VERSION "HNNBNNNYNNNNNNNNNNNNNNNNNNNNNNNNNNNNNNNNNN/4/%%%/4/'%**4NNN///"

NS_ :

BS_:

BU_: Airbag Allrad_Haldex BAP_Tester DCC_Gen3 EBKV_MQBW ESC_MQBW Gateway_Max Lenkhilfe_REPS

BO_ 333 ACC_18: 32 Gateway_Max
 SG_ ACC_18_CRC : 0|8@1+ (1,0) [0|255] ""  ESC_MQBW
 SG_ ACC_18_BZ : 8|4@1+ (1,0) [0|15] ""  ESC_MQBW
 SG_ ACC_limitierte_Anfahrdyn : 12|1@1+ (1.0,0.0) [0.0|1] ""  Vector__XXX
 SG_ ACC_nachtr_Stopp_Anf : 13|1@1+ (1.0,0.0) [0.0|1] ""  Vector__XXX
 SG_ ACC_DynErhoehung : 14|1@1+ (1.0,0.0) [0.0|1] ""  Vector__XXX
 SG_ ACC_Freilaufstrategie_TSK : 15|1@1+ (1.0,0.0) [0.0|1] ""  Vector__XXX
 SG_ ACC_zul_Regelabw_unten : 16|6@1+ (0.024,0) [0.000|1.512] "Unit_MeterPerSeconSquar"  Vector__XXX
 SG_ ACC_StartStopp_Info : 22|2@1+ (1.0,0.0) [0.0|3] ""  Vector__XXX
 SG_ ACC_Sollbeschleunigung_02 : 24|11@1+ (0.005,-7.22) [-7.220|3.005] "Unit_MeterPerSeconSquar"  Vector__XXX
 SG_ ACC_zul_Regelabw_oben : 35|5@1+ (0.0625,0) [0.0000|1.9375] "Unit_MeterPerSeconSquar"  Vector__XXX
 SG_ ACC_neg_Sollbeschl_Grad_02 : 40|8@1+ (0.05,0) [0.00|12.75] "Unit_MeterPerCubicSecon"  Vector__XXX
 SG_ ACC_pos_Sollbeschl_Grad_02 : 48|8@1+ (0.05,0) [0.00|12.75] "Unit_MeterPerCubicSecon"  Vector__XXX
 SG_ ACC_Anfahren : 56|1@1+ (1.0,0.0) [0.0|1] ""  Vector__XXX
 SG_ ACC_Anhalten : 57|1@1+ (1.0,0.0) [0.0|1] ""  Vector__XXX
 SG_ ACC_Typ : 58|2@1+ (1.0,0.0) [0.0|3] ""  Vector__XXX
 SG_ ACC_Status_ACC : 60|3@1+ (1.0,0.0) [0.0|7] ""  Airbag,ESC_MQBW
 SG_ ACC_Minimale_Bremsung : 63|1@1+ (1.0,0.0) [0.0|1] ""  Vector__XXX
 SG_ ACC_Anhalteweg : 64|11@1+ (0.01,0) [0.00|20.45] "Unit_Meter"  ESC_MQBW
 SG_ ACC_Boost : 75|1@1+ (1.0,0.0) [0.0|1] ""  Vector__XXX
 SG_ ACC_Freilauf_Anf : 76|1@1+ (1.0,0.0) [0.0|1] ""  Vector__XXX
 SG_ ACC_Anforderung_HMS : 77|3@1+ (1.0,0.0) [0.0|7] ""  ESC_MQBW
 SG_ ACC_Folgebeschl : 80|8@1+ (0.03,-4.6) [-4.60|2.99] "Unit_MeterPerSeconSquar"  Vector__XXX
 SG_ ACC_Freilauf_Info : 88|2@1+ (1.0,0.0) [0.0|3] ""  Vector__XXX
 SG_ ACC_Tempolimitassistent_Ein : 90|1@1+ (1.0,0.0) [0.0|1] ""  Vector__XXX
 SG_ ACC_FoD_Status : 91|2@1+ (1.0,0.0) [0.0|3] ""  Vector__XXX
 SG_ ACC_Blindheit_erkannt : 93|1@1+ (1.0,0.0) [0.0|1] ""  Vector__XXX
 SG_ ACC_Verkehrssinn : 94|2@1+ (1.0,0.0) [0.0|3] ""  Vector__XXX
 SG_ ACC_relev_Nichtverfuegbarkeit : 96|1@1+ (1.0,0.0) [0.0|1] ""  Vector__XXX
 SG_ ACC_relevanter_Fehler : 97|1@1+ (1.0,0.0) [0.0|1] ""  Vector__XXX
 SG_ ACC_TA_Kurve_Abstand : 98|6@1+ (5,0) [0|300] "Unit_Meter"  Vector__XXX
 SG_ ACC_TA_Kurve_vDelta : 104|4@1+ (5,0) [0|50] "Unit_KiloMeterPerHour"  Vector__XXX
 SG_ RDR_VBEG_Anforderung : 108|5@1+ (1,4) [5|35] "Unit_KiloMeterPerHour"  Vector__XXX
 SG_ ACC_Abbiegewunsch : 113|2@1+ (1.0,0.0) [0.0|3] ""  Vector__XXX
 SG_ ACC_Abbiegewunsch_Abstand : 115|9@1+ (1,0) [0|510] "Unit_Meter"  Vector__XXX
 SG_ MPPmod_1_Segment : 208|6@1+ (1,0) [2|63] ""  Vector__XXX
 SG_ MPPmod_2_Segment : 214|6@1+ (1,0) [2|63] ""  Vector__XXX
 SG_ MPPmod_3_Segment : 220|6@1+ (1,0) [2|63] ""  Vector__XXX
 SG_ MPPmod_4_Segment : 226|6@1+ (1,0) [2|63] ""  Vector__XXX
 SG_ vESC_Verz_Anf : 232|4@1+ (0.5,0) [0.0|3.5] "Unit_MeterPerSeconSquar"  Vector__XXX
 SG_ RDR_v_ueber_Grund : 236|12@1+ (0.1,0) [0.0|409.0] "Unit_KiloMeterPerHour"  ESC_MQBW
 SG_ RDR_v_ueber_Grund_Genauigkeit : 248|6@1+ (0.1,0) [0.0|6.0] "Unit_KiloMeterPerHour"  ESC_MQBW
 SG_ RDR_v_ueber_Grund_Fahrtrichtung : 254|2@1+ (1.0,0.0) [0.0|3] ""  ESC_MQBW

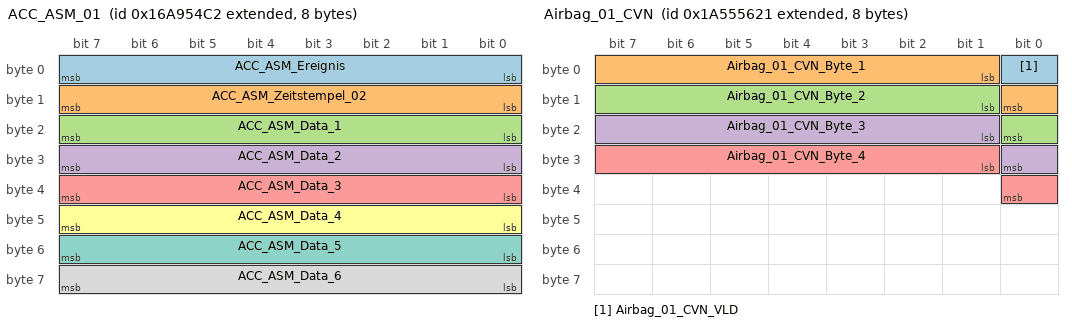
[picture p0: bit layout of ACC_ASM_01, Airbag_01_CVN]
BO_ 2527679682 ACC_ASM_01: 8 Gateway_Max
 SG_ ACC_ASM_Ereignis : 0|8@1+ (1,0) [1|254] ""  Airbag
 SG_ ACC_ASM_Zeitstempel_02 : 8|8@1+ (0.04,0) [0.00|10.16] "Unit_Secon"  Airbag
 SG_ ACC_ASM_Data_1 : 16|8@1+ (1,0) [0|255] ""  Airbag
 SG_ ACC_ASM_Data_2 : 24|8@1+ (1,0) [0|255] ""  Airbag
 SG_ ACC_ASM_Data_3 : 32|8@1+ (1,0) [0|255] ""  Airbag
 SG_ ACC_ASM_Data_4 : 40|8@1+ (1,0) [0|255] ""  Airbag
 SG_ ACC_ASM_Data_5 : 48|8@1+ (1,0) [0|255] ""  Airbag
 SG_ ACC_ASM_Data_6 : 56|8@1+ (1,0) [0|255] ""  Airbag

BO_ 64 Airbag_01: 8 Airbag
 SG_ Airbag_01_CRC : 0|8@1+ (1,0) [0|255] ""  ESC_MQBW,Gateway_Max
 SG_ Airbag_01_BZ : 8|4@1+ (1,0) [0|15] ""  ESC_MQBW,Gateway_Max
 SG_ AB_RGS_Anst : 12|4@1+ (1.0,0.0) [0.0|15] ""  Gateway_Max
 SG_ AB_Front_Crash : 16|1@1+ (1.0,0.0) [0.0|1] ""  ESC_MQBW,Gateway_Max
 SG_ AB_Heck_Crash : 17|1@1+ (1.0,0.0) [0.0|1] ""  ESC_MQBW,Gateway_Max
 SG_ AB_SF_Crash : 18|1@1+ (1.0,0.0) [0.0|1] ""  ESC_MQBW,Gateway_Max
 SG_ AB_SB_Crash : 19|1@1+ (1.0,0.0) [0.0|1] ""  ESC_MQBW,Gateway_Max
 SG_ AB_Rollover_Crash : 20|1@1+ (1.0,0.0) [0.0|1] ""  ESC_MQBW,Gateway_Max
 SG_ AB_Crash_Int : 21|3@1+ (1.0,0.0) [0.0|7] ""  EBKV_MQBW,ESC_MQBW,Gateway_Max
 SG_ AB_Lampe : 24|1@1+ (1.0,0.0) [0.0|1] ""  Gateway_Max
 SG_ AB_Deaktiviert : 25|1@1+ (1.0,0.0) [0.0|1] ""  Gateway_Max
 SG_ AB_VB_deaktiviert : 26|1@1+ (1.0,0.0) [0.0|1] ""  Gateway_Max
 SG_ AB_Systemfehler : 27|1@1+ (1.0,0.0) [0.0|1] ""  Gateway_Max
 SG_ AB_Diagnose : 28|1@1+ (1.0,0.0) [0.0|1] ""  Gateway_Max
 SG_ AB_Stellgliedtest : 29|1@1+ (1.0,0.0) [0.0|1] ""  Gateway_Max,Lenkhilfe_REPS
 SG_ AB_Erh_Auf_VB : 30|2@1+ (1.0,0.0) [0.0|3] ""  Gateway_Max
 SG_ AB_Gurtwarn_VF : 32|1@1+ (1.0,0.0) [0.0|1] ""  Gateway_Max
 SG_ AB_Gurtwarn_VB : 33|1@1+ (1.0,0.0) [0.0|1] ""  Gateway_Max
 SG_ AB_Anzeige_Fussg : 34|2@1+ (1.0,0.0) [0.0|3] ""  Gateway_Max
 SG_ AB_Texte_AKS : 36|2@1+ (1.0,0.0) [0.0|3] ""  Gateway_Max
 SG_ AB_PAO_Leuchte_Anf : 38|1@1+ (1.0,0.0) [0.0|1] ""  Gateway_Max
 SG_ AB_MKB_gueltig : 39|1@1+ (1.0,0.0) [0.0|1] ""  Gateway_Max
 SG_ AB_MKB_Anforderung : 40|1@1+ (1.0,0.0) [0.0|1] ""  ESC_MQBW,Gateway_Max
 SG_ AB_Versorgungsspannung : 41|1@1+ (1.0,0.0) [0.0|1] ""  Gateway_Max
 SG_ AB_Deaktivierung_HV : 42|3@1+ (1.0,0.0) [0.0|7] ""  Gateway_Max
 SG_ AB_EDR_Trigger : 45|2@1+ (1.0,0.0) [0.0|3] ""  Gateway_Max
 SG_ AB_Belegung_VF : 47|2@1+ (1.0,0.0) [0.0|3] ""  Gateway_Max
 SG_ AB_Gurtschloss_FA_ext : 49|3@1+ (1.0,0.0) [0.0|7] ""  ESC_MQBW,Gateway_Max
 SG_ AB_Gurtschloss_FA_ext_aktiv : 52|1@1+ (1.0,0.0) [0.0|1] ""  Gateway_Max
 SG_ AB_eCS_Error : 53|1@1+ (1.0,0.0) [0.0|1] ""  Gateway_Max
 SG_ ASM_Masterzeit_02 : 56|8@1+ (0.04,0) [0.00|10.16] "Unit_Secon"  ESC_MQBW,Gateway_Max,Lenkhilfe_REPS

BO_ 2589283872 Airbag_01_CALID: 16 Airbag
 SG_ Airbag_01_CALID_Index_01 : 0|8@1+ (1,0) [0|255] "Unit_None"  ESC_MQBW
 SG_ Airbag_01_CALID_Index_02 : 8|8@1+ (1,0) [0|255] "Unit_None"  ESC_MQBW
 SG_ Airbag_01_CALID_Index_03 : 16|8@1+ (1,0) [0|255] "Unit_None"  ESC_MQBW
 SG_ Airbag_01_CALID_Index_04 : 24|8@1+ (1,0) [0|255] "Unit_None"  ESC_MQBW
 SG_ Airbag_01_CALID_Index_05 : 32|8@1+ (1,0) [0|255] "Unit_None"  ESC_MQBW
 SG_ Airbag_01_CALID_Index_06 : 40|8@1+ (1,0) [0|255] "Unit_None"  ESC_MQBW
 SG_ Airbag_01_CALID_Index_07 : 48|8@1+ (1,0) [0|255] "Unit_None"  ESC_MQBW
 SG_ Airbag_01_CALID_Index_08 : 56|8@1+ (1,0) [0|255] "Unit_None"  ESC_MQBW
 SG_ Airbag_01_CALID_Index_09 : 64|8@1+ (1,0) [0|255] "Unit_None"  ESC_MQBW
 SG_ Airbag_01_CALID_Index_10 : 72|8@1+ (1,0) [0|255] "Unit_None"  ESC_MQBW
 SG_ Airbag_01_CALID_Index_11 : 80|8@1+ (1,0) [0|255] "Unit_None"  ESC_MQBW
 SG_ Airbag_01_CALID_Index_12 : 88|8@1+ (1,0) [0|255] "Unit_None"  ESC_MQBW
 SG_ Airbag_01_CALID_Index_13 : 96|8@1+ (1,0) [0|255] "Unit_None"  ESC_MQBW
 SG_ Airbag_01_CALID_Index_14 : 104|8@1+ (1,0) [0|255] "Unit_None"  ESC_MQBW
 SG_ Airbag_01_CALID_Index_15 : 112|8@1+ (1,0) [0|255] "Unit_None"  ESC_MQBW
 SG_ Airbag_01_CALID_Index_16 : 120|8@1+ (1,0) [0|255] "Unit_None"  ESC_MQBW

BO_ 2589283873 Airbag_01_CVN: 8 Airbag
 SG_ Airbag_01_CVN_VLD : 0|1@1+ (1.0,0.0) [0.0|1] ""  ESC_MQBW
 SG_ Airbag_01_CVN_Byte_1 : 1|8@1+ (1,0) [0|255] "Unit_None"  ESC_MQBW
 SG_ Airbag_01_CVN_Byte_2 : 9|8@1+ (1,0) [0|255] "Unit_None"  ESC_MQBW
 SG_ Airbag_01_CVN_Byte_3 : 17|8@1+ (1,0) [0|255] "Unit_None"  ESC_MQBW
 SG_ Airbag_01_CVN_Byte_4 : 25|8@1+ (1,0) [0|255] "Unit_None"  ESC_MQBW

BO_ 1312 Airbag_02: 8 Airbag
 SG_ Airbag_02_CRC : 0|8@1+ (1,0) [0|255] ""  ESC_MQBW,Gateway_Max
 SG_ Airbag_02_BZ : 8|4@1+ (1,0) [0|15] ""  ESC_MQBW,Gateway_Max
 SG_ LoGeWa_Event_Kombiwarnung : 12|4@1+ (1.0,0.0) [0.0|15] ""  Gateway_Max
 SG_ AB_Anforderung_eCall : 16|1@1+ (1.0,0.0) [0.0|1] ""  Gateway_Max
 SG_ AB_Anprall_Seite_Beifahrer : 17|1@1+ (1.0,0.0) [0.0|1] ""  Gateway_Max
 SG_ AB_Anprall_Rollover : 18|1@1+ (1.0,0.0) [0.0|1] ""  Gateway_Max
 SG_ AB_Anprall_FGS : 19|1@1+ (1.0,0.0) [0.0|1] ""  Gateway_Max
 SG_ AB_Anprall_Front_Beifahrer : 20|1@1+ (1.0,0.0) [0.0|1] ""  Gateway_Max
 SG_ AB_Anprall_Front_Fahrer : 21|1@1+ (1.0,0.0) [0.0|1] ""  Gateway_Max
 SG_ AB_Anprall_Heck_Beifahrer : 22|1@1+ (1.0,0.0) [0.0|1] ""  Gateway_Max
 SG_ AB_Anprall_Heck_Fahrer : 23|1@1+ (1.0,0.0) [0.0|1] ""  Gateway_Max
 SG_ AB_Wickelklappung_Reihe2_MI : 24|2@1+ (1.0,0.0) [0.0|3] ""  Gateway_Max
 SG_ AB_Belegung_VB : 26|2@1+ (1.0,0.0) [0.0|3] ""  Gateway_Max
 SG_ AB_Abschaltanf_SIH_BF : 28|1@1+ (1.0,0.0) [0.0|1] ""  Gateway_Max
 SG_ AB_Anprall_Seite_Fahrer : 29|1@1+ (1.0,0.0) [0.0|1] ""  Gateway_Max
 SG_ SC_PAO_Schriftzug_Anf : 30|2@1+ (1.0,0.0) [0.0|3] ""  Gateway_Max
 SG_ SC_PAO_ON_Anf : 32|2@1+ (1.0,0.0) [0.0|3] ""  Gateway_Max
 SG_ SC_PAO_OFF_Anf : 34|2@1+ (1.0,0.0) [0.0|3] ""  Gateway_Max
 SG_ AB_Crashschwere : 36|3@1+ (1.0,0.0) [0.0|7] ""  Gateway_Max
 SG_ AB_Anforderung_USM : 39|1@1+ (1.0,0.0) [0.0|1] ""  Gateway_Max
 SG_ AB_Gurtschloss_FA : 40|2@1+ (1.0,0.0) [0.0|3] ""  ESC_MQBW,Gateway_Max
 SG_ AB_Gurtschloss_BF : 42|2@1+ (1.0,0.0) [0.0|3] ""  Gateway_Max
 SG_ AB_Gurtschloss_Reihe2_FA : 44|2@1+ (1.0,0.0) [0.0|3] ""  Gateway_Max
 SG_ AB_Gurtschloss_Reihe2_MI : 46|2@1+ (1.0,0.0) [0.0|3] ""  Gateway_Max
 SG_ AB_Gurtschloss_Reihe2_BF : 48|2@1+ (1.0,0.0) [0.0|3] ""  Gateway_Max
 SG_ AB_Gurtschloss_Reihe3_FA : 50|2@1+ (1.0,0.0) [0.0|3] ""  Gateway_Max
 SG_ AB_Gurtschloss_Reihe3_MI : 52|2@1+ (1.0,0.0) [0.0|3] ""  Gateway_Max
 SG_ AB_Gurtschloss_Reihe3_BF : 54|2@1+ (1.0,0.0) [0.0|3] ""  Gateway_Max
 SG_ AB_Sitzpos_Sens_FA : 56|2@1+ (1.0,0.0) [0.0|3] ""  ESC_MQBW,Gateway_Max
 SG_ AB_Sitzpos_Sens_BF : 58|2@1+ (1.0,0.0) [0.0|3] ""  Gateway_Max
 SG_ AB_Wickelklappung_Reihe2_BF : 60|2@1+ (1.0,0.0) [0.0|3] ""  Gateway_Max
 SG_ AB_Wickelklappung_Reihe2_FA : 62|2@1+ (1.0,0.0) [0.0|3] ""  Gateway_Max

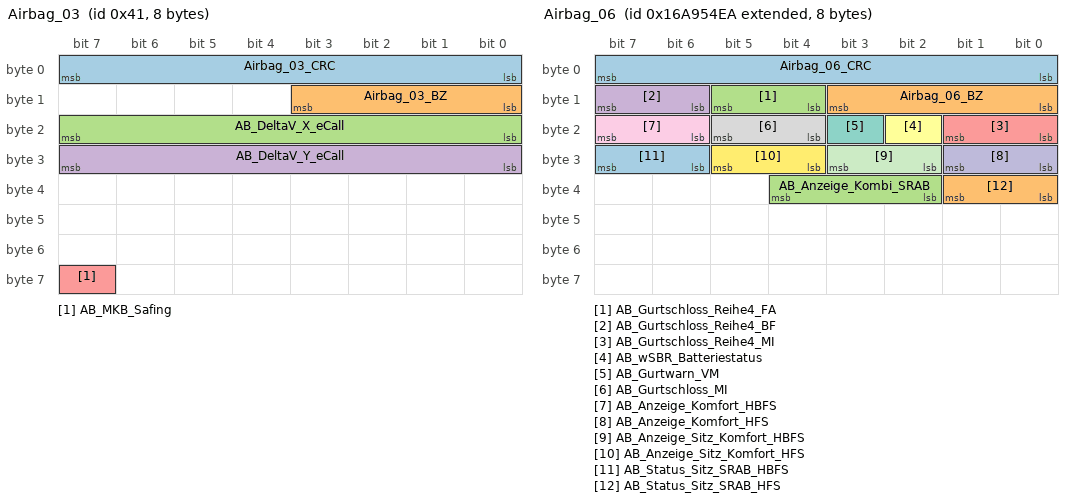
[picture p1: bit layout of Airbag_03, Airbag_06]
BO_ 65 Airbag_03: 8 Airbag
 SG_ Airbag_03_CRC : 0|8@1+ (1,0) [0|255] ""  ESC_MQBW,Gateway_Max
 SG_ Airbag_03_BZ : 8|4@1+ (1,0) [0|15] ""  ESC_MQBW,Gateway_Max
 SG_ AB_DeltaV_X_eCall : 16|8@1+ (1,-128) [-126|126] "Unit_KiloMeterPerHour"  Gateway_Max
 SG_ AB_DeltaV_Y_eCall : 24|8@1+ (1,-128) [-126|126] "Unit_KiloMeterPerHour"  Gateway_Max
 SG_ AB_MKB_Safing : 63|1@1+ (1.0,0.0) [0.0|1] ""  ESC_MQBW,Gateway_Max

BO_ 1349 Airbag_04: 8 Airbag
 SG_ Airbag_04_CRC : 0|8@1+ (1,0) [0|255] ""  Gateway_Max
 SG_ Airbag_04_BZ : 8|4@1+ (1,0) [0|15] ""  Gateway_Max
 SG_ AB_Anprall_Front : 12|1@1+ (1.0,0.0) [0.0|1] ""  Gateway_Max
 SG_ AB_Anprall_Heck : 13|1@1+ (1.0,0.0) [0.0|1] ""  Gateway_Max
 SG_ AB_Gurtwarn_Reihe4_FA : 14|2@1+ (1.0,0.0) [0.0|3] ""  Gateway_Max
 SG_ AB_Gurtwarn_Reihe4_BF : 16|2@1+ (1.0,0.0) [0.0|3] ""  Gateway_Max
 SG_ AB_Gurtwarn_Reihe4_MI : 18|2@1+ (1.0,0.0) [0.0|3] ""  Gateway_Max
 SG_ AB_Gurtwarn_Reihe2_FA : 20|2@1+ (1.0,0.0) [0.0|3] ""  Gateway_Max
 SG_ AB_Gurtwarn_Reihe2_BF : 22|2@1+ (1.0,0.0) [0.0|3] ""  Gateway_Max
 SG_ AbstWarn_MV_FAS_Fkt_Status : 24|2@1+ (1.0,0.0) [0.0|3] ""  Gateway_Max
 SG_ WarnBrems_Charisma_Status : 26|2@1+ (1.0,0.0) [0.0|3] ""  Gateway_Max
 SG_ WarnBrems_Charisma_FahrPr : 28|4@1+ (1.0,0.0) [0.0|15] ""  Gateway_Max
 SG_ AB_Gurtwarn_Reihe2_MI : 32|2@1+ (1.0,0.0) [0.0|3] ""  Gateway_Max
 SG_ AB_Gurtwarn_Reihe3_FA : 34|2@1+ (1.0,0.0) [0.0|3] ""  Gateway_Max
 SG_ AB_Gurtwarn_Reihe3_MI : 36|2@1+ (1.0,0.0) [0.0|3] ""  Gateway_Max
 SG_ AB_Gurtwarn_Reihe3_BF : 38|2@1+ (1.0,0.0) [0.0|3] ""  Gateway_Max
 SG_ LGI_FAS_Fkt_Status : 40|2@1+ (1.0,0.0) [0.0|3] ""  Gateway_Max
 SG_ PreCrash_FAS_Fkt_Status : 42|3@1+ (1.0,0.0) [0.0|7] ""  Gateway_Max
 SG_ AB_Belegung_VF_ext : 45|3@1+ (1.0,0.0) [0.0|7] ""  Gateway_Max
 SG_ AB_SBR_hinten_verbau : 48|2@1+ (1.0,0.0) [0.0|3] ""  Gateway_Max
 SG_ AB_Belegung_VF_ext_aktiv : 50|1@1+ (1.0,0.0) [0.0|1] ""  Gateway_Max
 SG_ AWV_Einstellung_System_ASG : 51|1@1+ (1.0,0.0) [0.0|1] ""  Gateway_Max
 SG_ AWV_Einstellung_Warnung_ASG : 52|3@1+ (1.0,0.0) [0.0|7] ""  Gateway_Max
 SG_ SC_PreSense_Modus_Warnung_NV : 55|3@1+ (1.0,0.0) [0.0|7] ""  Gateway_Max
 SG_ SC_PreSense_Modus_Warnung_MV : 58|3@1+ (1.0,0.0) [0.0|7] ""  Gateway_Max
 SG_ SC_PreSense_Modus_System_MV : 61|1@1+ (1.0,0.0) [0.0|1] ""  Gateway_Max
 SG_ SC_PreSense_Modus_System_NV : 62|1@1+ (1.0,0.0) [0.0|1] ""  Gateway_Max
 SG_ SC_PreSense_Modus_System_KAS : 63|1@1+ (1.0,0.0) [0.0|1] ""  Gateway_Max

BO_ 2527679722 Airbag_06: 8 Airbag
 SG_ Airbag_06_CRC : 0|8@1+ (1,0) [0|255] ""  Gateway_Max
 SG_ Airbag_06_BZ : 8|4@1+ (1,0) [0|15] ""  Gateway_Max
 SG_ AB_Gurtschloss_Reihe4_FA : 12|2@1+ (1.0,0.0) [0.0|3] ""  Gateway_Max
 SG_ AB_Gurtschloss_Reihe4_BF : 14|2@1+ (1.0,0.0) [0.0|3] ""  Gateway_Max
 SG_ AB_Gurtschloss_Reihe4_MI : 16|2@1+ (1.0,0.0) [0.0|3] ""  Gateway_Max
 SG_ AB_wSBR_Batteriestatus : 18|1@1+ (1.0,0.0) [0.0|1] ""  Gateway_Max
 SG_ AB_Gurtwarn_VM : 19|1@1+ (1.0,0.0) [0.0|1] ""  Gateway_Max
 SG_ AB_Gurtschloss_MI : 20|2@1+ (1.0,0.0) [0.0|3] ""  Gateway_Max
 SG_ AB_Anzeige_Komfort_HBFS : 22|2@1+ (1.0,0.0) [0.0|3] ""  Gateway_Max
 SG_ AB_Anzeige_Komfort_HFS : 24|2@1+ (1.0,0.0) [0.0|3] ""  Gateway_Max
 SG_ AB_Anzeige_Sitz_Komfort_HBFS : 26|2@1+ (1.0,0.0) [0.0|3] ""  Gateway_Max
 SG_ AB_Anzeige_Sitz_Komfort_HFS : 28|2@1+ (1.0,0.0) [0.0|3] ""  Gateway_Max
 SG_ AB_Status_Sitz_SRAB_HBFS : 30|2@1+ (1.0,0.0) [0.0|3] ""  Gateway_Max
 SG_ AB_Status_Sitz_SRAB_HFS : 32|2@1+ (1.0,0.0) [0.0|3] ""  Gateway_Max
 SG_ AB_Anzeige_Kombi_SRAB : 34|3@1+ (1.0,0.0) [0.0|7] ""  Gateway_Max

BO_ 63 Airbag_07: 16 Airbag
 SG_ Airbag_07_CRC : 0|8@1+ (1,0) [0|255] ""  Gateway_Max
 SG_ Airbag_07_BZ : 8|4@1+ (1,0) [0|15] ""  Gateway_Max
 SG_ AB_PAO_off_ANF_Auth : 12|2@1+ (1.0,0.0) [0.0|3] ""  Gateway_Max
 SG_ AB_PAO_on_ANF_Auth : 14|2@1+ (1.0,0.0) [0.0|3] ""  Gateway_Max
 SG_ AB_Crash_Int_Auth : 16|3@1+ (1.0,0.0) [0.0|7] ""  Gateway_Max
 SG_ AB_Front_Crash_Auth : 19|1@1+ (1.0,0.0) [0.0|1] ""  Gateway_Max
 SG_ AB_Heck_Crash_Auth : 20|1@1+ (1.0,0.0) [0.0|1] ""  Gateway_Max
 SG_ AB_SF_Crash_Auth : 21|1@1+ (1.0,0.0) [0.0|1] ""  Gateway_Max
 SG_ AB_SB_Crash_Auth : 22|1@1+ (1.0,0.0) [0.0|1] ""  Gateway_Max
 SG_ AB_Rollover_Crash_Auth : 23|1@1+ (1.0,0.0) [0.0|1] ""  Gateway_Max
 SG_ AB_MKB_Anforderung_Auth : 24|1@1+ (1.0,0.0) [0.0|1] ""  Gateway_Max
 SG_ AB_MKB_gueltig_Auth : 25|1@1+ (1.0,0.0) [0.0|1] ""  Gateway_Max
 SG_ AB_VRU_Crash : 26|1@1+ (1.0,0.0) [0.0|1] ""  Gateway_Max
 SG_ AB_Anforderung_USM_Auth : 27|1@1+ (1.0,0.0) [0.0|1] ""  Gateway_Max
 SG_ SOK_Airbag_07_Signatur : 96|32@1+ (1,0) [0|4294967295] ""  Gateway_Max

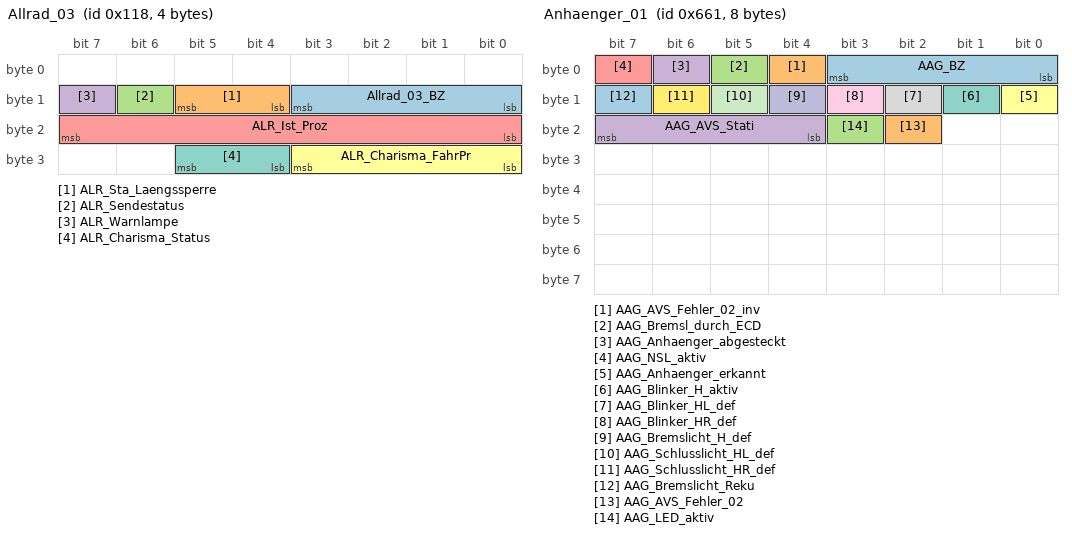
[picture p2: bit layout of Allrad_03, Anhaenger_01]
BO_ 280 Allrad_03: 4 Allrad_Haldex
 SG_ Allrad_03_BZ : 8|4@1+ (1,0) [0|15] ""  ESC_MQBW,Gateway_Max
 SG_ ALR_Sta_Laengssperre : 12|2@1+ (1.0,0.0) [0.0|3] ""  ESC_MQBW,Gateway_Max
 SG_ ALR_Sendestatus : 14|1@1+ (1.0,0.0) [0.0|1] ""  ESC_MQBW,Gateway_Max
 SG_ ALR_Warnlampe : 15|1@1+ (1.0,0.0) [0.0|1] ""  Gateway_Max
 SG_ ALR_Ist_Proz : 16|8@1+ (0.4,0) [0.0|100.0] "Unit_PerCent"  ESC_MQBW,Gateway_Max,Lenkhilfe_REPS
 SG_ ALR_Charisma_FahrPr : 24|4@1+ (1.0,0.0) [0.0|15] ""  Gateway_Max
 SG_ ALR_Charisma_Status : 28|2@1+ (1.0,0.0) [0.0|3] ""  Gateway_Max

BO_ 308 Allrad_04: 8 Vector__XXX
 SG_ ALR_gMeter_ax : 44|10@1+ (0.003,-1.5) [-1.500|1.500] "Unit_ForceOfGravi"  Gateway_Max
 SG_ ALR_gMeter_ay : 54|10@1+ (0.003,-1.5) [-1.500|1.500] "Unit_ForceOfGravi"  Gateway_Max

BO_ 1633 Anhaenger_01: 8 Gateway_Max
 SG_ AAG_BZ : 0|4@1+ (1,0) [0|15] ""  Vector__XXX
 SG_ AAG_AVS_Fehler_02_inv : 4|1@1+ (1.0,0.0) [0.0|1] ""  Vector__XXX
 SG_ AAG_Bremsl_durch_ECD : 5|1@1+ (1.0,0.0) [0.0|1] ""  ESC_MQBW
 SG_ AAG_Anhaenger_abgesteckt : 6|1@1+ (1.0,0.0) [0.0|1] ""  Vector__XXX
 SG_ AAG_NSL_aktiv : 7|1@1+ (1.0,0.0) [0.0|1] ""  Vector__XXX
 SG_ AAG_Anhaenger_erkannt : 8|1@1+ (1.0,0.0) [0.0|1] ""  Allrad_Haldex,ESC_MQBW
 SG_ AAG_Blinker_H_aktiv : 9|1@1+ (1.0,0.0) [0.0|1] ""  Vector__XXX
 SG_ AAG_Blinker_HL_def : 10|1@1+ (1.0,0.0) [0.0|1] ""  Vector__XXX
 SG_ AAG_Blinker_HR_def : 11|1@1+ (1.0,0.0) [0.0|1] ""  Vector__XXX
 SG_ AAG_Bremslicht_H_def : 12|1@1+ (1.0,0.0) [0.0|1] ""  ESC_MQBW
 SG_ AAG_Schlusslicht_HL_def : 13|1@1+ (1.0,0.0) [0.0|1] ""  Vector__XXX
 SG_ AAG_Schlusslicht_HR_def : 14|1@1+ (1.0,0.0) [0.0|1] ""  Vector__XXX
 SG_ AAG_Bremslicht_Reku : 15|1@1+ (1.0,0.0) [0.0|1] ""  Vector__XXX
 SG_ AAG_AVS_Fehler_02 : 18|1@1+ (1.0,0.0) [0.0|1] ""  Vector__XXX
 SG_ AAG_LED_aktiv : 19|1@1+ (1.0,0.0) [0.0|1] ""  Vector__XXX
 SG_ AAG_AVS_Stati : 20|4@1+ (1.0,0.0) [0.0|15] ""  Vector__XXX

BO_ 2527679661 AWV_02: 8 Gateway_Max
 SG_ WBA_Warnblinken : 0|2@1+ (1.0,0.0) [0.0|3] ""  Vector__XXX
 SG_ AWV_KA_Konfiguration : 2|1@1+ (1.0,0.0) [0.0|1] ""  Vector__XXX
 SG_ AWV_Warnung : 12|3@1+ (1.0,0.0) [0.0|7] ""  Airbag
 SG_ AWV_Texte_02 : 15|3@1+ (1.0,0.0) [0.0|7] ""  Airbag
 SG_ AWV_Warnlevel : 18|6@1+ (1.0,0.0) [0.0|63] ""  Vector__XXX
 SG_ AWV_Einstellung_System_FSG : 24|1@1+ (1.0,0.0) [0.0|1] ""  Vector__XXX
 SG_ AWV_Einstellung_Warnung_FSG : 25|3@1+ (1.0,0.0) [0.0|7] ""  Vector__XXX
 SG_ AWV_Status_Anzeige : 28|2@1+ (1.0,0.0) [0.0|3] ""  Vector__XXX
 SG_ AWV_LED_Leiste : 30|2@1+ (1.0,0.0) [0.0|3] ""  Vector__XXX
 SG_ AWV_Priowarnung : 32|1@1+ (1.0,0.0) [0.0|1] ""  Vector__XXX
 SG_ AWV_AW_Abstand : 33|9@1+ (1,0) [0|508] "Unit_Meter"  Vector__XXX
 SG_ AWV_AW_Zeitluecke : 42|3@1+ (1.0,0.0) [0.0|7] ""  Vector__XXX
 SG_ AWV_AW_Texte : 45|3@1+ (1.0,0.0) [0.0|7] ""  Vector__XXX
 SG_ AWV_AW_Texte_Zusatzanzeige : 48|4@1+ (1.0,0.0) [0.0|15] ""  Vector__XXX
 SG_ AWV_KA_ObjektFront : 52|1@1+ (1.0,0.0) [0.0|1] ""  Vector__XXX
 SG_ AWV_Warnung_Richtung : 53|3@1+ (1.0,0.0) [0.0|7] ""  Vector__XXX
 SG_ AWV_Kamera_Objekt_ID : 56|8@1+ (1,0) [1|255] "Unit_None"  Vector__XXX

BO_ 219 AWV_03: 48 Gateway_Max
 SG_ AWV_03_CRC : 0|8@1+ (1,0) [0|255] ""  Airbag,ESC_MQBW
 SG_ AWV_03_BZ : 8|4@1+ (1,0) [0|15] ""  Airbag,ESC_MQBW
 SG_ PCF_Freigabe : 12|1@1+ (1.0,0.0) [0.0|1] ""  Airbag
 SG_ SDF_PSF_Objektstatus : 13|3@1+ (1.0,0.0) [0.0|7] ""  Airbag,ESC_MQBW
 SG_ SDF_PSF_CU_Status : 16|1@1+ (1.0,0.0) [0.0|1] ""  Airbag
 SG_ SDF_PSF_CW : 17|7@1+ (1,0) [0|100] ""  Airbag
 SG_ SDF_PSF_Fahrer_aktiv : 24|1@1+ (1.0,0.0) [0.0|1] ""  Vector__XXX
 SG_ SDF_PSF_Guete : 25|2@1+ (1.0,0.0) [0.0|3] ""  Airbag
 SG_ SDF_PSF_Kollisionsueberdeckung : 27|5@1+ (0.1,0) [0.1|2.8] "Unit_Meter"  Airbag
 SG_ SDF_PSF_Time_To_Collision : 32|8@1+ (0.01,0) [0.00|2.50] "Unit_Secon"  Vector__XXX
 SG_ SDF_PSF_v_rel : 40|8@1+ (0.4,0) [0.4|101.2] "Unit_MeterPerSecon"  Airbag
 SG_ AWV_Eingriff_Sendeart : 64|1@1+ (1.0,0.0) [0.0|1] ""  Airbag,ESC_MQBW,Lenkhilfe_REPS
 SG_ AWV_Verz_Freigabe : 65|1@1+ (1.0,0.0) [0.0|1] ""  Airbag,ESC_MQBW
 SG_ AWV_Verz_Anf : 66|10@1+ (0.024,-20.016) [-20.016|4.512] "Unit_MeterPerSeconSquar"  Airbag,ESC_MQBW
 SG_ AWV_Anf_Prefill : 76|1@1+ (1.0,0.0) [0.0|1] ""  Airbag,ESC_MQBW
 SG_ AWV_Ruckprofil : 77|3@1+ (1.0,0.0) [0.0|7] ""  Airbag,ESC_MQBW
 SG_ AWV_Time_to_collision : 80|8@1+ (0.01,0) [0.00|2.50] "Unit_Secon"  Airbag
 SG_ AWV_HBA_Param : 88|2@1+ (1.0,0.0) [0.0|3] ""  EBKV_MQBW,ESC_MQBW
 SG_ AWV_Verz_Anf_ASIL : 90|3@1+ (1.0,0.0) [0.0|7] ""  ESC_MQBW
 SG_ AWV_Time_to_brake : 93|7@1+ (10,0) [0|1240] "Unit_MilliSecon"  ESC_MQBW
 SG_ AWV_Zielobjekttyp : 100|4@1+ (1.0,0.0) [0.0|15] ""  Airbag,ESC_MQBW
 SG_ AWV_QFK_KruemmSoll : 104|15@1+ (0.0000067,0) [0E-7|0.2195389] "Unit_MeterInver"  Lenkhilfe_REPS
 SG_ AWV_QFK_KruemmSoll_VZ : 119|1@1+ (1.0,0.0) [0.0|1] ""  Lenkhilfe_REPS
 SG_ AWV_QFK_Spuerb : 120|8@1+ (0.4,0) [0.0|100.0] "Unit_PerCent"  Lenkhilfe_REPS
 SG_ AWV_QFK_AnfStat : 128|4@1+ (1.0,0.0) [0.0|15] ""  Airbag,Lenkhilfe_REPS
 SG_ AWV_QFK_Signal1 : 132|10@1+ (1,0) [0|1023] ""  Lenkhilfe_REPS
 SG_ AWV_QFK_Art1 : 142|3@1+ (1,0) [0|7] ""  Lenkhilfe_REPS
 SG_ AWV_QFK_Art2 : 145|3@1+ (1,0) [0|7] ""  Lenkhilfe_REPS
 SG_ AWV_QFK_Signal2 : 148|10@1+ (1,0) [0|1023] ""  Lenkhilfe_REPS
 SG_ AWV_Fahrerbremswunsch_erf : 158|1@1+ (1.0,0.0) [0.0|1] ""  ESC_MQBW
 SG_ AWV_Timestamp_TTC : 161|13@1+ (0.001,0) [0.000|8.190] "Unit_Secon"  Airbag
 SG_ AWV_QFK_KrSoll_VZ : 175|1@1+ (1.0,0.0) [0.0|1] ""  Lenkhilfe_REPS
 SG_ AWV_QFK_KrSoll : 176|16@1+ (0.0000067,0) [0E-7|0.4390778] "Unit_MeterInver"  Lenkhilfe_REPS
 SG_ AWV_Status_AWU : 192|4@1+ (1.0,0.0) [0.0|15] ""  Airbag
 SG_ SOK_AWV_03_Signatur : 336|48@1+ (1,0) [0|281474976710655] "Unit_None"  Vector__XXX

BO_ 2536711680 BAP_Brake_ASG_01: 8 Gateway_Max
 SG_ BAP_Brake_ASG_01_Header : 0|8@1+ (1.0,0.0) [0.0|255] ""  ESC_MQBW

BO_ 2536711696 BAP_Brake_FSG_01: 8 ESC_MQBW
 SG_ BAP_Brake_FSG_01_Header : 0|8@1+ (1.0,0.0) [0.0|255] ""  Gateway_Max

BO_ 2536767264 BAP_Debug_Cmd: 8 BAP_Tester
 SG_ BAP_Debug_Cmd : 0|16@1+ (1.0,0.0) [0.0|65535] ""  ESC_MQBW

BO_ 2536767280 BAP_Debug_Data: 8 ESC_MQBW
 SG_ BAP_Debug_Data : 0|64@1+ (1.0,0.0) [0.0|18446744073709551615] ""  BAP_Tester

BO_ 2536703744 BAP_RDK_ASG_01: 8 Gateway_Max
 SG_ BAP_RDK_ASG_01_Header : 0|8@1+ (1.0,0.0) [0.0|255] ""  ESC_MQBW

BO_ 2536703745 BAP_RDK_ASG_02: 8 Gateway_Max
 SG_ BAP_RDK_ASG_02_Header : 0|8@1+ (1.0,0.0) [0.0|255] ""  ESC_MQBW

BO_ 2536703760 BAP_RDK_FSG_01: 8 ESC_MQBW
 SG_ BAP_RDK_FSG_01_Header : 0|8@1+ (1.0,0.0) [0.0|255] ""  Gateway_Max

BO_ 1626 BCM_01: 8 Gateway_Max
 SG_ BCM_Bremsbelag_Sensor : 12|1@1+ (1.0,0.0) [0.0|1] ""  Vector__XXX
 SG_ BCM_Bremsfluessigkeit_Sensor : 13|1@1+ (1.0,0.0) [0.0|1] ""  Vector__XXX
 SG_ BCM1_Licht_Warn : 14|1@1+ (1.0,0.0) [0.0|1] ""  Vector__XXX
 SG_ BCM_Waschwasser_Sensor : 15|1@1+ (1.0,0.0) [0.0|1] ""  Vector__XXX
 SG_ BCM_Kuehlmittel_Sensor : 16|1@1+ (1.0,0.0) [0.0|1] ""  Vector__XXX
 SG_ BCM1_Kl_15_HW_erkannt : 17|1@1+ (1.0,0.0) [0.0|1] ""  Vector__XXX
 SG_ BCM1_Kl_15_Sig_HW_erkannt : 18|1@1+ (1.0,0.0) [0.0|1] ""  Vector__XXX
 SG_ BCM_Kuehlmittel_Sensor_02 : 19|1@1+ (1.0,0.0) [0.0|1] ""  Vector__XXX
 SG_ BCM1_Hinweis_Lichtnachlauf : 20|1@1+ (1.0,0.0) [0.0|1] ""  Vector__XXX
 SG_ BCM_Offroad_Taste : 21|1@1+ (1.0,0.0) [0.0|1] ""  ESC_MQBW
 SG_ BCM_Charisma_Taste2 : 22|1@1+ (1.0,0.0) [0.0|1] ""  Vector__XXX
 SG_ BCM_Hybrid_StSt_Taste_Fehler : 23|1@1+ (1.0,0.0) [0.0|1] ""  Vector__XXX
 SG_ BCM_Hybrid_StartStopp_Taste : 24|1@1+ (1.0,0.0) [0.0|1] ""  Vector__XXX
 SG_ BCM1_Warnblink_Taster : 25|1@1+ (1.0,0.0) [0.0|1] ""  Vector__XXX
 SG_ BCM1_Valet_Parking_Taster : 26|1@1+ (1.0,0.0) [0.0|1] ""  Vector__XXX
 SG_ BCM1_LDS_Stellung : 27|3@1+ (1.0,0.0) [0.0|7] ""  Vector__XXX
 SG_ BCM1_Rueckfahrlicht_Schalter : 30|1@1+ (1.0,0.0) [0.0|1] ""  Airbag,ESC_MQBW,Lenkhilfe_REPS
 SG_ BCM1_MH_Schalter : 31|1@1+ (1.0,0.0) [0.0|1] ""  Vector__XXX
 SG_ BCM1_MH_WIV_Schalter : 32|1@1+ (1.0,0.0) [0.0|1] ""  Vector__XXX
 SG_ BCM_Eco_Charisma_Taste : 33|1@1+ (1.0,0.0) [0.0|1] ""  Vector__XXX
 SG_ BCM1_NV_Taster : 34|1@1+ (1.0,0.0) [0.0|1] ""  Vector__XXX
 SG_ BCM1_AFS_Lampe : 35|1@1+ (1.0,0.0) [0.0|1] ""  Vector__XXX
 SG_ BCM1_Reisemodus_Texte : 36|2@1+ (1.0,0.0) [0.0|3] ""  Vector__XXX
 SG_ BCM1_Lichtwarn_Texte : 38|2@1+ (1.0,0.0) [0.0|3] ""  Vector__XXX
 SG_ Gong_TFL_Umschaltung : 40|1@1+ (1.0,0.0) [0.0|1] ""  Vector__XXX
 SG_ BCM_ValetTaster_Fkts_LED : 42|1@1+ (1.0,0.0) [0.0|1] ""  Vector__XXX
 SG_ LRH_Taster : 43|1@1+ (1.0,0.0) [0.0|1] ""  Vector__XXX
 SG_ APS_Tongeber_defekt : 44|1@1+ (1.0,0.0) [0.0|1] ""  Vector__XXX
 SG_ BCM1_EasyEntry_Status : 45|1@1+ (1.0,0.0) [0.0|1] ""  Vector__XXX
 SG_ BCM1_Lenksaeule_aktiv : 46|1@1+ (1.0,0.0) [0.0|1] ""  Vector__XXX
 SG_ BCM1_Spannungs_Anf : 47|2@1+ (1.0,0.0) [0.0|3] ""  Vector__XXX
 SG_ DWA_Alarmquelle : 49|5@1+ (1.0,0.0) [0.0|31] ""  Vector__XXX
 SG_ DWA_Einschraenkung : 54|1@1+ (1.0,0.0) [0.0|1] ""  Vector__XXX
 SG_ BCM_HBFS_EOE_aktiv : 56|1@1+ (1.0,0.0) [0.0|1] ""  Vector__XXX
 SG_ BCM_HFS_EOE_aktiv : 57|1@1+ (1.0,0.0) [0.0|1] ""  Vector__XXX
 SG_ BCM_Anf_AAW_MoLaWa : 58|2@1+ (1.0,0.0) [0.0|3] ""  Vector__XXX
 SG_ BCM_Handbremse_Hinweis : 60|1@1+ (1.0,0.0) [0.0|1] ""  Vector__XXX
 SG_ BCM_Waehlhebel_P_Hinweis : 61|1@1+ (1.0,0.0) [0.0|1] ""  Vector__XXX
 SG_ BCM1_Fahrlicht_Hinweis : 62|1@1+ (1.0,0.0) [0.0|1] ""  Vector__XXX
 SG_ BCM_HDF_betaetigt : 63|1@1+ (1.0,0.0) [0.0|1] ""  Vector__XXX

BO_ 2527679939 BDM_LiIon2: 8 Gateway_Max
 SG_ BDMs_LiIon2_CRC : 0|8@1+ (1,0) [0|255] ""  Lenkhilfe_REPS
 SG_ BDMs_LiIon2_BZ : 8|4@1+ (1,0) [0|15] ""  Lenkhilfe_REPS
 SG_ BDM_Kommunikationsbasis_2 : 12|1@1+ (1.0,0.0) [0.0|1] ""  Vector__XXX
 SG_ BDM_Kuehlung_Anf : 13|1@1+ (1.0,0.0) [0.0|1] ""  Vector__XXX
 SG_ BDMs_LiIon2_Dummy_2_6 : 14|2@1+ (1.0,0.0) [0.0|3] ""  Vector__XXX
 SG_ BDM_I_U_VorgabeZwang_2 : 16|1@1+ (1.0,0.0) [0.0|1] ""  Vector__XXX
 SG_ BDM_TE_Diagnose_2 : 17|1@1+ (1.0,0.0) [0.0|1] ""  Vector__XXX
 SG_ BDM_TE_Status_2 : 18|1@1+ (1.0,0.0) [0.0|1] ""  Vector__XXX
 SG_ BDM_ZellStatus_Index_2 : 19|4@1+ (1.0,0.0) [0.0|15] ""  Vector__XXX
 SG_ BDM_ZellStatus_Typ_2 : 23|3@1+ (1.0,0.0) [0.0|7] ""  Vector__XXX
 SG_ BDM_ZellStatus_Inhalt_2 : 26|12@1+ (1,0) [0|4095] ""  Vector__XXX
 SG_ BDM_ZellTechnologie_2 : 38|4@1+ (1.0,0.0) [0.0|15] ""  Vector__XXX
 SG_ BZE_ZwangGrund : 42|2@1+ (1.0,0.0) [0.0|3] ""  Vector__XXX
 SG_ BZE_Qe_Bereich_2 : 44|1@1+ (1.0,0.0) [0.0|1] ""  Vector__XXX
 SG_ BDM_LiIon_Status_2 : 45|3@1+ (1.0,0.0) [0.0|7] ""  Vector__XXX
 SG_ BDM_LiIon_Zellenanzahl_2 : 48|5@1+ (1,0) [1|31] ""  Vector__XXX
 SG_ BZE_Q_FuSi : 53|7@1+ (1,0) [0|120] "Unit_AmperHour"  Vector__XXX
 SG_ BZE_SOF_3Pol : 60|1@1+ (1.0,0.0) [0.0|1] ""  Lenkhilfe_REPS
 SG_ BDM_Variante : 61|2@1+ (1.0,0.0) [0.0|3] ""  Vector__XXX
 SG_ BDMs_LiIon2_Dummy_8_7 : 63|1@1+ (1.0,0.0) [0.0|1] ""  Vector__XXX

BO_ 869 BEM_05: 8 Gateway_Max
 SG_ BEM_UBDM : 0|8@1+ (0.05,5) [5.05|17.70] "Unit_Volt"  Vector__XXX
 SG_ NVEM_Ladefreigabe : 8|2@1+ (1.0,0.0) [0.0|3] ""  Vector__XXX
 SG_ NVEM_FMAus_Info : 10|2@1+ (1.0,0.0) [0.0|3] ""  Vector__XXX
 SG_ NVEM_PTC_Sollstufe : 12|2@1+ (1.0,0.0) [0.0|3] ""  Vector__XXX
 SG_ NVEM_P_Generator_Status : 15|1@1+ (1.0,0.0) [0.0|1] ""  Vector__XXX
 SG_ BEM_P_Generator : 16|8@1+ (50,0) [0|12700] "Unit_Watt"  ESC_MQBW
 SG_ BEM_n_LLA : 24|2@1+ (1.0,0.0) [0.0|3] ""  Vector__XXX
 SG_ NVEM_Abschaltstufe : 26|2@1+ (1.0,0.0) [0.0|3] ""  Vector__XXX
 SG_ BEM_Anf_KL : 29|1@1+ (1.0,0.0) [0.0|1] ""  Vector__XXX
 SG_ BEM_StartStopp_Info : 30|2@1+ (1.0,0.0) [0.0|3] ""  Vector__XXX
 SG_ BEM_DFM : 32|5@1+ (3.225,0.025) [0.025|100.000] ""  Vector__XXX
 SG_ BEM_EMLIN_ungueltig : 37|1@1+ (1.0,0.0) [0.0|1] ""  Vector__XXX
 SG_ BEM_Batt_Ab : 38|1@1+ (1.0,0.0) [0.0|1] ""  ESC_MQBW,Lenkhilfe_REPS
 SG_ NVEM_FMAus_I_Verbrauch : 39|5@1+ (5,0) [0|145] "Unit_Amper"  Vector__XXX
 SG_ NVEM_Freilauf_Info : 44|2@1+ (1.0,0.0) [0.0|3] ""  Vector__XXX
 SG_ NVEM_Red_KL : 46|2@1+ (1.0,0.0) [0.0|3] ""  Vector__XXX
 SG_ BEM_Segel_Info : 48|2@1+ (1.0,0.0) [0.0|3] ""  Vector__XXX
 SG_ BEM_HYB_DC_uSollLV : 50|6@1+ (0.1,10.6) [10.6|16.0] "Unit_Volt"  Vector__XXX
 SG_ BEM_HYB_DC_uMinLV : 56|8@1+ (0.1,0) [0.0|25.3] "Unit_Volt"  Vector__XXX

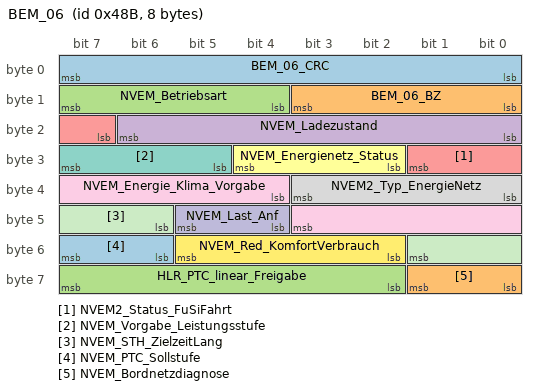
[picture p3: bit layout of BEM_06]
BO_ 1163 BEM_06: 8 Gateway_Max
 SG_ BEM_06_CRC : 0|8@1+ (1,0) [0|255] ""  EBKV_MQBW,ESC_MQBW,Lenkhilfe_REPS
 SG_ BEM_06_BZ : 8|4@1+ (1,0) [0|15] ""  EBKV_MQBW,ESC_MQBW,Lenkhilfe_REPS
 SG_ NVEM_Betriebsart : 12|4@1+ (1.0,0.0) [0.0|15] ""  Vector__XXX
 SG_ NVEM_Ladezustand : 16|7@1+ (1,0) [0|100] "Unit_PerCent"  Vector__XXX
 SG_ NVEM2_Status_FuSiFahrt : 23|3@1+ (1.0,0.0) [0.0|7] ""  Vector__XXX
 SG_ NVEM_Energienetz_Status : 26|3@1+ (1.0,0.0) [0.0|7] ""  ESC_MQBW
 SG_ NVEM_Vorgabe_Leistungsstufe : 29|3@1+ (1.0,0.0) [0.0|7] ""  EBKV_MQBW,ESC_MQBW,Lenkhilfe_REPS
 SG_ NVEM2_Typ_EnergieNetz : 32|4@1+ (1.0,0.0) [0.0|15] ""  Vector__XXX
 SG_ NVEM_Energie_Klima_Vorgabe : 36|8@1+ (10,0) [0|2530] "Unit_WattHour"  Vector__XXX
 SG_ NVEM_Last_Anf : 44|2@1+ (1.0,0.0) [0.0|3] ""  Vector__XXX
 SG_ NVEM_STH_ZielzeitLang : 46|4@1+ (10,0) [0|120] "Unit_Minut"  Vector__XXX
 SG_ NVEM_Red_KomfortVerbrauch : 50|4@1+ (1.0,0.0) [0.0|15] ""  Vector__XXX
 SG_ NVEM_PTC_Sollstufe : 54|2@1+ (1.0,0.0) [0.0|3] ""  Vector__XXX
 SG_ NVEM_Bordnetzdiagnose : 56|2@1+ (1.0,0.0) [0.0|3] ""  ESC_MQBW,Lenkhilfe_REPS
 SG_ HLR_PTC_linear_Freigabe : 58|6@1+ (50,0) [0|3100] "Unit_Watt"  Vector__XXX

CM_ "FCANFD1_V14.09F Generated by BusNet_NG_Produktiv 9.25.5";
CM_ BU_ Airbag "Airbag E3_Volumen";
CM_ BU_ Allrad_Haldex "Längssperre/Allrad MQBw_Baseline";
CM_ BU_ DCC_Gen3 "Dynamic Chassis Control - Geregelter Dämpfer MQBw_Baseline";
CM_ BU_ EBKV_MQBW "Elektronischer Bremskraftverstärker MQB48_W";
CM_ BU_ ESC_MQBW "Bremse MQB_48W";
CM_ BU_ Lenkhilfe_REPS "Elektromechanische Lenkhilfe MQB37(W) Baseline";

CM_ BO_ 280 "Allrad im MQB";
CM_ BO_ 308 "Botschaft exklusiv für LB83x - alte Haldex-Schnittstelle, nicht zur Weiterentwicklung verwenden!";
CM_ BO_ 1633 "ab MQB 7.2";
CM_ BO_ 869 "ab MQB";

CM_ SG_ 333 ACC_18_BZ "4bit Botschaftszähler, wird mit jeder Sendebotschaft inkrementiert";
CM_ SG_ 333 ACC_18_CRC "Für MLB:
Berechnung siehe Lastenheft 'Kommunikationsabsicherung für FlexRay und CAN'
Ab MQB und MLBevo:
Berechnung siehe Lastenheft 'End-to-End Kommunikationsabsicherung'

Endwerte siehe Begleitdokument 'S-PDU Kennungsfolgen'";
CM_ SG_ 333 ACC_Abbiegewunsch "Identifizierter Abbiegewunsch vom Fahrer";
CM_ SG_ 333 ACC_Abbiegewunsch_Abstand "Ort des identifizierten Abbiegewunsches vom Fahrer";
CM_ SG_ 333 ACC_Anfahren "Anforderung Anfahren";
CM_ SG_ 333 ACC_Anforderung_HMS "Bremsanforderung an den Haltemanager";
CM_ SG_ 333 ACC_Anhalten "Im Falle eines gesetzten Bits wird vom ACC ein Anhalten bis in den Stand gewünscht. Das Bit wird von ACC nur unterhalb einer appl. Geschwindigkeitsschwelle gesetzt. Notwendig für die ACCplus-Funktionalität. Nicht für Audi B8 relevant, jedoch im Vorgriff a";
CM_ SG_ 333 ACC_Anhalteweg "Verbleibender Weg bis zum Stillstand";
CM_ SG_ 333 ACC_Blindheit_erkannt "Blindheitserkennung";
CM_ SG_ 333 ACC_Boost "Aktivität der Boost-Funktion des ACC";
CM_ SG_ 333 ACC_DynErhoehung "Ansteuerung einer erhöhten Dynamik im Verzögerungsfall (vor allem beim Motormomentenabbau)";
CM_ SG_ 333 ACC_FoD_Status "Informiert den TSK und Kombi, ob die ACC-Funktion freigeschaltet ist oder nicht.";
CM_ SG_ 333 ACC_Folgebeschl "Sollbeschleunigung des ACC-Folgeregler";
CM_ SG_ 333 ACC_Freilauf_Anf "Freilauf-Anforderung durch Energo/ACC";
CM_ SG_ 333 ACC_Freilauf_Info "Freilauf-Freigabe durch Aktiven Teilnehmer Freilauf";
CM_ SG_ 333 ACC_Freilaufstrategie_TSK "Das Signal definiert im aktiven ACC - Betrieb, ob ein Freilauf direkt über das ACC angefordert wird oder ein Freilauf über den Triebstrangkoordinator (TSK) angefordert wird, falls das ACC den Freilauf freigibt.";
CM_ SG_ 333 ACC_limitierte_Anfahrdyn "Info für den Motor, dass beim ACC-Anfahren mit Zielfahrzeug seitens ACC eine limitierte Fahrpedalkennlinie gefordert wird.";
CM_ SG_ 333 ACC_Minimale_Bremsung "Im Falle eines gesetzten Bits wird vom ACC dem TSK angezeigt, dass es sich im Resume_Suspend_Mode befindet. In diesem Mode darf der TSK keine ECD-Bremsung anfordern, unabhängig von der 'ACC_Sollbeschleunigungsanforderung'. Eine Fahrzeugverzögerung darf nu";
CM_ SG_ 333 ACC_nachtr_Stopp_Anf "Dieses Signal dient dem Motor als Trigger, dass ein nachträglicher Motorstopp eingeleitet werden kann, wenn es die Bedingungen des StSt Koordinators dies zulassen.";
CM_ SG_ 333 ACC_neg_Sollbeschl_Grad_02 "Empfehlung an den Triebstrangkoordinator , mit welchem betragsmäßig maximalen negativen Gradienten eine ACC-Anforderung 'ACC_Sollbeschleunigung_02' einzuregeln ist.";
CM_ SG_ 333 ACC_pos_Sollbeschl_Grad_02 "Empfehlung an den Triebstrangkoordinator , mit welchem betragsmäßig maximalen positiven Gradienten eine ACC-Anforderung 'ACC_Sollbeschleunigung_02' einzuregeln ist.";
CM_ SG_ 333 ACC_relev_Nichtverfuegbarkeit "Frontradar-SG erkennt eine temporäre Nichtverfügbarkeit, ohne FSP-Eintrag";
CM_ SG_ 333 ACC_relevanter_Fehler "Frontradar-SG erkennt einen Fehler, mit FSP-Eintrag.";
CM_ SG_ 333 ACC_Sollbeschleunigung_02 "Anforderung an den Triebstrangkoordinator , eine 'ACC_Sollbeschleunigung' umzusetzen.";
CM_ SG_ 333 ACC_StartStopp_Info "Freigabe bzw. Startanforderung für Start/Stopp";
CM_ SG_ 333 ACC_Status_ACC "'ACC OFF' bedeutet ACC-Hauptschalter ist 'Gerastet Aus

'ACC Reversibler Fehler' bedeutet, daß das ACC aktuell einen 
reversiblen Fehler im ACC-SG selbst oder in einem zum 
ACC-System gehörenden SG erkennt.

'ACC irreversibler Fehler' bedeutet, daß ";
CM_ SG_ 333 ACC_TA_Kurve_Abstand "Gibt den Abstand zu dem Punkt an, auf den sich das Geschwindigkeitsdelta bezieht. Dieser Punkt ist nicht der Kurveneingang, sondern der Punkt in der Kurve mit maximaler Krümmung. Der Kurveneingang kann uns nicht zur Verfügung gestellt werden";
CM_ SG_ 333 ACC_TA_Kurve_vDelta "Beschreibung: Gibt das Delta der vom ACC eingeregelten Geschwindigkeit im Vergleich zu der Geschwindigkeit an, die für eine erfolgreiche TA Durchfahrt eingestellt werden müsste.";
CM_ SG_ 333 ACC_Tempolimitassistent_Ein "Status ACC-Tempolimitassistent";
CM_ SG_ 333 ACC_Typ "Motor plausibilisiert seine eigene Kodierung";
CM_ SG_ 333 ACC_Verkehrssinn "Vom Radar erkannter Verkehrssinn";
CM_ SG_ 333 ACC_zul_Regelabw_oben "Anforderung an den Triebstrangkoordinator. Zulässiger Betrag der Abweichung zwischen angeforderter 'ACC_Sollbeschleunigung(_02)' und umzusetzender Sollbeschleunigung  im TSK. Im TSK wird, abhängig vom Arbeitspunkt die Toleranz und die Sollbeschleunigung f";
CM_ SG_ 333 ACC_zul_Regelabw_unten "Anforderung an den Triebstrangkoordinator. Zulässiger Betrag der Abweichung zwischen angeforderter 'ACC_Sollbeschleunigung(_02)' und umzusetzender Sollbeschleunigung  im TSK. Im TSK wird, abhängig vom Arbeitspunkt die Toleranz und die Sollbeschleunigung f";
CM_ SG_ 333 MPPmod_1_Segment "Erstes vom MPP abweichendes Segment, welches befahren werden soll.";
CM_ SG_ 333 MPPmod_2_Segment "Zweites vom MPP abweichendes Segment, welches befahren werden soll";
CM_ SG_ 333 MPPmod_3_Segment "Drittes vom MPP abweichendes Segment, welches befahren werden soll.";
CM_ SG_ 333 MPPmod_4_Segment "Viertes vom MPP abweichendes Segment, welches befahren werden soll.";
CM_ SG_ 333 RDR_v_ueber_Grund "Das Signal V_ueber_Grund zeigt die Fahrzeuggeschwindigkeit über Grund in X-Richtung an.
Das Signal wird ausschließlich durch Auswertung von Radarsignalen erzeugt.";
CM_ SG_ 333 RDR_v_ueber_Grund_Fahrtrichtung "Das Signal zeigt die Fahrtrichtung des Fahrzeugs an.  
Das Signal wird ausschließlich durch Auswertung von Radarsignalen erzeugt.";
CM_ SG_ 333 RDR_v_ueber_Grund_Genauigkeit "Das Signal zeigt die Genauigkeit des Geschwindigkeitssignals RDR_v_ueber_Grund im 95%-Konfidenzintervall an.";
CM_ SG_ 333 RDR_VBEG_Anforderung "Anforderung einer Höchstgeschwindigkeitsbegrenzung durch den Frontradar";
CM_ SG_ 333 vESC_Verz_Anf "Die Funktion vorausschauendes ESC fordert eine Verzögerung im VZM.";

CM_ SG_ 2527679682 ACC_ASM_Data_1 "Dieses Signal wird von ACC (LongRangeRadar) befüllt und an den Assistenzsystemmonitor ASM (Host SG: Safety Computer) gesendet.";
CM_ SG_ 2527679682 ACC_ASM_Data_2 "Dieses Signal wird von ACC (LongRangeRadar) befüllt und an den Assistenzsystemmonitor ASM (Host SG: Safety Computer) gesendet.";
CM_ SG_ 2527679682 ACC_ASM_Data_3 "Dieses Signal wird von ACC (LongRangeRadar) befüllt und an den Assistenzsystemmonitor ASM (Host SG: Safety Computer) gesendet.";
CM_ SG_ 2527679682 ACC_ASM_Data_4 "Dieses Signal wird von ACC (LongRangeRadar) befüllt und an den Assistenzsystemmonitor ASM (Host SG: Safety Computer) gesendet.";
CM_ SG_ 2527679682 ACC_ASM_Data_5 "Dieses Signal wird von ACC (LongRangeRadar) befüllt und an den Assistenzsystemmonitor ASM (Host SG: Safety Computer) gesendet.";
CM_ SG_ 2527679682 ACC_ASM_Data_6 "Dieses Signal wird von ACC (LongRangeRadar) befüllt und an den Assistenzsystemmonitor ASM (Host SG: Safety Computer) gesendet.";
CM_ SG_ 2527679682 ACC_ASM_Ereignis "Dieses Signal definiert, welche Funktion und welche Art von Aktivität das Senden der Botschaft an den Assistenzsystemmonitor ASM (Host SG: Safety Computer) veranlasst hat.";
CM_ SG_ 2527679682 ACC_ASM_Zeitstempel_02 "Dieses Signal ermöglicht die zeitliche Zuordnung der von ACC an den Assistenzsystemmonitor ASM (Host SG: Safety Computer) gesendeten Statusbotschaften.";

CM_ SG_ 64 AB_Anzeige_Fussg "Anzeige für ausgelöste Fussgängerschutz-Aktuatorik";
CM_ SG_ 64 AB_Belegung_VF "Belegungserkennung vorne Fahrer.";
CM_ SG_ 64 AB_Crash_Int "Crash_Intensität_1 = fahrzeugabhängige Reaktionen im Crash
Crash_Intensität_2 = fahrzeugabhängige Reaktionen im Crash
Crash_Intensität_3 = fahrzeugabhängige Reaktionen im Crash

Die jeweiligen fahrzeugabhängigen Reaktionen im Crash sind in einem separ";
CM_ SG_ 64 AB_Deaktiviert "Airbag oder Gurtstraffer wurden per Anpassung deaktiviert: Aktualisierung erst nach Selbsttest";
CM_ SG_ 64 AB_Deaktivierung_HV "Deaktivierung des HV-Systems und der HV-Teilnehmer im Crash (u.a. Hybrid- und Elektrofahrzeuge)";
CM_ SG_ 64 AB_Diagnose "Airbag in Diagnose";
CM_ SG_ 64 AB_eCS_Error "Signal zur Anforderung der Anzeige von Störungen im System der elektrischen Gurtverriegelung";
CM_ SG_ 64 AB_EDR_Trigger "Triggerbedingung zur dezentralen Aufzeichnung unfallrelevanter Daten im Event Data Recorder";
CM_ SG_ 64 AB_Erh_Auf_VB "Der Fahrer soll bei einem Statuswechsel des Beifahrerairbags (ausgelöst durch die Beifahrerinsassenerkennung oder den Schlüsselschloßschalter) aufmerksam gemacht werden durch eine Anzeige im Kombi. Nur Audi: gültig für: AB2 (4-Türer AU352), B7, C6, D3";
CM_ SG_ 64 AB_Front_Crash "Bit wird bei Überschreitung der Gurtstraffer-, US- und RdW-Schwelle gesetzt";
CM_ SG_ 64 AB_Gurtschloss_FA_ext "Das Ergebnis der Basisfunktion 'Plausibilisierung Gurtschloss' des Verlassenskonzepts wird im Signal dargestellt.";
CM_ SG_ 64 AB_Gurtschloss_FA_ext_aktiv "Über dieses Signal wird signalisiert ob die Erweiterte Gurtdiagnose (Ergebnis wird im Signal AB_Gurtschloss_FA_ext dargestellt) aktiviert oder deaktiviert ist.";
CM_ SG_ 64 AB_Gurtwarn_VB "Beifahrer hat Gurt nicht gesteckt, Anzeige im Kombi";
CM_ SG_ 64 AB_Gurtwarn_VF "Fahrer hat Gurt nicht gesteckt, Anzeige im Kombi";
CM_ SG_ 64 AB_Heck_Crash "Wird für alle neu anlaufenden Projekte umgesetzt: AB8.4, Audi8/VW8";
CM_ SG_ 64 AB_Lampe "Sicherheitswarnlampe im Kombi wird vom Airbag-SG angesteuert; Zustand der Lampe wird auf dem CAN-Bus ausgegeben (auch Blinkinformation).";
CM_ SG_ 64 AB_MKB_Anforderung "Anforderung Multi-Kollisions-Bremsung";
CM_ SG_ 64 AB_MKB_gueltig "Multi-Kollisions-Bremsung im Airbag freigeschaltet";
CM_ SG_ 64 AB_PAO_Leuchte_Anf "Anforderung an die Passenger-Airbag-Off Leuchte in der Dachkonsole (ein / aus), Einsatz nur bei PAG";
CM_ SG_ 64 AB_RGS_Anst "PreCrash-Ansteuerung reversibler Gurtstraffer (Aktivierung und Kraftniveau)

10xx = deaktiviert";
CM_ SG_ 64 AB_Rollover_Crash "Wird im B6/B7 Cabrio und New Beetle Cabrio bedient. ";
CM_ SG_ 64 AB_SB_Crash "Z.Zt. nur in Verbindung mit Crash-Intensität >= 100b (Kraftstoffpumpenabschaltung) verwendet.
";
CM_ SG_ 64 AB_SF_Crash "Z.Zt. nur in Verbindung mit Crash-Intensität >= 100b (Kraftstoffpumpenabschaltung) verwendet.";
CM_ SG_ 64 AB_Stellgliedtest "Information, ob Airbag im Stellgliedtest ist, um eine Notrufauflösung beim Stellgliedtest zu verhindern";
CM_ SG_ 64 AB_Systemfehler "Systemfehler Ggf. wird Warnlampe dauernd eingeschaltet.";
CM_ SG_ 64 AB_Texte_AKS "Textanzeige für pyrotechnische Auslösung der aktiven Kopfstütze (AKS)";
CM_ SG_ 64 AB_VB_deaktiviert "Als Option vorgehalten, Beifahrerairbag wurden per Schlüsselschalter oder Insassenerkennung deaktiviert";
CM_ SG_ 64 AB_Versorgungsspannung "Übertragung der Plausibilitätsinformation Kl.15-Last vs. Kl.15-CAN.
Bedienung im Fall Kl.15-Last 'EIN' und Kl.15-CAN 'AUS' mit Ausgabe Warnung/Akustik im Kombi.";
CM_ SG_ 64 Airbag_01_CRC "Für MLB:
'Berechnung siehe Lastenheft 'Kommunikationsabsicherung für FlexRay und CAN''

Ab MQB und MLBevo:
'Berechnung siehe Lastenheft 'End-to-End Kommunikationsabsicherung''

Endwerte siehe Begleitdokument 'S-PDU Kennungsfolgen'";
CM_ SG_ 64 ASM_Masterzeit_02 "Masterzeit für alle ASM Sender";

CM_ SG_ 2589283872 Airbag_01_CALID_Index_01 "Calibration Identification";
CM_ SG_ 2589283872 Airbag_01_CALID_Index_02 "Calibration Identification";
CM_ SG_ 2589283872 Airbag_01_CALID_Index_03 "Calibration Identification";
CM_ SG_ 2589283872 Airbag_01_CALID_Index_04 "Calibration Identification";
CM_ SG_ 2589283872 Airbag_01_CALID_Index_05 "Calibration Identification";
CM_ SG_ 2589283872 Airbag_01_CALID_Index_06 "Calibration Identification";
CM_ SG_ 2589283872 Airbag_01_CALID_Index_07 "Calibration Identification";
CM_ SG_ 2589283872 Airbag_01_CALID_Index_08 "Calibration Identification";
CM_ SG_ 2589283872 Airbag_01_CALID_Index_09 "Calibration Identification";
CM_ SG_ 2589283872 Airbag_01_CALID_Index_10 "Calibration Identification";
CM_ SG_ 2589283872 Airbag_01_CALID_Index_11 "Calibration Identification";
CM_ SG_ 2589283872 Airbag_01_CALID_Index_12 "Calibration Identification";
CM_ SG_ 2589283872 Airbag_01_CALID_Index_13 "Calibration Identification";
CM_ SG_ 2589283872 Airbag_01_CALID_Index_14 "Calibration Identification";
CM_ SG_ 2589283872 Airbag_01_CALID_Index_15 "Calibration Identification";
CM_ SG_ 2589283872 Airbag_01_CALID_Index_16 "Calibration Identification";

CM_ SG_ 2589283873 Airbag_01_CVN_Byte_1 "Calibration Verification Number";
CM_ SG_ 2589283873 Airbag_01_CVN_Byte_2 "Calibration Verification Number";
CM_ SG_ 2589283873 Airbag_01_CVN_Byte_3 "Calibration Verification Number";
CM_ SG_ 2589283873 Airbag_01_CVN_Byte_4 "Calibration Verification Number";
CM_ SG_ 2589283873 Airbag_01_CVN_VLD "Über dieses Signal wird gekennzeichnet, ob die Berechnung der CVN im SecondaryOBDECU abgeschlossen ist.";

CM_ SG_ 1312 AB_Abschaltanf_SIH_BF "Die Insassenerkennung auf der Beifahrerseite fordert bei Übertemperatur eine Abschaltung der Sitzheizung an. Die Übertemperatur kann bei niederohmigen Nebenschlüssen der Sitzheizungsmatte als Folge von zu hohem resultierenden Strom auftreten.";
CM_ SG_ 1312 AB_Anforderung_eCall "Trigger für Car2X Steuergerät das ein eCall Ereignis erkannt wurde.";
CM_ SG_ 1312 AB_Anforderung_USM "Trigger für Gateway (OBDC) und MIB/MMI, dass ein USM-Ereignis erkannt wurde.";
CM_ SG_ 1312 AB_Anprall_FGS "Uebermittlung der Lage einer Kollision, Fussgaengerschutz-Aktorik";
CM_ SG_ 1312 AB_Anprall_Front_Beifahrer "Uebermittlung der Lage einer Kollision, Anprallzone Front Beifahrerseite";
CM_ SG_ 1312 AB_Anprall_Front_Fahrer "Uebermittlung der Lage einer Kollision, Anprallzone Front Fahrerseite";
CM_ SG_ 1312 AB_Anprall_Heck_Beifahrer "Uebermittlung der Lage einer Kollision, Anprallzone Beifahrerseite hinten";
CM_ SG_ 1312 AB_Anprall_Heck_Fahrer "Uebermittlung der Lage einer Kollision, Anprallzone Fahrerseite hinten";
CM_ SG_ 1312 AB_Anprall_Rollover "Uebermittlung der Lage einer Kollision, Rollover erkannt";
CM_ SG_ 1312 AB_Anprall_Seite_Beifahrer "Uebermittlung der Lage einer Kollision, Anprallzone Beifahrerseite Seite";
CM_ SG_ 1312 AB_Anprall_Seite_Fahrer "Uebermittlung der Lage einer Kollision, Anprallzone Fahrerseite Seite";
CM_ SG_ 1312 AB_Belegung_VB "Belegungserkennung vorne Beifahrer. Wird in US-Steuergeräten über Bladder-Matte bedient, optional bei RdW, falls SBE_EuroNCAP entschieden wird.";
CM_ SG_ 1312 AB_Crashschwere "Übermittlung der Crashschwere an das Gateway (OBDC)";
CM_ SG_ 1312 AB_Gurtschloss_BF "Gurtschlossstatus Beifahrerseite";
CM_ SG_ 1312 AB_Gurtschloss_FA "Gurtschlosstatatus Fahrerseite";
CM_ SG_ 1312 AB_Gurtschloss_Reihe2_BF "Gurtschlossstatus 2. Reihe Beifahrerseite,  Mehrausstattung";
CM_ SG_ 1312 AB_Gurtschloss_Reihe2_FA "Gurtschlossstatus 2. Reihe Fahrerseite, Mehrausstattung";
CM_ SG_ 1312 AB_Gurtschloss_Reihe2_MI "Gurtschlossstatus 2. Reihe Mitte,  Mehrausstattung";
CM_ SG_ 1312 AB_Gurtschloss_Reihe3_BF "Gurtschlossstatus 3. Reihe Beifahrerseite,  Mehrausstattung";
CM_ SG_ 1312 AB_Gurtschloss_Reihe3_FA "Gurtschlossstatus 3. Reihe Fahrerseite,  Mehrausstattung";
CM_ SG_ 1312 AB_Gurtschloss_Reihe3_MI "Gurtschlossstatus 3. Reihe Mitte,  Mehrausstattung";
CM_ SG_ 1312 AB_Sitzpos_Sens_BF "Ausgabe Sitzposition Beifahrer";
CM_ SG_ 1312 AB_Sitzpos_Sens_FA "Ausgabe Sitzposition Fahrer";
CM_ SG_ 1312 AB_Wickelklappung_Reihe2_BF "Status Wickelklappung 2. Reihe Beifahrerseite, Mehrausstattung";
CM_ SG_ 1312 AB_Wickelklappung_Reihe2_FA "Status Wickelklappung 2. Reihe Fahrerseite, Mehrausstattung";
CM_ SG_ 1312 AB_Wickelklappung_Reihe2_MI "Status Wickelklappung 2. Reihe Mitte, Mehrausstattung";
CM_ SG_ 1312 Airbag_02_CRC "Für MLB:
'Berechnung siehe Lastenheft 'Kommunikationsabsicherung für FlexRay und CAN''

Ab MQB und MLBevo:
'Berechnung siehe Lastenheft 'End-to-End Kommunikationsabsicherung''

Endwerte siehe Begleitdokument 'S-PDU Kennungsfolgen'";
CM_ SG_ 1312 LoGeWa_Event_Kombiwarnung "Event für Kombiwarnung";
CM_ SG_ 1312 SC_PAO_OFF_Anf "Sollwert für LED 'OFF' in Anzeige Passenger Airbag On/Off";
CM_ SG_ 1312 SC_PAO_ON_Anf "Sollwert für LED 'ON' in Anzeige Passenger Airbag On/Off";
CM_ SG_ 1312 SC_PAO_Schriftzug_Anf "Sollwert für LED 'PASSENGER AIRBAG' in Anzeige Passenger Airbag On/Off";

CM_ SG_ 65 AB_DeltaV_X_eCall "Transmission of the DeltaV longitudinal during Crash (0-250ms) as additional information for eCall";
CM_ SG_ 65 AB_DeltaV_Y_eCall "Transmission of the DeltaV lateral during Crash (0-250ms) as additional information for eCall";
CM_ SG_ 65 AB_MKB_Safing "Safing für Multi-Kollisions-Bremsung";
CM_ SG_ 65 Airbag_03_CRC "Für MLB:
'Berechnung siehe Lastenheft 'Kommunikationsabsicherung für FlexRay und CAN''

Ab MQB und MLBevo:
'Berechnung siehe Lastenheft 'End-to-End Kommunikationsabsicherung''

Endwerte siehe Begleitdokument 'S-PDU Kennungsfolgen'";

CM_ SG_ 1349 AB_Anprall_Front "Uebermittlung der Lage einer Kollision, Anprallzone Front";
CM_ SG_ 1349 AB_Anprall_Heck "Uebermittlung der Lage einer Kollision, Anprallzone Heck";
CM_ SG_ 1349 AB_Belegung_VF_ext "Das Signal kommuniziert den Status des Sitzbelegsensors Fahrer incl. dauerhafter Zustände mit Signalqualität ASIL A.";
CM_ SG_ 1349 AB_Belegung_VF_ext_aktiv "Kennzeichnet aktive Funktion 'Erweiterte Sitzbelegdiagnose' für Signal AB_Belegung_VF_ext";
CM_ SG_ 1349 AB_Gurtwarn_Reihe2_BF "Status Gurtwarnung 2. Sitzreihe Beifahrerseite";
CM_ SG_ 1349 AB_Gurtwarn_Reihe2_FA "Status Gurtwarnung 2. Sitzreihe Fahrerseite";
CM_ SG_ 1349 AB_Gurtwarn_Reihe2_MI "Status Gurtwarnung 2. Sitzreihe Mitte";
CM_ SG_ 1349 AB_Gurtwarn_Reihe3_BF "Status Gurtwarnung 3. Sitzreihe Beifahrerseite";
CM_ SG_ 1349 AB_Gurtwarn_Reihe3_FA "Status Gurtwarnung 3. Sitzreihe Fahrerseite";
CM_ SG_ 1349 AB_Gurtwarn_Reihe3_MI "Status Gurtwarnung 3. Sitzreihe Mitte";
CM_ SG_ 1349 AB_Gurtwarn_Reihe4_BF "Status Gurtwarnung 4. Sitzreihe Beifahrerseite";
CM_ SG_ 1349 AB_Gurtwarn_Reihe4_FA "Status Gurtwarnung 4. Sitzreihe Fahrerseite";
CM_ SG_ 1349 AB_Gurtwarn_Reihe4_MI "Status Gurtwarnung 4. Sitzreihe Mitte";
CM_ SG_ 1349 AB_SBR_hinten_verbau "Verbauinformation Sitzbelegungssensor hinten (2. und 3. Sitzreihe)";
CM_ SG_ 1349 AbstWarn_MV_FAS_Fkt_Status "FAS-ProfileMaster Iststatus der Kundenfunktion";
CM_ SG_ 1349 Airbag_04_BZ "4bit Botschaftszähler, wird mit jeder Sendebotschaft inkrementiert";
CM_ SG_ 1349 Airbag_04_CRC "Für MLB:
Berechnung siehe Lastenheft 'Kommunikationsabsicherung für FlexRay und CAN'
Ab MQB und MLBevo:
Berechnung siehe Lastenheft 'End-to-End Kommunikationsabsicherung'

Endwerte siehe Begleitdokument 'S-PDU Kennungsfolgen'";
CM_ SG_ 1349 AWV_Einstellung_System_ASG "Signal zur Realisierung des BAP-Koordinators";
CM_ SG_ 1349 AWV_Einstellung_Warnung_ASG "Signal zur Realisierung des BAP-Koordinators";
CM_ SG_ 1349 LGI_FAS_Fkt_Status "FAS-ProfileMaster Iststatus der Kundenfunktion (LGI: Lokale Gefahreninformation)";
CM_ SG_ 1349 PreCrash_FAS_Fkt_Status "FAS-ProfileMaster Iststatus der Kundenfunktion";
CM_ SG_ 1349 SC_PreSense_Modus_System_KAS "BAP-Kommunikation zum Kreuzungsassistent";
CM_ SG_ 1349 SC_PreSense_Modus_System_MV "Signal zur Realisierung der BAP-Kommunikation für PreSense";
CM_ SG_ 1349 SC_PreSense_Modus_System_NV "Signal zur Realisierung der BAP-Kommunikation für PreSense";
CM_ SG_ 1349 SC_PreSense_Modus_Warnung_MV "Signal zur Realisierung der BAP-Kommunikation für PreSense";
CM_ SG_ 1349 SC_PreSense_Modus_Warnung_NV "Signal zur Realisierung der BAP-Kommunikation für PreSense";
CM_ SG_ 1349 WarnBrems_Charisma_FahrPr "Aktuell eingestelltes Fahrprogramm der Funktion Warn- und/oder Notbremsfunktion";
CM_ SG_ 1349 WarnBrems_Charisma_Status "Verfügbarkeit der Funktion Warn- und/oder Notbremsfunktion für die Ansteuerung durch den Charisma-Koordinator.";

CM_ SG_ 2527679722 AB_Anzeige_Kombi_SRAB "Status SRAB HMI";
CM_ SG_ 2527679722 AB_Anzeige_Komfort_HBFS "Komfortposition überschritten HBFS";
CM_ SG_ 2527679722 AB_Anzeige_Komfort_HFS "Komfortposition überschritten HFS";
CM_ SG_ 2527679722 AB_Anzeige_Sitz_Komfort_HBFS "Sitzdisplay Komfortposition überschritten HBFS";
CM_ SG_ 2527679722 AB_Anzeige_Sitz_Komfort_HFS "Sitzdisplay Komfortposition überschritten HFS";
CM_ SG_ 2527679722 AB_Gurtschloss_MI "Gurtschloss-Status 1. Reihe Mitte
Ersteinsetzer: T6PA";
CM_ SG_ 2527679722 AB_Gurtschloss_Reihe4_BF "Gurtschlossstatus 4. Reihe Beifahrerseite,  Mehrausstattung";
CM_ SG_ 2527679722 AB_Gurtschloss_Reihe4_FA "Gurtschlossstatus 4. Reihe Fahrerseite, Mehrausstattung";
CM_ SG_ 2527679722 AB_Gurtschloss_Reihe4_MI "Gurtschlossstatus 4. Reihe Mitte,  Mehrausstattung";
CM_ SG_ 2527679722 AB_Gurtwarn_VM "Beifahrer auf mittlerem Sitz (Nutzfahrzeug) hat Gurt nicht gesteckt, Anzeige im Kombi";
CM_ SG_ 2527679722 AB_Status_Sitz_SRAB_HBFS "Status SRAB Sitzdisplay HBFS";
CM_ SG_ 2527679722 AB_Status_Sitz_SRAB_HFS "Status SRAB Sitzdisplay HFS";
CM_ SG_ 2527679722 AB_wSBR_Batteriestatus "Anzeige einer schwachen Batterie in einer Sitzeinheit des wSBR-Systems im Kombi.";
CM_ SG_ 2527679722 Airbag_06_BZ "4bit Botschaftszähler, wird mit jeder Sendebotschaft inkrementiert";
CM_ SG_ 2527679722 Airbag_06_CRC "Für MLB:
Berechnung siehe Lastenheft 'Kommunikationsabsicherung für FlexRay und CAN'
Ab MQB und MLBevo:
Berechnung siehe Lastenheft 'End-to-End Kommunikationsabsicherung'

Endwerte siehe Begleitdokument 'S-PDU Kennungsfolgen'";

CM_ SG_ 63 AB_Anforderung_USM_Auth "Trigger für Gateway (OBDC) und MIB/MMI, dass ein USM-Ereignis erkannt wurde: 
SOK geschütztes Signal des AB_Anforderung_USM Signals geschütztes Signal der AB_Anforderung_USM für LGW-Detektion 	
Absicherung des Eingangssignal für LokaleGefahrenwarnung. ";
CM_ SG_ 63 AB_Crash_Int_Auth "Crash_Intensität_1 = fahrzeugabhängige Reaktionen im Crash
Crash_Intensität_2 = fahrzeugabhängige Reaktionen im Crash
Crash_Intensität_3 = fahrzeugabhängige Reaktionen im Crash

Die jeweiligen fahrzeugabhängigen Reaktionen im Crash sind in einem separ";
CM_ SG_ 63 AB_Front_Crash_Auth "Bit wird bei Überschreitung der Gurtstraffer-, US- und RdW-Schwelle gesetzt
Erkannter Front-Crash
Authentisches Signal zur Absicherung mit SOK (inhaltlich redundant zu AB_Front_Crash)";
CM_ SG_ 63 AB_Heck_Crash_Auth "Erkannter Heck-Crash
Authentisches Signal zur Absicherung mit SOK (inhaltlich redundant zu AB_Heck_Crash)";
CM_ SG_ 63 AB_MKB_Anforderung_Auth "Anforderung Multi-Kollisions-Bremsung
Authentisches Signal zur Absicherung mit SOK (inhaltlich redundant zu AB_MKB_Anforderung)";
CM_ SG_ 63 AB_MKB_gueltig_Auth "Multi-Kollisions-Bremsung im Airbag freigeschaltet
Authentisches Signal zur Absicherung mit SOK (inhaltlich redundant zu AB_MKB_gueltig)";
CM_ SG_ 63 AB_PAO_off_ANF_Auth "Sollwert für LED 'OFF' in Anzeige Passenger Airbag On/Off";
CM_ SG_ 63 AB_PAO_on_ANF_Auth "Sollwert für LED 'ON' in Anzeige Passenger Airbag On/Off";
CM_ SG_ 63 AB_Rollover_Crash_Auth "Erkannter Rollover Crash
Authentisches Signal zur Absicherung mit SOK (inhaltlich redundant zu AB_Rollover_Crash)";
CM_ SG_ 63 AB_SB_Crash_Auth "Z.Zt. nur in Verbindung mit Crash-Intensität >= 100b (Kraftstoffpumpenabschaltung) verwendet.
Erkannter Crash Beifahrerseite
Authentisches Signal zur Absicherung mit SOK (inhaltlich redundant zu AB_SB_Crash)";
CM_ SG_ 63 AB_SF_Crash_Auth "Z.Zt. nur in Verbindung mit Crash-Intensität >= 100b (Kraftstoffpumpenabschaltung) verwendet.
Erkannter Crash Fahrerseite
Authentisches Signal zur Absicherung mit SOK (inhaltlich redundant zu AB_SF_Crash)";
CM_ SG_ 63 AB_VRU_Crash "Anprall eines Passanten erkannt";
CM_ SG_ 63 Airbag_07_BZ "4bit-Botschaftszaehler, wird in jeder Sendebotschaft inkrementiert";
CM_ SG_ 63 Airbag_07_CRC "Für MLB:
Berechnung siehe Lastenheft 'Kommunikationsabsicherung für FlexRay und CAN'
Ab MQB und MLBevo:
Berechnung siehe Lastenheft 'End-to-End Kommunikationsabsicherung'

Endwerte siehe Begleitdokument 'S-PDU Kennungsfolgen'";
CM_ SG_ 63 SOK_Airbag_07_Signatur "Signatur im Rahmen der durch SOK geschützten Broadcast-Kommunikation
Geschützte Funktion: Abschaltung Kraftstoffpumpe, Crashlüften, Türen im Crash entriegeln, Automatische Deaktivierung Beifahrer- und Knieairbag über Insassenklassifizierung, Multikollisi";

CM_ SG_ 280 ALR_Charisma_FahrPr "MLB: Aktuelles Fahrprogramm des Charisma-Teilnehmers (siehe Systemlastenheft Drive Select)
MQB: Istwert der Kennlinie (siehe Systemlastenheft MQB Charisma)";
CM_ SG_ 280 ALR_Charisma_Status "Systemstatus des Charismateilnehmers

Wert 0x3 ist nur für Fahrzeuge ab MQB relevant
";
CM_ SG_ 280 ALR_Ist_Proz "Istsperrgrad der Längssperre
MQB Haldex: 100% Moment entsprechen 2000 Nm

Allrad_quod:
Im Status Offroad-Lock (Überanpressung der Allradkupplung) wird ALR_ist_Proz = 250 (100%) angezeigt.";
CM_ SG_ 280 ALR_Sendestatus "Gibt den Sendestatus der Längssperre an (notwendig für IL-Unterstützung)";
CM_ SG_ 280 ALR_Sta_Laengssperre "Gibt den Status der Längssperre für andere Systeme an";
CM_ SG_ 280 ALR_Warnlampe "'1', wenn Kuppung aufgrund zu vieler Fehler öffnet.
Aufprüfung der Warnlampe somit nicht möglich.  ";

CM_ SG_ 308 ALR_gMeter_ax "Längsbeschleunigung zur g-Meter-Anzeige im Kombi";
CM_ SG_ 308 ALR_gMeter_ay "Querbeschleunigung zur g-Meter-Anzeige im Kombi";

CM_ SG_ 1633 AAG_Anhaenger_abgesteckt "Anhaenger wurde bei Kl. 15 aus abgesteckt";
CM_ SG_ 1633 AAG_Anhaenger_erkannt "Erkennung Anhaenger ";
CM_ SG_ 1633 AAG_AVS_Fehler_02 "Fehler AVS";
CM_ SG_ 1633 AAG_AVS_Fehler_02_inv "Fehler AVS (inverses Signal)";
CM_ SG_ 1633 AAG_AVS_Stati "Status AVS (bei abnehmbarer oder mech.schwenkbarer Anhängerkupplung ist der Status immer 0)";
CM_ SG_ 1633 AAG_Blinker_H_aktiv "Status: Anhaenger Blinker aktiv";
CM_ SG_ 1633 AAG_Blinker_HL_def "Anhaenger Blinker links defekt";
CM_ SG_ 1633 AAG_Blinker_HR_def "Anhaenger Blinker rechts defekt";
CM_ SG_ 1633 AAG_Bremsl_durch_ECD "Bremslicht durch ECD aktiv";
CM_ SG_ 1633 AAG_Bremslicht_H_def "Anhaenger Bremslicht defekt";
CM_ SG_ 1633 AAG_Bremslicht_Reku "AAG_Bremslicht_Reku meldet zyklisch den empfangenen Zustand des CAN-Signals MO_Bremslicht_Reku zurück.";
CM_ SG_ 1633 AAG_BZ "4bit-Botschaftszaehler, wird in jeder Sendebotschaft inkrementiert

";
CM_ SG_ 1633 AAG_LED_aktiv "Dieses Signal sendet der Beleuchtungsart des Anhängers (LED oder Lampe)
Bei LED aktiv erfolgt kein Kaltüberwachung";
CM_ SG_ 1633 AAG_NSL_aktiv "Anhaenger Nebelschlusslicht aktiv";
CM_ SG_ 1633 AAG_Schlusslicht_HL_def "Anhaenger Schlußlicht links defekt";
CM_ SG_ 1633 AAG_Schlusslicht_HR_def "Anhaenger Schlußlicht rechts defekt";

CM_ SG_ 2527679661 AWV_AW_Abstand "Signal dient zur Anzeige des Abstands im Kombi.";
CM_ SG_ 2527679661 AWV_AW_Texte "Signal zur Ansteuerung von Fahrer- und Warnhinweisen des Abstandswarners im Mitteldisplay";
CM_ SG_ 2527679661 AWV_AW_Texte_Zusatzanzeige "Signal zur Ansteuerung von Fahrer- und Warnhinweisen des Abstandswarners im Mitteldisplay";
CM_ SG_ 2527679661 AWV_AW_Zeitluecke "Anzeige der aktuellen Zeitluecke zum vorausfahrenden Fahrzeug (AW == Abstandswarner)";
CM_ SG_ 2527679661 AWV_Einstellung_System_FSG "Signal zur Realisierung des BAP-Koordiantors";
CM_ SG_ 2527679661 AWV_Einstellung_Warnung_FSG "Signal zur Realisierung des BAP-Koordinators";
CM_ SG_ 2527679661 AWV_KA_Konfiguration "Systemstatus Bedienung vom Kreuzungsassistent zum PaCo.";
CM_ SG_ 2527679661 AWV_KA_ObjektFront "Anforderung der MIB Parkenanzeige vom Kreuzungsassistent zum PaCo.";
CM_ SG_ 2527679661 AWV_Kamera_Objekt_ID "Kamera Objekt-ID des AWV-Zielobjekts";
CM_ SG_ 2527679661 AWV_LED_Leiste "Ansteuerung LED Warnleiste";
CM_ SG_ 2527679661 AWV_Priowarnung "Priorisierung der AWV-Warnung über die Spurverlassensanzeige des HCA";
CM_ SG_ 2527679661 AWV_Status_Anzeige "Signal zur Realisierung des BAP-Koordiantors
Signal identisch zu AWV_BAP_Status 
Kl15 aus: nicht bereitgestellt.";
CM_ SG_ 2527679661 AWV_Texte_02 "Hinweisanzeige im Kombi 'Hauptdisplay'
Wert 6 - Eingeschränkte Verfügbarkeit der weiteren Fusionsteilnehmer (z.B. MFK, FER)";
CM_ SG_ 2527679661 AWV_Warnlevel "Warnlevel der Funktion Anhaltewegverkürzung";
CM_ SG_ 2527679661 AWV_Warnung "Hinweisanzeige im Kombi 'Hauptdisplay'";
CM_ SG_ 2527679661 AWV_Warnung_Richtung "Zusätzliche Richtungsanzeige zum Signal AWV_Warnung für die Darstellung im Smartlight und HUD.";
CM_ SG_ 2527679661 WBA_Warnblinken "Ansteuerung des Warnblinkers für die Funktion Warnen, Bremsen, Ausweichen";

CM_ SG_ 219 AWV_03_BZ "4bit Botschaftszähler, wird mit jeder Sendebotschaft inkrementiert";
CM_ SG_ 219 AWV_03_CRC "Für MLB:
Berechnung siehe Lastenheft 'Kommunikationsabsicherung für FlexRay und CAN'
Ab MQB und MLBevo:
Berechnung siehe Lastenheft 'End-to-End Kommunikationsabsicherung'

Endwerte siehe Begleitdokument 'S-PDU Kennungsfolgen'";
CM_ SG_ 219 AWV_Anf_Prefill "Anforderung an VZM, dass die Prefill-Funktion aktiviert werden soll.";
CM_ SG_ 219 AWV_Eingriff_Sendeart "Umschalten zwischen langsamem und schnellem Zyklus der AWV_Eingriffs-Botschaft";
CM_ SG_ 219 AWV_Fahrerbremswunsch_erf "Anforderung an das ESC, die Verzögerungsdynamik höher als die Auswertung des Fahrerbremswunsch zu priorisieren.";
CM_ SG_ 219 AWV_HBA_Param "Anforderung an HBA zur Anpassung der HBA-Auslöseschwelle.";
CM_ SG_ 219 AWV_QFK_AnfStat "Statusinformationen des Anforderers";
CM_ SG_ 219 AWV_QFK_Art1 "Auswahlsignal für AWV_QFK_Signal1";
CM_ SG_ 219 AWV_QFK_Art2 "Auswahlsignal für AWV_QFK_Signal2";
CM_ SG_ 219 AWV_QFK_KrSoll "Krümmungsanforderung";
CM_ SG_ 219 AWV_QFK_KrSoll_VZ "Vorzeichen für die Krümmungsanforderung";
CM_ SG_ 219 AWV_QFK_KruemmSoll "Krümmungsanforderung";
CM_ SG_ 219 AWV_QFK_KruemmSoll_VZ "Vorzeichen für die Krümmungsanforderung";
CM_ SG_ 219 AWV_QFK_Signal1 "Inhalt AWV_QFK_Signal1 wird durch das Signal AWV_QFK_Art1 gesteuert.
Nähere Informationen im LAH Querführungskoordinator.";
CM_ SG_ 219 AWV_QFK_Signal2 "Inhalt AWV_QFK_Signal2 wird durch das Signal AWV_QFK_Art2 gesteuert.
Nähere Informationen im LAH Querführungskoordinator.";
CM_ SG_ 219 AWV_QFK_Spuerb "Spürbarkeitsanforderung. Legt fest, mit welchem Handmoment die angeforderte Krümmung überlenkt werden muss.";
CM_ SG_ 219 AWV_Ruckprofil "Anforderung an VZM, welcher Ruck aus einer Auswahl von 3 verschiedenen Ruckprofilen verwendet werden soll.";
CM_ SG_ 219 AWV_Status_AWU "Signal für die Erfüllung der GSR2 EDR Anforderungen bezüglich der Unterfunktion AWU des Elementes CSF.";
CM_ SG_ 219 AWV_Time_to_brake "Zeit in Millisekunden bs zu einer AWV Verzögerungsanforderung (ATB oder ZBR)";
CM_ SG_ 219 AWV_Time_to_collision "Prädizierter Aufprallzeitpunkt des relevanten Objektes aus der AWV-Funktion";
CM_ SG_ 219 AWV_Timestamp_TTC "Messzeitpunkt der WBA Daten";
CM_ SG_ 219 AWV_Verz_Anf "Verzögerungsanforderung der Funktionen Zielbremsung und Teilbremsung an das VZM";
CM_ SG_ 219 AWV_Verz_Anf_ASIL "Definiert das Anforderungssignal von FKT an VZM mit dem dynamischen ASIL";
CM_ SG_ 219 AWV_Verz_Freigabe "Freigabe-Bit der AWV Verzögerung an das VZM";
CM_ SG_ 219 AWV_Zielobjekttyp "Definiert den Zielobjekttyp an VZM";
CM_ SG_ 219 PCF_Freigabe "Freigabe der Funktion PreCrash-Front";
CM_ SG_ 219 SDF_PSF_CU_Status "Kollisionsvermeidbarkeit";
CM_ SG_ 219 SDF_PSF_CW "Kollisionswahrscheinlichkeit";
CM_ SG_ 219 SDF_PSF_Fahrer_aktiv "Fahreraktivität";
CM_ SG_ 219 SDF_PSF_Guete "Guete des Objektes

Umsetzung ab MQB37W Baseline: 
Wert 0: Initialwert;  Wert 1 ('Modellgüte n.i.O_kein_Plausi') wird nicht mehr bedatet bei vorhandenem Crashobjekt. Es werden nur 2 und 3 bedatet. Somit ist der Informationsgehalt dieses Signales nur de";
CM_ SG_ 219 SDF_PSF_Kollisionsueberdeckung "Kollisionsueberdeckung in y-Richtung";
CM_ SG_ 219 SDF_PSF_Objektstatus "Objektstatus";
CM_ SG_ 219 SDF_PSF_Time_To_Collision "Zeit bis zur Kollision";
CM_ SG_ 219 SDF_PSF_v_rel "Prädizierte Aufprallgeschwindigkeit";
CM_ SG_ 219 SOK_AWV_03_Signatur "Signatur im Rahmen der durch SOK geschützen Broadcast-Kommunikation

Geschützte Funktion: Anhaltwegverkürzung 
Geschützte Botschaft: AWV_03";

CM_ SG_ 1626 APS_Tongeber_defekt "Status APS-Tongeber zur HMI-Ansteuerng der RCTA-Funktion";
CM_ SG_ 1626 BCM1_AFS_Lampe "Ansteuerung der AFS-Fehlermeldung im Kombi";
CM_ SG_ 1626 BCM1_EasyEntry_Status "Status EasyEntry für Lenksäule (wird auch von IVB verwendet)";
CM_ SG_ 1626 BCM1_Fahrlicht_Hinweis "Signal zum Kombi um den Hinweis 'Bitte Fahrlicht einschalten' anzufordern";
CM_ SG_ 1626 BCM1_Hinweis_Lichtnachlauf "Signal dient der Anzeige eines aktiven Lichtnachlaufes beim automatischen Abschalten der Klemme S und Klemme 15. Der Lichtnachlauf wird gestartet, wenn die Klemme 15 bei aktivem Fahrlicht deaktiviert wird.";
CM_ SG_ 1626 BCM1_Kl_15_HW_erkannt "Erkennung Klemme 15 (Hardware) vom BCM1
";
CM_ SG_ 1626 BCM1_Kl_15_Sig_HW_erkannt "Erkennung Klemme 15 Signal (Hardware) vom BCM1";
CM_ SG_ 1626 BCM1_LDS_Stellung "Das Signal wird vom AFS / LWR Steuergerät empfangen und dient der Verifizierung der Lichtdrehschalterstellung. Intelligente Lichtfunktionen wie dyn. KL und gleitende Leuchtweite (GLW) nur bei LDS = 'AUTO'.";
CM_ SG_ 1626 BCM1_Lenksaeule_aktiv "Lenksaeulenverstellung aktiv";
CM_ SG_ 1626 BCM1_Licht_Warn "Lichtwarnung";
CM_ SG_ 1626 BCM1_Lichtwarn_Texte "Anforderung von Lichtwarnungen vom BCM1 zum Kombi
MLB: nur Werte 0..2";
CM_ SG_ 1626 BCM1_MH_Schalter "Motorhaubenkontakt";
CM_ SG_ 1626 BCM1_MH_WIV_Schalter "Bewerteter Motorhaubenkontakt fuer WIV";
CM_ SG_ 1626 BCM1_NV_Taster "BCM1_NV_Taster gibt an, ob der NightVision-Taster im Lichtdrehschalter-Modul aktuell betaetigt wird.";
CM_ SG_ 1626 BCM1_Reisemodus_Texte "Ansteuerung der Reisemodus-Texte im Kombi";
CM_ SG_ 1626 BCM1_Rueckfahrlicht_Schalter "Rückfahrlichtschalter
ab MQB/ MLBevo: Die Ganginformation wird unentprellt übertragen, im AT-Getriebe wird evtl. kurzzeitig der R-Gang angezeigt. Eine Entprellung muß im Empfänger erfolgen (typisch 400ms).";
CM_ SG_ 1626 BCM1_Spannungs_Anf "Forderung des BCM1-SG's zur Spannungsanhebung.";
CM_ SG_ 1626 BCM1_Valet_Parking_Taster "Valet Parking Taster ";
CM_ SG_ 1626 BCM1_Warnblink_Taster "Warnblinktaster";
CM_ SG_ 1626 BCM_Anf_AAW_MoLaWa "Signal zur Anforderung der Antrieb-Aktiv-Warnung und Motorlaufwarnung. Die Berechnung erfolgt im BCM. Die Ausgabe der Warnungen wird vom Kombiinstrument realisiert";
CM_ SG_ 1626 BCM_Bremsbelag_Sensor "Sensorsignal der Stromschleife  für Bremsbelagverschleiß aktuell, entstört, unbewertet";
CM_ SG_ 1626 BCM_Bremsfluessigkeit_Sensor "Kontaktsignal des Sensorschalters für die Bremsflüssigkeitsreserve aktuell, entstört, unbewertet";
CM_ SG_ 1626 BCM_Charisma_Taste2 "Betätigung der Charisma-Taste 2";
CM_ SG_ 1626 BCM_Eco_Charisma_Taste "Betätigung Taster ECO alias BlueKey oder Charisma";
CM_ SG_ 1626 BCM_Handbremse_Hinweis "Infotext fuer das Kombiinstrument zur Oeffnung der elektr. Heckklappe.";
CM_ SG_ 1626 BCM_HBFS_EOE_aktiv "Elektrisch-Oeffnen-Motor aktiv";
CM_ SG_ 1626 BCM_HDF_betaetigt "Betätigung Taster für Heckdeckelfernentriegelung in Mittelkonsole";
CM_ SG_ 1626 BCM_HFS_EOE_aktiv "Elektrisch-Oeffnen-Motor aktiv";
CM_ SG_ 1626 BCM_Hybrid_StartStopp_Taste "Betaetigung Taster 'Hybrid' oder alternativ Taster 'Start/Stopp Deaktivierung', je nach Verbau";
CM_ SG_ 1626 BCM_Hybrid_StSt_Taste_Fehler "Fehlerflag, wenn Tasterdiagnose im BCM für den StSt-Taster anschlägt.";
CM_ SG_ 1626 BCM_Kuehlmittel_Sensor "Signal der Sensorelektroden für die Kühlmittelreserve aktuell, entstört, bewertet (OK/Mangel)";
CM_ SG_ 1626 BCM_Kuehlmittel_Sensor_02 "Signal der zweiten Sensorelektroden für die Kühlmittelreserve aktuell, entstört, bewertet (OK/Mangel)";
CM_ SG_ 1626 BCM_Offroad_Taste "Betätigung der Offroad-Taste";
CM_ SG_ 1626 BCM_ValetTaster_Fkts_LED "Im MQB beschreibt das Signal nur den Zustand der Funktion Valet Parking (aktiv/ inaktiv)
Im MLBevo wird über das Signal zusätzlich die ValetTaster_Fkts_LED (an/ aus) gesteuert";
CM_ SG_ 1626 BCM_Waehlhebel_P_Hinweis "Infotext NAR für die Vorbedingung 'Waehlhebel in P' für Öffnen der Heckklappe über den Fahrerrauminnentaster.";
CM_ SG_ 1626 BCM_Waschwasser_Sensor "Signal der Sensorelektroden für die Waschwasserreserve aktuell, entstört, bewertet (OK/Mangel)";
CM_ SG_ 1626 DWA_Alarmquelle "Signalisiert den Auslösegrund der DWA";
CM_ SG_ 1626 DWA_Einschraenkung "Signalisiert Fehler der DWA";
CM_ SG_ 1626 Gong_TFL_Umschaltung "Aktivierung / Deaktivierung des TFL per Affengriff wird mit einem Gong im Kombi quittiert.";
CM_ SG_ 1626 LRH_Taster "Tasterbetätigung Lenkradheizung";

CM_ SG_ 2527679939 BDM_I_U_VorgabeZwang_2 "Ladestrom und Spannungsvorgabe sind als Zwangsvorgaben der LiIon Starterbatterie zu behandeln";
CM_ SG_ 2527679939 BDM_Kommunikationsbasis_2 "LiIon-Batterie oder Bleibatterie";
CM_ SG_ 2527679939 BDM_Kuehlung_Anf "Kühlungs - Anforderung der 12V LiIon - Batterie";
CM_ SG_ 2527679939 BDM_LiIon_Status_2 "Aufgrund Alterung oder interner Defekte der Elektronik werden verschiedene Servicemaßnahmen an das eEM kommuniziert.";
CM_ SG_ 2527679939 BDM_LiIon_Zellenanzahl_2 "Anzahl der diagnostizierbaren Zellen.";
CM_ SG_ 2527679939 BDM_TE_Diagnose_2 "Diagnosestatus Trennelement LiIon Starterbatterie";
CM_ SG_ 2527679939 BDM_TE_Status_2 "Schaltzustand des Trennelemements der LiIon Starterbatterie.";
CM_ SG_ 2527679939 BDM_Variante "Unterscheidung zwischen 2-Pol, 3-Pol und zukünftigen Batterievarianten";
CM_ SG_ 2527679939 BDM_ZellStatus_Index_2 "Multiplexsignal Zellnummer der LiIon Starterbatterie";
CM_ SG_ 2527679939 BDM_ZellStatus_Inhalt_2 "SoF:                    3B;0-Leist-faehigk_n_ausr,1-Leist-faehigk_ausr,2-keine_Berechn_moegl,3-Praediktion_war_unzutreffend,4-res,5-res,6-Init,7-Fehler
SoH_C:              7B;0..125%; Faktor:1; 7E-Init, 7F-Fehler
Spannung:        12B;0..6,141V; Faktor:0";
CM_ SG_ 2527679939 BDM_ZellStatus_Typ_2 "Multiplexindex einzelner Zell-/ Status-Informationen LiIon-Starterbatterie";
CM_ SG_ 2527679939 BDM_ZellTechnologie_2 "Werte werden von Li-Batterie übermittelt";
CM_ SG_ 2527679939 BDMs_LiIon2_BZ "4bit Botschaftszähler, wird mit jeder Sendebotschaft inkrementiert";
CM_ SG_ 2527679939 BDMs_LiIon2_CRC "Für MLB:
Berechnung siehe Lastenheft 'Kommunikationsabsicherung für FlexRay und CAN'
Ab MQB und MLBevo:
Berechnung siehe Lastenheft 'End-to-End Kommunikationsabsicherung'

Endwerte siehe Begleitdokument 'S-PDU Kennungsfolgen'";
CM_ SG_ 2527679939 BZE_Q_FuSi "Charge for FuSi Pulse";
CM_ SG_ 2527679939 BZE_Qe_Bereich_2 "Für BDM an KFG: Erweiterung des Wertebereichs des aktuell gültigen Signals BZE_Qe";
CM_ SG_ 2527679939 BZE_SOF_3Pol "ASIL_C_Warnung des LiIon - 3 Pols";
CM_ SG_ 2527679939 BZE_ZwangGrund "LiFePO Grund der Vorwarnung";

CM_ SG_ 869 BEM_Anf_KL "Das BEM fordert über das MSG den Kühlerlüfter-Betrieb an; hierzu wird ein minimaler Leistungswert im MSG appliziert. 
Szenario: bei erkannter abgetrennten Batterie soll durch Ansteuerung des Kühlerlüfters das Energienetz stabilisiert werden.";
CM_ SG_ 869 BEM_Batt_Ab "Batterieverbindungskontrolle:
0x0: Batterie am Bordnetz
0x1: Batterie ab erkannt";
CM_ SG_ 869 BEM_DFM "Generatorauslastungsgrad, vom Generator über LIN an das Gateway gesandt. Das Motorsteuergerät regelt auf dieses Signal die PTC, das Energiemanagement im BSG/BCM kalkuliert die Bordnetzauslastung";
CM_ SG_ 869 BEM_EMLIN_ungueltig "Energie-Lin - Signale sind ungültig vom Slave Batteriedatenmodul oder Generator
0 = Signale gültig
1 = Signale ungültig";
CM_ SG_ 869 BEM_HYB_DC_uMinLV "Abregelgrenze: minimal erlaubte Bordnetzspannung im Hochsetzbetrieb (Hybrid)";
CM_ SG_ 869 BEM_HYB_DC_uSollLV "Sollwert für die Bordnetzspannung im Tiefsetzbetrieb vom Traktionsnetz ins Bordnetz (Hybrid)";
CM_ SG_ 869 BEM_n_LLA "Es gilt: Signalspec BEM_n_LLA v1.0

Anforderung einer Leerlaufdrehzahlanhebung in drei Stufen. Die Höhe der jeweiligen LL-Drehzahlstufe ist im Motorsteuergerät appliziert.



";
CM_ SG_ 869 BEM_P_Generator "Es gilt: Signalspec BEM_P_Generator v1.0

Mechanische Generatorleistung dient dem Motorsteuergerät zur Berechnung der Motorlast; Genauigkeit ca. +/- (500W + 20% vom Messwert)

MLBevo: Bei NVEM_P_Generator_Status = 1 wird das Signal ohne Filterung ausg";
CM_ SG_ 869 BEM_Segel_Info "0: keine Anforderung 
(Segeln ist ohne Einschänkung erlaubt)
1: Mindestdrehzahl 1 
(Segeln ist mit Einschänkung erlaubt)
2: Mindestdrehzahl 2
(Segeln ist mit Einschänkung erlaubt)
3: Segelveto
(Segeln ist nicht  erlaubt)";
CM_ SG_ 869 BEM_StartStopp_Info "Stopp-Freigabe und Start-Anforderung an den Start-Stopp-Koordinator";
CM_ SG_ 869 BEM_UBDM "Batteriespannung, gemessen vom Batteriedatenmodul";
CM_ SG_ 869 NVEM_Abschaltstufe "Abschaltstufe aus dem Ruheenergiemanagement
Maßnahmen des Empfängers werden im QLAH Ruhestrommanagement definiert";
CM_ SG_ 869 NVEM_FMAus_I_Verbrauch "Predezierter Bordneztstromverbrauch während der Freilauf Motor Aus Phase.";
CM_ SG_ 869 NVEM_FMAus_Info "Freilauf Informationssignal zum Freilaufkoordinator. 
Gilt nur für die Freilauf Phase. Verwendung im MicroHybrid.";
CM_ SG_ 869 NVEM_Freilauf_Info "Freilauf Informationssignal vom NVEM zum Freilaufkoordinator. Das NVEM kann über dieses Signal den Freilauf freigeben, verhindern bzw. explizit anfordern.";
CM_ SG_ 869 NVEM_Ladefreigabe "Freigabeemfehlung zur Ladung des FMA-Zusatzspeichers";
CM_ SG_ 869 NVEM_P_Generator_Status "Das Signal kennzeichnet ob BEM_P_Generator aktuell gefilterte oder ungefilterte Werte überträgt.";
CM_ SG_ 869 NVEM_PTC_Sollstufe "Vorgabe des BEM an das BCM zur Aktivierung der geforderten PTC - Stufe.
Das MSG kopiert dies auf das Signal MO_PTC_Status";
CM_ SG_ 869 NVEM_Red_KL "Reduzierung der Kühlerlüfteranforderung durch das NVEM an das MSG bei energetisch kritischen Zuständen während Staupilot";

CM_ SG_ 1163 BEM_06_BZ "4bit Botschaftszähler, wird mit jeder Sendebotschaft inkrementiert";
CM_ SG_ 1163 BEM_06_CRC "Für MLB:
Berechnung siehe Lastenheft 'Kommunikationsabsicherung für FlexRay und CAN'
Ab MQB und MLBevo:
Berechnung siehe Lastenheft 'End-to-End Kommunikationsabsicherung'

Endwerte siehe Begleitdokument 'S-PDU Kennungsfolgen'";
CM_ SG_ 1163 HLR_PTC_linear_Freigabe "Freigabe des EEM für den linearen PTC-Zuheizer";
CM_ SG_ 1163 NVEM2_Status_FuSiFahrt "Status sicherheitsrelevante Diagnosen NVEM";
CM_ SG_ 1163 NVEM2_Typ_EnergieNetz "Identifizierte NV-Energiearchitektur";
CM_ SG_ 1163 NVEM_Betriebsart "Betriebsart des Niedervolt - Energiemanagements";
CM_ SG_ 1163 NVEM_Bordnetzdiagnose "Wird vom NVEM im NV-Netz ein Bordnetz-Fehler erkannt, so soll dies zu einer mehrstufigen Anzeige führen.";
CM_ SG_ 1163 NVEM_Energie_Klima_Vorgabe "NVEM-Energievorgabe für Klima-Vorkonditionierung";
CM_ SG_ 1163 NVEM_Energienetz_Status "NVEM kommuniziert abgesichert den Zustand des Energienetzes.";
CM_ SG_ 1163 NVEM_Ladezustand "Ladezustand des NV-Hauptspeichers.";
CM_ SG_ 1163 NVEM_Last_Anf "Das NVEM fordert für die Batteriediagnose einen Lastimpuls vom Fahrzeug an, der durch kontrollierte Verbraucherzuschaltungen (z. B. Aktivierung Heckscheibenheizung) generiert wird";
CM_ SG_ 1163 NVEM_PTC_Sollstufe "Vorgabe des BEM an das BCM zur Aktivierung der geforderten PTC - Stufe.
Das MSG kopiert dies auf das Signal MO_PTC_Status";
CM_ SG_ 1163 NVEM_Red_KomfortVerbrauch "Master - SubMaster Kommunikation";
CM_ SG_ 1163 NVEM_STH_ZielzeitLang "Energetisch erlaubte Betriebszeit im Zielzeitkonzept für Standheizungen mit 2 Stunden Laufzeit";
CM_ SG_ 1163 NVEM_Vorgabe_Leistungsstufe "Ermittelte Leistungsstufe der Energiequelle";

BA_DEF_  "DBName" STRING;
BA_DEF_  "GenNWMApBusSleep" STRING;
BA_DEF_  "GenNWMApCanNormal" STRING;
BA_DEF_  "GenNWMApCanOff" STRING;
BA_DEF_  "GenNWMApCanOn" STRING;
BA_DEF_  "GenNWMApCanSleep" STRING;
BA_DEF_  "GenNWMApCanWakeUp" STRING;
BA_DEF_  "GenNWMGotoMode_Awake" STRING;
BA_DEF_  "GenNWMGotoMode_BusSleep" STRING;
BA_DEF_  "GenNWMSleepTime" INT 0 1000000;
BA_DEF_  "GenNWMTalkNM" STRING;
BA_DEF_  "Manufacturer" STRING;
BA_DEF_  "NmhBaseAddress" HEX 0 536870911;
BA_DEF_  "NmhMessageCount" INT 0 1024;
BA_DEF_  "NmType" STRING;
BA_DEF_  "VAGTP20_SetupMessageCount" INT 0 255;
BA_DEF_  "VAGTP20_SetupStartAddress" HEX 0 2047;
BA_DEF_  "VersionDay" INT 1 31;
BA_DEF_  "VersionMonth" INT 1 12;
BA_DEF_  "VersionWeek" INT 1 52;
BA_DEF_  "VersionYear" INT 0 99;
BA_DEF_  "VersionNumber" INT 0 65535;
BA_DEF_  "BusType" STRING;
BA_DEF_  "Baudrate" INT 1 1000000;
BA_DEF_  "BaudrateCANFD" INT 1 16000000;
BA_DEF_  "NmhTimeoutTimer" INT 0 65535;
BA_DEF_  "NmhWaitBusSleepTimer" INT 0 65535;
BA_DEF_  "NmhPrepareBusSleepTimer" INT 0 65535;
BA_DEF_  "NmhLongTimer" INT 0 65535;
BA_DEF_  "NmhNStart" INT 0 255;
BA_DEF_ BU_  "GenNodAutoGenDsp" ENUM "No", "Yes";
BA_DEF_ BU_  "GenNodAutoGenSnd" ENUM "No", "Yes";
BA_DEF_ BU_  "GenNodSleepTime" INT 0 1000000;
BA_DEF_ BU_  "ILUsed" ENUM "No", "Yes";
BA_DEF_ BU_  "ECUVariantDefault" ENUM "No", "Yes";
BA_DEF_ BU_  "ECUVariantGroup" STRING;
BA_DEF_ BU_  "NodeLayerModules" STRING;
BA_DEF_ BU_  "NmhNode" ENUM "No", "Yes";
BA_DEF_ BU_  "NmNode" ENUM "No", "Yes";
BA_DEF_ BU_  "SamplePointMin" FLOAT 50.0 99.9;
BA_DEF_ BU_  "SamplePointMax" FLOAT 50.0 99.9;
BA_DEF_ BU_  "SyncJumpWidthMin" FLOAT 0.0 50.0;
BA_DEF_ BU_  "SyncJumpWidthMax" FLOAT 0.0 50.0;
BA_DEF_ BU_  "SyncJumpWidthCANFDMin" FLOAT 0.0 50.0;
BA_DEF_ BU_  "SyncJumpWidthCANFDMax" FLOAT 0.0 50.0;
BA_DEF_ BU_  "SamplePointCANFDMin" FLOAT 50.0 99.9;
BA_DEF_ BU_  "SamplePointCANFDMax" FLOAT 50.0 99.9;
BA_DEF_ BU_  "SSPOffsetCANFDMin" FLOAT 50.0 99.9;
BA_DEF_ BU_  "SSPOffsetCANFDMax" FLOAT 50.0 99.9;
BA_DEF_ BU_  "TimeQuantaMin" INT 4 257;
BA_DEF_ BU_  "TimeQuantaMax" INT 4 257;
BA_DEF_ BU_  "TimeQuantaCANFDMin" INT 4 257;
BA_DEF_ BU_  "TimeQuantaCANFDMax" INT 4 257;
BA_DEF_REL_ BU_SG_REL_  "GenSigTimeoutTime" INT 0 65535;
BA_DEF_ BO_  "DiagRequest" ENUM "No", "Yes";
BA_DEF_ BO_  "DiagResponse" ENUM "No", "Yes";
BA_DEF_ BO_  "DiagState" ENUM "No", "Yes";
BA_DEF_ BO_  "GenMsgChkConstant" HEX 0 4095;
BA_DEF_ BO_  "GenMsgCycleTime" INT 0 65535;
BA_DEF_ BO_  "GenMsgCycleTimeFast" INT 0 65535;
BA_DEF_ BO_  "GenMsgDelayTime" INT 0 100000;
BA_DEF_ BO_  "GenMsgILSupport" ENUM "No", "Yes";
BA_DEF_ BO_  "GenMsgNrOfRepetition" INT 0 100;
BA_DEF_ BO_  "GenMsgPDUConstants" STRING;
BA_DEF_ BO_  "GenMsgSendType" ENUM "Cyclic", "not_used", "not_used", "not_used", "not_used", "not_used", "not_used", "IfActive", "NoMsgSendType";
BA_DEF_ BO_  "GenMsgStartDelayTime" INT 0 100000;
BA_DEF_ BO_  "NmMessage" ENUM "No", "Yes";
BA_DEF_ BO_  "NmhMessage" ENUM "No", "Yes";
BA_DEF_ BO_  "MsgType" ENUM "Application", "NM ", "NMH", "TP2.0", "ISO-TP ", "BAP", "EID", "KS", "XCP_PRE_CONFIGURED", "XCP_RUNTIME_CONFIGURED";
BA_DEF_ BO_  "VAGTP20_API" HEX 0 255;
BA_DEF_ BO_  "VAGTP20_DynConnection" ENUM "No", "Yes";
BA_DEF_ BO_  "VAGTP20_DynSetup" ENUM "No", "Yes";
BA_DEF_ BO_  "VAGTP20_StatConnection" ENUM "No", "Yes";
BA_DEF_ BO_  "CANFD_BRS" ENUM "0", "1";
BA_DEF_ BO_  "VFrameFormat" ENUM "StandardCAN", "ExtendedCAN", "reserved", "reserved", "reserved", "reserved", "reserved", "reserved", "reserved", "reserved", "reserved", "reserved", "reserved", "reserved", "StandardCAN_FD", "ExtendedCAN_FD";
BA_DEF_ SG_  "GenSigActiveRepetitions" INT -2147483648 2147483647;
BA_DEF_ SG_  "GenSigInactiveValue" INT -2147483648 2147483647;
BA_DEF_ SG_  "GenSigSendType" ENUM "Cyclic", "OnWrite", "OnWriteWithRepetition", "OnChange", "OnChangeWithRepetition", "IfActive", "IfActiveWithRepetition", "NoSigSendType", "OnChangeAndIfActive", "OnChangeAndIfActiveWithRepetition";
BA_DEF_ SG_  "GenSigStartValue" INT -2147483648 2147483647;
BA_DEF_ SG_  "NWM-WakeupAllowed" ENUM "No", "Yes";
BA_DEF_ SG_  "GenSigFuncType" ENUM "NoFunction", "MsgCounter", "CRC-8", "XOR", "XOR-2", "DatedBit", "SW-Kl15", "CHK", "Constant", "Protocol", "CRC-8-SAE_J1850", "CRC-32", "DataLength", "DataID", "MsgCounter16", "SOK-Signatur", "Cluster";
BA_DEF_ SG_  "GenSigSwitchedByIgnition" ENUM "No", "Yes";
BA_DEF_ SG_  "Fehlerwert" HEX 0 2147483647;
BA_DEF_ SG_  "GenSigMissingSourceValue" HEX 0 2147483647;
BA_DEF_DEF_  "DBName" "";
BA_DEF_DEF_  "GenNWMApBusSleep" "";
BA_DEF_DEF_  "GenNWMApCanNormal" "";
BA_DEF_DEF_  "GenNWMApCanOff" "";
BA_DEF_DEF_  "GenNWMApCanOn" "";
BA_DEF_DEF_  "GenNWMApCanSleep" "";
BA_DEF_DEF_  "GenNWMApCanWakeUp" "";
BA_DEF_DEF_  "GenNWMGotoMode_Awake" "";
BA_DEF_DEF_  "GenNWMGotoMode_BusSleep" "";
BA_DEF_DEF_  "GenNWMSleepTime" 0;
BA_DEF_DEF_  "GenNWMTalkNM" "";
BA_DEF_DEF_  "Manufacturer" "";
BA_DEF_DEF_  "NmhBaseAddress" 0;
BA_DEF_DEF_  "NmhMessageCount" 1;
BA_DEF_DEF_  "NmType" "None";
BA_DEF_DEF_  "VAGTP20_SetupMessageCount" 0;
BA_DEF_DEF_  "VAGTP20_SetupStartAddress" 0;
BA_DEF_DEF_  "VersionDay" 12;
BA_DEF_DEF_  "VersionMonth" 6;
BA_DEF_DEF_  "VersionWeek" 24;
BA_DEF_DEF_  "VersionYear" 23;
BA_DEF_DEF_  "VersionNumber" 0;
BA_DEF_DEF_  "BusType" "";
BA_DEF_DEF_  "Baudrate" 500000;
BA_DEF_DEF_  "BaudrateCANFD" 2000000;
BA_DEF_DEF_  "NmhTimeoutTimer" 0;
BA_DEF_DEF_  "NmhWaitBusSleepTimer" 0;
BA_DEF_DEF_  "NmhPrepareBusSleepTimer" 0;
BA_DEF_DEF_  "NmhLongTimer" 0;
BA_DEF_DEF_  "NmhNStart" 0;
BA_DEF_DEF_  "GenNodAutoGenDsp" "Yes";
BA_DEF_DEF_  "GenNodAutoGenSnd" "Yes";
BA_DEF_DEF_  "GenNodSleepTime" 0;
BA_DEF_DEF_  "ILUsed" "Yes";
BA_DEF_DEF_  "ECUVariantDefault" "Yes";
BA_DEF_DEF_  "ECUVariantGroup" "";
BA_DEF_DEF_  "NodeLayerModules" "";
BA_DEF_DEF_  "NmhNode" "Yes";
BA_DEF_DEF_  "NmNode" "No";
BA_DEF_DEF_  "SamplePointMin" 75;
BA_DEF_DEF_  "SamplePointMax" 75;
BA_DEF_DEF_  "SyncJumpWidthMin" 50;
BA_DEF_DEF_  "SyncJumpWidthMax" 50;
BA_DEF_DEF_  "SyncJumpWidthCANFDMin" 50;
BA_DEF_DEF_  "SyncJumpWidthCANFDMax" 50;
BA_DEF_DEF_  "SamplePointCANFDMin" 75;
BA_DEF_DEF_  "SamplePointCANFDMax" 75;
BA_DEF_DEF_  "SSPOffsetCANFDMin" 75;
BA_DEF_DEF_  "SSPOffsetCANFDMax" 75;
BA_DEF_DEF_  "TimeQuantaMin" 160;
BA_DEF_DEF_  "TimeQuantaMax" 160;
BA_DEF_DEF_  "TimeQuantaCANFDMin" 40;
BA_DEF_DEF_  "TimeQuantaCANFDMax" 40;
BA_DEF_DEF_REL_  "GenSigTimeoutTime" 0;
BA_DEF_DEF_  "DiagRequest" "No";
BA_DEF_DEF_  "DiagResponse" "No";
BA_DEF_DEF_  "DiagState" "No";
BA_DEF_DEF_  "GenMsgChkConstant" 0;
BA_DEF_DEF_  "GenMsgCycleTime" 0;
BA_DEF_DEF_  "GenMsgCycleTimeFast" 0;
BA_DEF_DEF_  "GenMsgDelayTime" 0;
BA_DEF_DEF_  "GenMsgILSupport" "No";
BA_DEF_DEF_  "GenMsgNrOfRepetition" 0;
BA_DEF_DEF_  "GenMsgPDUConstants" "";
BA_DEF_DEF_  "GenMsgSendType" "NoMsgSendType";
BA_DEF_DEF_  "GenMsgStartDelayTime" 0;
BA_DEF_DEF_  "NmMessage" "No";
BA_DEF_DEF_  "NmhMessage" "No";
BA_DEF_DEF_  "MsgType" "Application";
BA_DEF_DEF_  "VAGTP20_API" 0;
BA_DEF_DEF_  "VAGTP20_DynConnection" "No";
BA_DEF_DEF_  "VAGTP20_DynSetup" "No";
BA_DEF_DEF_  "VAGTP20_StatConnection" "No";
BA_DEF_DEF_  "CANFD_BRS" "1";
BA_DEF_DEF_  "VFrameFormat" "StandardCAN";
BA_DEF_DEF_  "GenSigActiveRepetitions" 0;
BA_DEF_DEF_  "GenSigInactiveValue" 0;
BA_DEF_DEF_  "GenSigSendType" "NoSigSendType";
BA_DEF_DEF_  "GenSigStartValue" 0;
BA_DEF_DEF_  "NWM-WakeupAllowed" "No";
BA_DEF_DEF_  "GenSigFuncType" "NoFunction";
BA_DEF_DEF_  "GenSigSwitchedByIgnition" "Yes";
BA_DEF_DEF_  "Fehlerwert" 0;
BA_DEF_DEF_  "GenSigMissingSourceValue" 0;
BA_  "DBName" "FCANFD1";
BA_  "GenNWMApBusSleep" "NMIndNetSDN()";
BA_  "GenNWMApCanNormal" "apCanNormal()";
BA_  "GenNWMApCanOff" "NMIndnetOff()";
BA_  "GenNWMApCanOn" "NMIndnetOn()";
BA_  "GenNWMApCanSleep" "apCanSleep()";
BA_  "GenNWMApCanWakeUp" "apCanWakeUp()";
BA_  "GenNWMGotoMode_Awake" "Nmh_ReqNetOn()";
BA_  "GenNWMGotoMode_BusSleep" "Nmh_ReqNetOff()";
BA_  "GenNWMSleepTime" 4000;
BA_  "GenNWMTalkNM" "Nmh_ReqNetOn()";
BA_  "Manufacturer" "VAG";
BA_  "NmhBaseAddress" 452984832;
BA_  "NmhMessageCount" 1024;
BA_  "NmType" "NM-High";
BA_  "VAGTP20_SetupMessageCount" 128;
BA_  "VAGTP20_SetupStartAddress" 512;
BA_  "VersionNumber" 9;
BA_  "BusType" "CAN FD";
BA_  "NmhTimeoutTimer" 1000;
BA_  "NmhWaitBusSleepTimer" 750;
BA_  "NmhPrepareBusSleepTimer" 500;
BA_  "NmhLongTimer" 200;
BA_  "NmhNStart" 20;
BA_ "GenNodSleepTime" BU_ Airbag 4000;
BA_ "NodeLayerModules" BU_ Airbag "NMHigh.DLL";
BA_ "SamplePointMin" BU_ Airbag 80;
BA_ "SamplePointMax" BU_ Airbag 80;
BA_ "SyncJumpWidthMin" BU_ Airbag 16;
BA_ "SyncJumpWidthMax" BU_ Airbag 16;
BA_ "SyncJumpWidthCANFDMin" BU_ Airbag 6;
BA_ "SyncJumpWidthCANFDMax" BU_ Airbag 6;
BA_ "SamplePointCANFDMin" BU_ Airbag 70;
BA_ "SamplePointCANFDMax" BU_ Airbag 70;
BA_ "SSPOffsetCANFDMin" BU_ Airbag 70;
BA_ "SSPOffsetCANFDMax" BU_ Airbag 70;
BA_ "TimeQuantaMin" BU_ Airbag 80;
BA_ "TimeQuantaMax" BU_ Airbag 80;
BA_ "TimeQuantaCANFDMin" BU_ Airbag 20;
BA_ "TimeQuantaCANFDMax" BU_ Airbag 20;
BA_ "GenNodSleepTime" BU_ Allrad_Haldex 4000;
BA_ "ECUVariantGroup" BU_ Allrad_Haldex "Allrad";
BA_ "NmhNode" BU_ Allrad_Haldex 0;
BA_ "SamplePointMin" BU_ Allrad_Haldex 80;
BA_ "SamplePointMax" BU_ Allrad_Haldex 80;
BA_ "SyncJumpWidthMin" BU_ Allrad_Haldex 16;
BA_ "SyncJumpWidthMax" BU_ Allrad_Haldex 16;
BA_ "SyncJumpWidthCANFDMin" BU_ Allrad_Haldex 6;
BA_ "SyncJumpWidthCANFDMax" BU_ Allrad_Haldex 6;
BA_ "SamplePointCANFDMin" BU_ Allrad_Haldex 70;
BA_ "SamplePointCANFDMax" BU_ Allrad_Haldex 70;
BA_ "SSPOffsetCANFDMin" BU_ Allrad_Haldex 70;
BA_ "SSPOffsetCANFDMax" BU_ Allrad_Haldex 70;
BA_ "TimeQuantaMin" BU_ Allrad_Haldex 80;
BA_ "TimeQuantaMax" BU_ Allrad_Haldex 80;
BA_ "TimeQuantaCANFDMin" BU_ Allrad_Haldex 20;
BA_ "TimeQuantaCANFDMax" BU_ Allrad_Haldex 20;
BA_ "GenNodSleepTime" BU_ BAP_Tester 4000;
BA_ "ECUVariantGroup" BU_ BAP_Tester "BAP";
BA_ "NmhNode" BU_ BAP_Tester 0;
BA_ "SamplePointMin" BU_ BAP_Tester 80;
BA_ "SamplePointMax" BU_ BAP_Tester 80;
BA_ "SyncJumpWidthMin" BU_ BAP_Tester 16;
BA_ "SyncJumpWidthMax" BU_ BAP_Tester 16;
BA_ "SyncJumpWidthCANFDMin" BU_ BAP_Tester 6;
BA_ "SyncJumpWidthCANFDMax" BU_ BAP_Tester 6;
BA_ "SamplePointCANFDMin" BU_ BAP_Tester 70;
BA_ "SamplePointCANFDMax" BU_ BAP_Tester 70;
BA_ "SSPOffsetCANFDMin" BU_ BAP_Tester 70;
BA_ "SSPOffsetCANFDMax" BU_ BAP_Tester 70;
BA_ "TimeQuantaMin" BU_ BAP_Tester 80;
BA_ "TimeQuantaMax" BU_ BAP_Tester 80;
BA_ "TimeQuantaCANFDMin" BU_ BAP_Tester 20;
BA_ "TimeQuantaCANFDMax" BU_ BAP_Tester 20;
BA_ "GenNodSleepTime" BU_ DCC_Gen3 4000;
BA_ "ECUVariantGroup" BU_ DCC_Gen3 "Daempfer";
BA_ "NodeLayerModules" BU_ DCC_Gen3 "NMHigh.DLL";
BA_ "SamplePointMin" BU_ DCC_Gen3 80;
BA_ "SamplePointMax" BU_ DCC_Gen3 80;
BA_ "SyncJumpWidthMin" BU_ DCC_Gen3 16;
BA_ "SyncJumpWidthMax" BU_ DCC_Gen3 16;
BA_ "SyncJumpWidthCANFDMin" BU_ DCC_Gen3 6;
BA_ "SyncJumpWidthCANFDMax" BU_ DCC_Gen3 6;
BA_ "SamplePointCANFDMin" BU_ DCC_Gen3 70;
BA_ "SamplePointCANFDMax" BU_ DCC_Gen3 70;
BA_ "SSPOffsetCANFDMin" BU_ DCC_Gen3 70;
BA_ "SSPOffsetCANFDMax" BU_ DCC_Gen3 70;
BA_ "TimeQuantaMin" BU_ DCC_Gen3 80;
BA_ "TimeQuantaMax" BU_ DCC_Gen3 80;
BA_ "TimeQuantaCANFDMin" BU_ DCC_Gen3 20;
BA_ "TimeQuantaCANFDMax" BU_ DCC_Gen3 20;
BA_ "GenNodSleepTime" BU_ EBKV_MQBW 4000;
BA_ "ECUVariantGroup" BU_ EBKV_MQBW "EBKV";
BA_ "NodeLayerModules" BU_ EBKV_MQBW "NMHigh.DLL";
BA_ "SamplePointMin" BU_ EBKV_MQBW 80;
BA_ "SamplePointMax" BU_ EBKV_MQBW 80;
BA_ "SyncJumpWidthMin" BU_ EBKV_MQBW 16;
BA_ "SyncJumpWidthMax" BU_ EBKV_MQBW 16;
BA_ "SyncJumpWidthCANFDMin" BU_ EBKV_MQBW 6;
BA_ "SyncJumpWidthCANFDMax" BU_ EBKV_MQBW 6;
BA_ "SamplePointCANFDMin" BU_ EBKV_MQBW 70;
BA_ "SamplePointCANFDMax" BU_ EBKV_MQBW 70;
BA_ "SSPOffsetCANFDMin" BU_ EBKV_MQBW 70;
BA_ "SSPOffsetCANFDMax" BU_ EBKV_MQBW 70;
BA_ "TimeQuantaMin" BU_ EBKV_MQBW 80;
BA_ "TimeQuantaMax" BU_ EBKV_MQBW 80;
BA_ "TimeQuantaCANFDMin" BU_ EBKV_MQBW 20;
BA_ "TimeQuantaCANFDMax" BU_ EBKV_MQBW 20;
BA_ "GenNodSleepTime" BU_ ESC_MQBW 4000;
BA_ "ECUVariantGroup" BU_ ESC_MQBW "Bremse";
BA_ "NodeLayerModules" BU_ ESC_MQBW "NMHigh.DLL";
BA_ "SamplePointMin" BU_ ESC_MQBW 80;
BA_ "SamplePointMax" BU_ ESC_MQBW 80;
BA_ "SyncJumpWidthMin" BU_ ESC_MQBW 16;
BA_ "SyncJumpWidthMax" BU_ ESC_MQBW 16;
BA_ "SyncJumpWidthCANFDMin" BU_ ESC_MQBW 6;
BA_ "SyncJumpWidthCANFDMax" BU_ ESC_MQBW 6;
BA_ "SamplePointCANFDMin" BU_ ESC_MQBW 70;
BA_ "SamplePointCANFDMax" BU_ ESC_MQBW 70;
BA_ "SSPOffsetCANFDMin" BU_ ESC_MQBW 70;
BA_ "SSPOffsetCANFDMax" BU_ ESC_MQBW 70;
BA_ "TimeQuantaMin" BU_ ESC_MQBW 80;
BA_ "TimeQuantaMax" BU_ ESC_MQBW 80;
BA_ "TimeQuantaCANFDMin" BU_ ESC_MQBW 20;
BA_ "TimeQuantaCANFDMax" BU_ ESC_MQBW 20;
BA_ "GenNodSleepTime" BU_ Gateway_Max 4000;
BA_ "ECUVariantGroup" BU_ Gateway_Max "Gateway";
BA_ "NodeLayerModules" BU_ Gateway_Max "NMHigh.DLL";
BA_ "SamplePointMin" BU_ Gateway_Max 80;
BA_ "SamplePointMax" BU_ Gateway_Max 80;
BA_ "SyncJumpWidthMin" BU_ Gateway_Max 16;
BA_ "SyncJumpWidthMax" BU_ Gateway_Max 16;
BA_ "SyncJumpWidthCANFDMin" BU_ Gateway_Max 6;
BA_ "SyncJumpWidthCANFDMax" BU_ Gateway_Max 6;
BA_ "SamplePointCANFDMin" BU_ Gateway_Max 70;
BA_ "SamplePointCANFDMax" BU_ Gateway_Max 70;
BA_ "SSPOffsetCANFDMin" BU_ Gateway_Max 70;
BA_ "SSPOffsetCANFDMax" BU_ Gateway_Max 70;
BA_ "TimeQuantaMin" BU_ Gateway_Max 80;
BA_ "TimeQuantaMax" BU_ Gateway_Max 80;
BA_ "TimeQuantaCANFDMin" BU_ Gateway_Max 20;
BA_ "TimeQuantaCANFDMax" BU_ Gateway_Max 20;
BA_ "GenNodSleepTime" BU_ Lenkhilfe_REPS 4000;
BA_ "ECUVariantGroup" BU_ Lenkhilfe_REPS "Lenkhilfe";
BA_ "NodeLayerModules" BU_ Lenkhilfe_REPS "NMHigh.DLL";
BA_ "SamplePointMin" BU_ Lenkhilfe_REPS 80;
BA_ "SamplePointMax" BU_ Lenkhilfe_REPS 80;
BA_ "SyncJumpWidthMin" BU_ Lenkhilfe_REPS 16;
BA_ "SyncJumpWidthMax" BU_ Lenkhilfe_REPS 16;
BA_ "SyncJumpWidthCANFDMin" BU_ Lenkhilfe_REPS 6;
BA_ "SyncJumpWidthCANFDMax" BU_ Lenkhilfe_REPS 6;
BA_ "SamplePointCANFDMin" BU_ Lenkhilfe_REPS 70;
BA_ "SamplePointCANFDMax" BU_ Lenkhilfe_REPS 70;
BA_ "SSPOffsetCANFDMin" BU_ Lenkhilfe_REPS 70;
BA_ "SSPOffsetCANFDMax" BU_ Lenkhilfe_REPS 70;
BA_ "TimeQuantaMin" BU_ Lenkhilfe_REPS 80;
BA_ "TimeQuantaMax" BU_ Lenkhilfe_REPS 80;
BA_ "TimeQuantaCANFDMin" BU_ Lenkhilfe_REPS 20;
BA_ "TimeQuantaCANFDMax" BU_ Lenkhilfe_REPS 20;
BA_ "GenMsgCycleTime" BO_ 333 20;
BA_ "GenMsgILSupport" BO_ 333 1;
BA_ "GenMsgPDUConstants" BO_ 333 "0x1a,0x65,0x81,0x96,0xc0,0xdf,0x11,0x92,0xd3,0x61,0xc6,0x95,0x8c,0x29,0x21,0xb5";
BA_ "GenMsgSendType" BO_ 333 0;
BA_ "VFrameFormat" BO_ 333 14;
BA_ "GenMsgCycleTime" BO_ 2527679682 2000;
BA_ "GenMsgDelayTime" BO_ 2527679682 100;
BA_ "GenMsgILSupport" BO_ 2527679682 1;
BA_ "GenMsgSendType" BO_ 2527679682 0;
BA_ "VFrameFormat" BO_ 2527679682 15;
BA_ "GenMsgChkConstant" BO_ 64 64;
BA_ "GenMsgCycleTime" BO_ 64 40;
BA_ "GenMsgCycleTimeFast" BO_ 64 10;
BA_ "GenMsgDelayTime" BO_ 64 10;
BA_ "GenMsgILSupport" BO_ 64 1;
BA_ "GenMsgNrOfRepetition" BO_ 64 5;
BA_ "GenMsgPDUConstants" BO_ 64 "0x40,0x40,0x40,0x40,0x40,0x40,0x40,0x40,0x40,0x40,0x40,0x40,0x40,0x40,0x40,0x40";
BA_ "GenMsgSendType" BO_ 64 0;
BA_ "VFrameFormat" BO_ 64 14;
BA_ "GenMsgCycleTime" BO_ 2589283872 1000;
BA_ "GenMsgILSupport" BO_ 2589283872 1;
BA_ "GenMsgSendType" BO_ 2589283872 0;
BA_ "VFrameFormat" BO_ 2589283872 15;
BA_ "GenMsgCycleTime" BO_ 2589283873 1000;
BA_ "GenMsgILSupport" BO_ 2589283873 1;
BA_ "GenMsgSendType" BO_ 2589283873 0;
BA_ "VFrameFormat" BO_ 2589283873 15;
BA_ "GenMsgChkConstant" BO_ 1312 68;
BA_ "GenMsgCycleTime" BO_ 1312 200;
BA_ "GenMsgDelayTime" BO_ 1312 20;
BA_ "GenMsgILSupport" BO_ 1312 1;
BA_ "GenMsgPDUConstants" BO_ 1312 "0x44,0x44,0x44,0x44,0x44,0x44,0x44,0x44,0x44,0x44,0x44,0x44,0x44,0x44,0x44,0x44";
BA_ "GenMsgSendType" BO_ 1312 0;
BA_ "VFrameFormat" BO_ 1312 14;
BA_ "GenMsgCycleTime" BO_ 65 1000;
BA_ "GenMsgCycleTimeFast" BO_ 65 10;
BA_ "GenMsgDelayTime" BO_ 65 10;
BA_ "GenMsgILSupport" BO_ 65 1;
BA_ "GenMsgNrOfRepetition" BO_ 65 5;
BA_ "GenMsgPDUConstants" BO_ 65 "0x93,0xb0,0x9d,0xf1,0x09,0xe8,0x88,0x5e,0x36,0xfa,0xa8,0xa1,0x67,0x84,0xca,0x4f";
BA_ "GenMsgSendType" BO_ 65 0;
BA_ "VFrameFormat" BO_ 65 14;
BA_ "GenMsgCycleTime" BO_ 1349 200;
BA_ "GenMsgDelayTime" BO_ 1349 40;
BA_ "GenMsgILSupport" BO_ 1349 1;
BA_ "GenMsgPDUConstants" BO_ 1349 "0x95,0x19,0xd1,0x36,0x89,0xd4,0x02,0x1e,0xb9,0x80,0xd0,0x22,0x8a,0xf4,0x15,0xb8";
BA_ "GenMsgSendType" BO_ 1349 0;
BA_ "VFrameFormat" BO_ 1349 14;
BA_ "GenMsgCycleTime" BO_ 2527679722 200;
BA_ "GenMsgILSupport" BO_ 2527679722 1;
BA_ "GenMsgPDUConstants" BO_ 2527679722 "0x81,0x55,0xf0,0x94,0x56,0x5f,0xa4,0x5c,0x2f,0x61,0x48,0x01,0xf8,0xd7,0x33,0x87";
BA_ "GenMsgSendType" BO_ 2527679722 0;
BA_ "VFrameFormat" BO_ 2527679722 15;
BA_ "GenMsgCycleTime" BO_ 63 40;
BA_ "GenMsgCycleTimeFast" BO_ 63 10;
BA_ "GenMsgDelayTime" BO_ 63 10;
BA_ "GenMsgILSupport" BO_ 63 1;
BA_ "GenMsgNrOfRepetition" BO_ 63 5;
BA_ "GenMsgPDUConstants" BO_ 63 "0xe1,0x9e,0xc2,0xe9,0x48,0x98,0xf5,0xb6,0x47,0x83,0x26,0x45,0x9a,0x10,0x7b,0x1c";
BA_ "GenMsgSendType" BO_ 63 0;
BA_ "VFrameFormat" BO_ 63 14;
BA_ "GenMsgCycleTime" BO_ 280 100;
BA_ "GenMsgCycleTimeFast" BO_ 280 10;
BA_ "GenMsgDelayTime" BO_ 280 10;
BA_ "GenMsgILSupport" BO_ 280 1;
BA_ "GenMsgNrOfRepetition" BO_ 280 5;
BA_ "GenMsgSendType" BO_ 280 0;
BA_ "VFrameFormat" BO_ 280 14;
BA_ "GenMsgCycleTime" BO_ 308 20;
BA_ "GenMsgILSupport" BO_ 308 1;
BA_ "GenMsgSendType" BO_ 308 0;
BA_ "VFrameFormat" BO_ 308 14;
BA_ "GenMsgCycleTime" BO_ 1633 100;
BA_ "GenMsgILSupport" BO_ 1633 1;
BA_ "GenMsgSendType" BO_ 1633 0;
BA_ "VFrameFormat" BO_ 1633 14;
BA_ "GenMsgCycleTime" BO_ 2527679661 200;
BA_ "GenMsgDelayTime" BO_ 2527679661 40;
BA_ "GenMsgILSupport" BO_ 2527679661 1;
BA_ "GenMsgSendType" BO_ 2527679661 0;
BA_ "VFrameFormat" BO_ 2527679661 15;
BA_ "GenMsgCycleTime" BO_ 219 1000;
BA_ "GenMsgCycleTimeFast" BO_ 219 20;
BA_ "GenMsgDelayTime" BO_ 219 20;
BA_ "GenMsgILSupport" BO_ 219 1;
BA_ "GenMsgNrOfRepetition" BO_ 219 5;
BA_ "GenMsgPDUConstants" BO_ 219 "0x09,0xfa,0xca,0x8e,0x62,0xd5,0xd1,0xf0,0x31,0xa0,0xaf,0xda,0x4d,0x1a,0x0a,0x97";
BA_ "GenMsgSendType" BO_ 219 0;
BA_ "VFrameFormat" BO_ 219 14;
BA_ "GenMsgCycleTimeFast" BO_ 2536711680 80;
BA_ "GenMsgSendType" BO_ 2536711680 7;
BA_ "MsgType" BO_ 2536711680 5;
BA_ "VFrameFormat" BO_ 2536711680 15;
BA_ "GenMsgCycleTime" BO_ 2536711696 1000;
BA_ "GenMsgCycleTimeFast" BO_ 2536711696 50;
BA_ "GenMsgSendType" BO_ 2536711696 7;
BA_ "MsgType" BO_ 2536711696 5;
BA_ "VFrameFormat" BO_ 2536711696 15;
BA_ "MsgType" BO_ 2536767264 5;
BA_ "VFrameFormat" BO_ 2536767264 15;
BA_ "MsgType" BO_ 2536767280 5;
BA_ "VFrameFormat" BO_ 2536767280 15;
BA_ "GenMsgCycleTimeFast" BO_ 2536703744 80;
BA_ "GenMsgSendType" BO_ 2536703744 7;
BA_ "MsgType" BO_ 2536703744 5;
BA_ "VFrameFormat" BO_ 2536703744 15;
BA_ "GenMsgCycleTimeFast" BO_ 2536703745 80;
BA_ "GenMsgSendType" BO_ 2536703745 7;
BA_ "MsgType" BO_ 2536703745 5;
BA_ "VFrameFormat" BO_ 2536703745 15;
BA_ "GenMsgCycleTime" BO_ 2536703760 1000;
BA_ "GenMsgCycleTimeFast" BO_ 2536703760 50;
BA_ "GenMsgSendType" BO_ 2536703760 7;
BA_ "MsgType" BO_ 2536703760 5;
BA_ "VFrameFormat" BO_ 2536703760 15;
BA_ "GenMsgCycleTime" BO_ 1626 1000;
BA_ "GenMsgCycleTimeFast" BO_ 1626 100;
BA_ "GenMsgDelayTime" BO_ 1626 30;
BA_ "GenMsgILSupport" BO_ 1626 1;
BA_ "GenMsgNrOfRepetition" BO_ 1626 5;
BA_ "GenMsgSendType" BO_ 1626 0;
BA_ "VFrameFormat" BO_ 1626 14;
BA_ "GenMsgCycleTime" BO_ 2527679939 200;
BA_ "GenMsgILSupport" BO_ 2527679939 1;
BA_ "GenMsgPDUConstants" BO_ 2527679939 "0x54,0xdc,0x41,0x83,0x59,0x46,0x5c,0xfb,0xd3,0x5e,0xea,0x58,0x1f,0xd5,0x6a,0xb3";
BA_ "GenMsgSendType" BO_ 2527679939 0;
BA_ "VFrameFormat" BO_ 2527679939 15;
BA_ "GenMsgCycleTime" BO_ 869 50;
BA_ "GenMsgILSupport" BO_ 869 1;
BA_ "GenMsgSendType" BO_ 869 0;
BA_ "VFrameFormat" BO_ 869 14;
BA_ "GenMsgCycleTime" BO_ 1163 100;
BA_ "GenMsgILSupport" BO_ 1163 1;
BA_ "GenMsgPDUConstants" BO_ 1163 "0x54,0xaf,0x8a,0xfb,0x0d,0x87,0x6a,0x0f,0x47,0x78,0x31,0x4f,0x35,0x28,0x82,0x6d";
BA_ "GenMsgSendType" BO_ 1163 0;
BA_ "VFrameFormat" BO_ 1163 14;
BA_ "GenSigSendType" SG_ 333 ACC_18_BZ 0;
BA_ "GenSigFuncType" SG_ 333 ACC_18_BZ 1;
BA_ "GenSigSwitchedByIgnition" SG_ 333 ACC_18_BZ 0;
BA_ "GenSigSendType" SG_ 333 ACC_18_CRC 0;
BA_ "GenSigFuncType" SG_ 333 ACC_18_CRC 2;
BA_ "GenSigSwitchedByIgnition" SG_ 333 ACC_18_CRC 0;
BA_ "GenSigSendType" SG_ 333 ACC_Abbiegewunsch 0;
BA_ "GenSigSwitchedByIgnition" SG_ 333 ACC_Abbiegewunsch 0;
BA_ "GenSigSendType" SG_ 333 ACC_Abbiegewunsch_Abstand 0;
BA_ "GenSigStartValue" SG_ 333 ACC_Abbiegewunsch_Abstand 511;
BA_ "GenSigSwitchedByIgnition" SG_ 333 ACC_Abbiegewunsch_Abstand 0;
BA_ "GenSigSendType" SG_ 333 ACC_Anfahren 0;
BA_ "GenSigSendType" SG_ 333 ACC_Anforderung_HMS 0;
BA_ "GenSigSendType" SG_ 333 ACC_Anhalten 0;
BA_ "GenSigSendType" SG_ 333 ACC_Anhalteweg 0;
BA_ "GenSigStartValue" SG_ 333 ACC_Anhalteweg 2046;
BA_ "Fehlerwert" SG_ 333 ACC_Anhalteweg 2047;
BA_ "GenSigSendType" SG_ 333 ACC_Blindheit_erkannt 0;
BA_ "GenSigSendType" SG_ 333 ACC_Boost 0;
BA_ "GenSigSendType" SG_ 333 ACC_DynErhoehung 0;
BA_ "GenSigSendType" SG_ 333 ACC_FoD_Status 0;
BA_ "GenSigSendType" SG_ 333 ACC_Folgebeschl 0;
BA_ "GenSigStartValue" SG_ 333 ACC_Folgebeschl 254;
BA_ "GenSigSendType" SG_ 333 ACC_Freilauf_Anf 0;
BA_ "GenSigSendType" SG_ 333 ACC_Freilauf_Info 0;
BA_ "GenSigSendType" SG_ 333 ACC_Freilaufstrategie_TSK 0;
BA_ "GenSigSendType" SG_ 333 ACC_limitierte_Anfahrdyn 0;
BA_ "GenSigSendType" SG_ 333 ACC_Minimale_Bremsung 0;
BA_ "GenSigSendType" SG_ 333 ACC_nachtr_Stopp_Anf 0;
BA_ "GenSigSwitchedByIgnition" SG_ 333 ACC_nachtr_Stopp_Anf 0;
BA_ "GenSigSendType" SG_ 333 ACC_neg_Sollbeschl_Grad_02 0;
BA_ "GenSigSendType" SG_ 333 ACC_pos_Sollbeschl_Grad_02 0;
BA_ "GenSigSendType" SG_ 333 ACC_relev_Nichtverfuegbarkeit 0;
BA_ "GenSigSendType" SG_ 333 ACC_relevanter_Fehler 0;
BA_ "GenSigSendType" SG_ 333 ACC_Sollbeschleunigung_02 0;
BA_ "GenSigStartValue" SG_ 333 ACC_Sollbeschleunigung_02 2046;
BA_ "Fehlerwert" SG_ 333 ACC_Sollbeschleunigung_02 2047;
BA_ "GenSigSendType" SG_ 333 ACC_StartStopp_Info 0;
BA_ "GenSigSendType" SG_ 333 ACC_Status_ACC 0;
BA_ "GenSigSendType" SG_ 333 ACC_TA_Kurve_Abstand 0;
BA_ "GenSigStartValue" SG_ 333 ACC_TA_Kurve_Abstand 62;
BA_ "GenSigSendType" SG_ 333 ACC_TA_Kurve_vDelta 0;
BA_ "GenSigStartValue" SG_ 333 ACC_TA_Kurve_vDelta 11;
BA_ "GenSigSendType" SG_ 333 ACC_Tempolimitassistent_Ein 0;
BA_ "GenSigSendType" SG_ 333 ACC_Typ 0;
BA_ "GenSigFuncType" SG_ 333 ACC_Typ 8;
BA_ "GenSigSendType" SG_ 333 ACC_Verkehrssinn 0;
BA_ "GenSigSendType" SG_ 333 ACC_zul_Regelabw_oben 0;
BA_ "GenSigSendType" SG_ 333 ACC_zul_Regelabw_unten 0;
BA_ "GenSigSendType" SG_ 333 MPPmod_1_Segment 0;
BA_ "GenSigSwitchedByIgnition" SG_ 333 MPPmod_1_Segment 0;
BA_ "GenSigSendType" SG_ 333 MPPmod_2_Segment 0;
BA_ "GenSigSwitchedByIgnition" SG_ 333 MPPmod_2_Segment 0;
BA_ "GenSigSendType" SG_ 333 MPPmod_3_Segment 0;
BA_ "GenSigSwitchedByIgnition" SG_ 333 MPPmod_3_Segment 0;
BA_ "GenSigSendType" SG_ 333 MPPmod_4_Segment 0;
BA_ "GenSigSwitchedByIgnition" SG_ 333 MPPmod_4_Segment 0;
BA_ "GenSigSendType" SG_ 333 RDR_v_ueber_Grund 0;
BA_ "GenSigStartValue" SG_ 333 RDR_v_ueber_Grund 4091;
BA_ "Fehlerwert" SG_ 333 RDR_v_ueber_Grund 4093;
BA_ "GenSigSendType" SG_ 333 RDR_v_ueber_Grund_Fahrtrichtung 0;
BA_ "GenSigStartValue" SG_ 333 RDR_v_ueber_Grund_Fahrtrichtung 2;
BA_ "GenSigSendType" SG_ 333 RDR_v_ueber_Grund_Genauigkeit 0;
BA_ "GenSigStartValue" SG_ 333 RDR_v_ueber_Grund_Genauigkeit 62;
BA_ "Fehlerwert" SG_ 333 RDR_v_ueber_Grund_Genauigkeit 63;
BA_ "GenSigSendType" SG_ 333 RDR_VBEG_Anforderung 0;
BA_ "GenSigSwitchedByIgnition" SG_ 333 RDR_VBEG_Anforderung 0;
BA_ "GenSigSendType" SG_ 333 vESC_Verz_Anf 0;
BA_ "GenSigStartValue" SG_ 333 vESC_Verz_Anf 9;
BA_ "Fehlerwert" SG_ 333 vESC_Verz_Anf 10;
BA_ "GenSigSendType" SG_ 2527679682 ACC_ASM_Data_1 0;
BA_ "GenSigSendType" SG_ 2527679682 ACC_ASM_Data_2 0;
BA_ "GenSigSendType" SG_ 2527679682 ACC_ASM_Data_3 0;
BA_ "GenSigSendType" SG_ 2527679682 ACC_ASM_Data_4 0;
BA_ "GenSigSendType" SG_ 2527679682 ACC_ASM_Data_5 0;
BA_ "GenSigSendType" SG_ 2527679682 ACC_ASM_Data_6 0;
BA_ "GenSigSendType" SG_ 2527679682 ACC_ASM_Ereignis 3;
BA_ "GenSigSendType" SG_ 2527679682 ACC_ASM_Zeitstempel_02 3;
BA_ "GenSigStartValue" SG_ 2527679682 ACC_ASM_Zeitstempel_02 255;
BA_ "GenSigSendType" SG_ 64 AB_Anzeige_Fussg 0;
BA_ "GenSigSwitchedByIgnition" SG_ 64 AB_Anzeige_Fussg 0;
BA_ "GenSigSendType" SG_ 64 AB_Belegung_VF 0;
BA_ "GenSigSwitchedByIgnition" SG_ 64 AB_Belegung_VF 0;
BA_ "Fehlerwert" SG_ 64 AB_Belegung_VF 1;
BA_ "GenSigSendType" SG_ 64 AB_Crash_Int 4;
BA_ "GenSigSwitchedByIgnition" SG_ 64 AB_Crash_Int 0;
BA_ "GenSigSendType" SG_ 64 AB_Deaktiviert 0;
BA_ "GenSigSwitchedByIgnition" SG_ 64 AB_Deaktiviert 0;
BA_ "GenSigSendType" SG_ 64 AB_Deaktivierung_HV 4;
BA_ "GenSigSwitchedByIgnition" SG_ 64 AB_Deaktivierung_HV 0;
BA_ "Fehlerwert" SG_ 64 AB_Deaktivierung_HV 7;
BA_ "GenSigSendType" SG_ 64 AB_Diagnose 0;
BA_ "GenSigSwitchedByIgnition" SG_ 64 AB_Diagnose 0;
BA_ "GenSigSendType" SG_ 64 AB_eCS_Error 0;
BA_ "GenSigSwitchedByIgnition" SG_ 64 AB_eCS_Error 0;
BA_ "GenSigSendType" SG_ 64 AB_EDR_Trigger 3;
BA_ "GenSigSwitchedByIgnition" SG_ 64 AB_EDR_Trigger 0;
BA_ "GenSigSendType" SG_ 64 AB_Erh_Auf_VB 0;
BA_ "GenSigSwitchedByIgnition" SG_ 64 AB_Erh_Auf_VB 0;
BA_ "GenSigSendType" SG_ 64 AB_Front_Crash 4;
BA_ "GenSigSwitchedByIgnition" SG_ 64 AB_Front_Crash 0;
BA_ "GenSigSendType" SG_ 64 AB_Gurtschloss_FA_ext 3;
BA_ "GenSigStartValue" SG_ 64 AB_Gurtschloss_FA_ext 6;
BA_ "GenSigSwitchedByIgnition" SG_ 64 AB_Gurtschloss_FA_ext 0;
BA_ "Fehlerwert" SG_ 64 AB_Gurtschloss_FA_ext 7;
BA_ "GenSigSendType" SG_ 64 AB_Gurtschloss_FA_ext_aktiv 0;
BA_ "GenSigSwitchedByIgnition" SG_ 64 AB_Gurtschloss_FA_ext_aktiv 0;
BA_ "GenSigSendType" SG_ 64 AB_Gurtwarn_VB 0;
BA_ "GenSigSwitchedByIgnition" SG_ 64 AB_Gurtwarn_VB 0;
BA_ "GenSigSendType" SG_ 64 AB_Gurtwarn_VF 0;
BA_ "GenSigSwitchedByIgnition" SG_ 64 AB_Gurtwarn_VF 0;
BA_ "GenSigSendType" SG_ 64 AB_Heck_Crash 4;
BA_ "GenSigSwitchedByIgnition" SG_ 64 AB_Heck_Crash 0;
BA_ "GenSigSendType" SG_ 64 AB_Lampe 0;
BA_ "GenSigStartValue" SG_ 64 AB_Lampe 1;
BA_ "GenSigSwitchedByIgnition" SG_ 64 AB_Lampe 0;
BA_ "GenSigSendType" SG_ 64 AB_MKB_Anforderung 4;
BA_ "GenSigSwitchedByIgnition" SG_ 64 AB_MKB_Anforderung 0;
BA_ "GenSigSendType" SG_ 64 AB_MKB_gueltig 0;
BA_ "GenSigSwitchedByIgnition" SG_ 64 AB_MKB_gueltig 0;
BA_ "GenSigSendType" SG_ 64 AB_PAO_Leuchte_Anf 0;
BA_ "GenSigStartValue" SG_ 64 AB_PAO_Leuchte_Anf 1;
BA_ "GenSigSwitchedByIgnition" SG_ 64 AB_PAO_Leuchte_Anf 0;
BA_ "GenSigSendType" SG_ 64 AB_RGS_Anst 3;
BA_ "GenSigStartValue" SG_ 64 AB_RGS_Anst 8;
BA_ "GenSigSwitchedByIgnition" SG_ 64 AB_RGS_Anst 0;
BA_ "GenSigSendType" SG_ 64 AB_Rollover_Crash 4;
BA_ "GenSigSwitchedByIgnition" SG_ 64 AB_Rollover_Crash 0;
BA_ "GenSigSendType" SG_ 64 AB_SB_Crash 4;
BA_ "GenSigSwitchedByIgnition" SG_ 64 AB_SB_Crash 0;
BA_ "GenSigSendType" SG_ 64 AB_SF_Crash 4;
BA_ "GenSigSwitchedByIgnition" SG_ 64 AB_SF_Crash 0;
BA_ "GenSigSendType" SG_ 64 AB_Stellgliedtest 0;
BA_ "GenSigSwitchedByIgnition" SG_ 64 AB_Stellgliedtest 0;
BA_ "GenSigSendType" SG_ 64 AB_Systemfehler 0;
BA_ "GenSigSwitchedByIgnition" SG_ 64 AB_Systemfehler 0;
BA_ "GenSigSendType" SG_ 64 AB_Texte_AKS 0;
BA_ "GenSigSwitchedByIgnition" SG_ 64 AB_Texte_AKS 0;
BA_ "GenSigSendType" SG_ 64 AB_VB_deaktiviert 0;
BA_ "GenSigStartValue" SG_ 64 AB_VB_deaktiviert 1;
BA_ "GenSigSwitchedByIgnition" SG_ 64 AB_VB_deaktiviert 0;
BA_ "GenSigSendType" SG_ 64 AB_Versorgungsspannung 0;
BA_ "GenSigSwitchedByIgnition" SG_ 64 AB_Versorgungsspannung 0;
BA_ "GenSigSendType" SG_ 64 Airbag_01_BZ 0;
BA_ "GenSigFuncType" SG_ 64 Airbag_01_BZ 1;
BA_ "GenSigSwitchedByIgnition" SG_ 64 Airbag_01_BZ 0;
BA_ "GenSigSendType" SG_ 64 Airbag_01_CRC 0;
BA_ "GenSigFuncType" SG_ 64 Airbag_01_CRC 2;
BA_ "GenSigSwitchedByIgnition" SG_ 64 Airbag_01_CRC 0;
BA_ "GenSigSendType" SG_ 64 ASM_Masterzeit_02 0;
BA_ "GenSigStartValue" SG_ 64 ASM_Masterzeit_02 255;
BA_ "GenSigSwitchedByIgnition" SG_ 64 ASM_Masterzeit_02 0;
BA_ "GenSigSendType" SG_ 2589283872 Airbag_01_CALID_Index_01 0;
BA_ "GenSigStartValue" SG_ 2589283872 Airbag_01_CALID_Index_01 63;
BA_ "GenSigSwitchedByIgnition" SG_ 2589283872 Airbag_01_CALID_Index_01 0;
BA_ "GenSigSendType" SG_ 2589283872 Airbag_01_CALID_Index_02 0;
BA_ "GenSigStartValue" SG_ 2589283872 Airbag_01_CALID_Index_02 63;
BA_ "GenSigSwitchedByIgnition" SG_ 2589283872 Airbag_01_CALID_Index_02 0;
BA_ "GenSigSendType" SG_ 2589283872 Airbag_01_CALID_Index_03 0;
BA_ "GenSigStartValue" SG_ 2589283872 Airbag_01_CALID_Index_03 63;
BA_ "GenSigSwitchedByIgnition" SG_ 2589283872 Airbag_01_CALID_Index_03 0;
BA_ "GenSigSendType" SG_ 2589283872 Airbag_01_CALID_Index_04 0;
BA_ "GenSigStartValue" SG_ 2589283872 Airbag_01_CALID_Index_04 63;
BA_ "GenSigSwitchedByIgnition" SG_ 2589283872 Airbag_01_CALID_Index_04 0;
BA_ "GenSigSendType" SG_ 2589283872 Airbag_01_CALID_Index_05 0;
BA_ "GenSigStartValue" SG_ 2589283872 Airbag_01_CALID_Index_05 63;
BA_ "GenSigSwitchedByIgnition" SG_ 2589283872 Airbag_01_CALID_Index_05 0;
BA_ "GenSigSendType" SG_ 2589283872 Airbag_01_CALID_Index_06 0;
BA_ "GenSigStartValue" SG_ 2589283872 Airbag_01_CALID_Index_06 63;
BA_ "GenSigSwitchedByIgnition" SG_ 2589283872 Airbag_01_CALID_Index_06 0;
BA_ "GenSigSendType" SG_ 2589283872 Airbag_01_CALID_Index_07 0;
BA_ "GenSigStartValue" SG_ 2589283872 Airbag_01_CALID_Index_07 63;
BA_ "GenSigSwitchedByIgnition" SG_ 2589283872 Airbag_01_CALID_Index_07 0;
BA_ "GenSigSendType" SG_ 2589283872 Airbag_01_CALID_Index_08 0;
BA_ "GenSigStartValue" SG_ 2589283872 Airbag_01_CALID_Index_08 63;
BA_ "GenSigSwitchedByIgnition" SG_ 2589283872 Airbag_01_CALID_Index_08 0;
BA_ "GenSigSendType" SG_ 2589283872 Airbag_01_CALID_Index_09 0;
BA_ "GenSigStartValue" SG_ 2589283872 Airbag_01_CALID_Index_09 63;
BA_ "GenSigSwitchedByIgnition" SG_ 2589283872 Airbag_01_CALID_Index_09 0;
BA_ "GenSigSendType" SG_ 2589283872 Airbag_01_CALID_Index_10 0;
BA_ "GenSigStartValue" SG_ 2589283872 Airbag_01_CALID_Index_10 63;
BA_ "GenSigSwitchedByIgnition" SG_ 2589283872 Airbag_01_CALID_Index_10 0;
BA_ "GenSigSendType" SG_ 2589283872 Airbag_01_CALID_Index_11 0;
BA_ "GenSigStartValue" SG_ 2589283872 Airbag_01_CALID_Index_11 63;
BA_ "GenSigSwitchedByIgnition" SG_ 2589283872 Airbag_01_CALID_Index_11 0;
BA_ "GenSigSendType" SG_ 2589283872 Airbag_01_CALID_Index_12 0;
BA_ "GenSigStartValue" SG_ 2589283872 Airbag_01_CALID_Index_12 63;
BA_ "GenSigSwitchedByIgnition" SG_ 2589283872 Airbag_01_CALID_Index_12 0;
BA_ "GenSigSendType" SG_ 2589283872 Airbag_01_CALID_Index_13 0;
BA_ "GenSigStartValue" SG_ 2589283872 Airbag_01_CALID_Index_13 63;
BA_ "GenSigSwitchedByIgnition" SG_ 2589283872 Airbag_01_CALID_Index_13 0;
BA_ "GenSigSendType" SG_ 2589283872 Airbag_01_CALID_Index_14 0;
BA_ "GenSigStartValue" SG_ 2589283872 Airbag_01_CALID_Index_14 63;
BA_ "GenSigSwitchedByIgnition" SG_ 2589283872 Airbag_01_CALID_Index_14 0;
BA_ "GenSigSendType" SG_ 2589283872 Airbag_01_CALID_Index_15 0;
BA_ "GenSigStartValue" SG_ 2589283872 Airbag_01_CALID_Index_15 63;
BA_ "GenSigSwitchedByIgnition" SG_ 2589283872 Airbag_01_CALID_Index_15 0;
BA_ "GenSigSendType" SG_ 2589283872 Airbag_01_CALID_Index_16 0;
BA_ "GenSigStartValue" SG_ 2589283872 Airbag_01_CALID_Index_16 63;
BA_ "GenSigSwitchedByIgnition" SG_ 2589283872 Airbag_01_CALID_Index_16 0;
BA_ "GenSigSendType" SG_ 2589283873 Airbag_01_CVN_Byte_1 0;
BA_ "GenSigSwitchedByIgnition" SG_ 2589283873 Airbag_01_CVN_Byte_1 0;
BA_ "GenSigSendType" SG_ 2589283873 Airbag_01_CVN_Byte_2 0;
BA_ "GenSigSwitchedByIgnition" SG_ 2589283873 Airbag_01_CVN_Byte_2 0;
BA_ "GenSigSendType" SG_ 2589283873 Airbag_01_CVN_Byte_3 0;
BA_ "GenSigSwitchedByIgnition" SG_ 2589283873 Airbag_01_CVN_Byte_3 0;
BA_ "GenSigSendType" SG_ 2589283873 Airbag_01_CVN_Byte_4 0;
BA_ "GenSigSwitchedByIgnition" SG_ 2589283873 Airbag_01_CVN_Byte_4 0;
BA_ "GenSigSendType" SG_ 2589283873 Airbag_01_CVN_VLD 0;
BA_ "GenSigSwitchedByIgnition" SG_ 2589283873 Airbag_01_CVN_VLD 0;
BA_ "GenSigSendType" SG_ 1312 AB_Abschaltanf_SIH_BF 3;
BA_ "GenSigSendType" SG_ 1312 AB_Anforderung_eCall 0;
BA_ "GenSigSwitchedByIgnition" SG_ 1312 AB_Anforderung_eCall 0;
BA_ "GenSigSendType" SG_ 1312 AB_Anforderung_USM 0;
BA_ "GenSigSwitchedByIgnition" SG_ 1312 AB_Anforderung_USM 0;
BA_ "GenSigSendType" SG_ 1312 AB_Anprall_FGS 3;
BA_ "GenSigSendType" SG_ 1312 AB_Anprall_Front_Beifahrer 3;
BA_ "GenSigSendType" SG_ 1312 AB_Anprall_Front_Fahrer 3;
BA_ "GenSigSendType" SG_ 1312 AB_Anprall_Heck_Beifahrer 3;
BA_ "GenSigSendType" SG_ 1312 AB_Anprall_Heck_Fahrer 3;
BA_ "GenSigSendType" SG_ 1312 AB_Anprall_Rollover 3;
BA_ "GenSigSendType" SG_ 1312 AB_Anprall_Seite_Beifahrer 3;
BA_ "GenSigSendType" SG_ 1312 AB_Anprall_Seite_Fahrer 3;
BA_ "GenSigSendType" SG_ 1312 AB_Belegung_VB 0;
BA_ "GenSigSwitchedByIgnition" SG_ 1312 AB_Belegung_VB 0;
BA_ "Fehlerwert" SG_ 1312 AB_Belegung_VB 1;
BA_ "GenSigSendType" SG_ 1312 AB_Crashschwere 3;
BA_ "GenSigSwitchedByIgnition" SG_ 1312 AB_Crashschwere 0;
BA_ "Fehlerwert" SG_ 1312 AB_Crashschwere 7;
BA_ "GenSigSendType" SG_ 1312 AB_Gurtschloss_BF 3;
BA_ "GenSigStartValue" SG_ 1312 AB_Gurtschloss_BF 1;
BA_ "GenSigSwitchedByIgnition" SG_ 1312 AB_Gurtschloss_BF 0;
BA_ "GenSigSendType" SG_ 1312 AB_Gurtschloss_FA 3;
BA_ "GenSigStartValue" SG_ 1312 AB_Gurtschloss_FA 1;
BA_ "GenSigSwitchedByIgnition" SG_ 1312 AB_Gurtschloss_FA 0;
BA_ "GenSigSendType" SG_ 1312 AB_Gurtschloss_Reihe2_BF 3;
BA_ "GenSigStartValue" SG_ 1312 AB_Gurtschloss_Reihe2_BF 1;
BA_ "GenSigSwitchedByIgnition" SG_ 1312 AB_Gurtschloss_Reihe2_BF 0;
BA_ "GenSigSendType" SG_ 1312 AB_Gurtschloss_Reihe2_FA 3;
BA_ "GenSigStartValue" SG_ 1312 AB_Gurtschloss_Reihe2_FA 1;
BA_ "GenSigSwitchedByIgnition" SG_ 1312 AB_Gurtschloss_Reihe2_FA 0;
BA_ "GenSigSendType" SG_ 1312 AB_Gurtschloss_Reihe2_MI 3;
BA_ "GenSigStartValue" SG_ 1312 AB_Gurtschloss_Reihe2_MI 1;
BA_ "GenSigSwitchedByIgnition" SG_ 1312 AB_Gurtschloss_Reihe2_MI 0;
BA_ "GenSigSendType" SG_ 1312 AB_Gurtschloss_Reihe3_BF 3;
BA_ "GenSigStartValue" SG_ 1312 AB_Gurtschloss_Reihe3_BF 1;
BA_ "GenSigSwitchedByIgnition" SG_ 1312 AB_Gurtschloss_Reihe3_BF 0;
BA_ "GenSigSendType" SG_ 1312 AB_Gurtschloss_Reihe3_FA 3;
BA_ "GenSigStartValue" SG_ 1312 AB_Gurtschloss_Reihe3_FA 1;
BA_ "GenSigSwitchedByIgnition" SG_ 1312 AB_Gurtschloss_Reihe3_FA 0;
BA_ "GenSigSendType" SG_ 1312 AB_Gurtschloss_Reihe3_MI 3;
BA_ "GenSigStartValue" SG_ 1312 AB_Gurtschloss_Reihe3_MI 1;
BA_ "GenSigSwitchedByIgnition" SG_ 1312 AB_Gurtschloss_Reihe3_MI 0;
BA_ "GenSigSendType" SG_ 1312 AB_Sitzpos_Sens_BF 0;
BA_ "GenSigSwitchedByIgnition" SG_ 1312 AB_Sitzpos_Sens_BF 0;
BA_ "Fehlerwert" SG_ 1312 AB_Sitzpos_Sens_BF 1;
BA_ "GenSigSendType" SG_ 1312 AB_Sitzpos_Sens_FA 0;
BA_ "GenSigSwitchedByIgnition" SG_ 1312 AB_Sitzpos_Sens_FA 0;
BA_ "Fehlerwert" SG_ 1312 AB_Sitzpos_Sens_FA 1;
BA_ "GenSigSendType" SG_ 1312 AB_Wickelklappung_Reihe2_BF 3;
BA_ "GenSigStartValue" SG_ 1312 AB_Wickelklappung_Reihe2_BF 1;
BA_ "GenSigSwitchedByIgnition" SG_ 1312 AB_Wickelklappung_Reihe2_BF 0;
BA_ "GenSigSendType" SG_ 1312 AB_Wickelklappung_Reihe2_FA 3;
BA_ "GenSigStartValue" SG_ 1312 AB_Wickelklappung_Reihe2_FA 1;
BA_ "GenSigSwitchedByIgnition" SG_ 1312 AB_Wickelklappung_Reihe2_FA 0;
BA_ "GenSigSendType" SG_ 1312 AB_Wickelklappung_Reihe2_MI 3;
BA_ "GenSigStartValue" SG_ 1312 AB_Wickelklappung_Reihe2_MI 1;
BA_ "GenSigSwitchedByIgnition" SG_ 1312 AB_Wickelklappung_Reihe2_MI 0;
BA_ "GenSigSendType" SG_ 1312 Airbag_02_BZ 0;
BA_ "GenSigFuncType" SG_ 1312 Airbag_02_BZ 1;
BA_ "GenSigSwitchedByIgnition" SG_ 1312 Airbag_02_BZ 0;
BA_ "GenSigSendType" SG_ 1312 Airbag_02_CRC 0;
BA_ "GenSigFuncType" SG_ 1312 Airbag_02_CRC 2;
BA_ "GenSigSwitchedByIgnition" SG_ 1312 Airbag_02_CRC 0;
BA_ "GenSigSendType" SG_ 1312 LoGeWa_Event_Kombiwarnung 3;
BA_ "GenSigSwitchedByIgnition" SG_ 1312 LoGeWa_Event_Kombiwarnung 0;
BA_ "GenSigSendType" SG_ 1312 SC_PAO_OFF_Anf 3;
BA_ "GenSigSwitchedByIgnition" SG_ 1312 SC_PAO_OFF_Anf 0;
BA_ "GenSigSendType" SG_ 1312 SC_PAO_ON_Anf 3;
BA_ "GenSigSwitchedByIgnition" SG_ 1312 SC_PAO_ON_Anf 0;
BA_ "GenSigSendType" SG_ 1312 SC_PAO_Schriftzug_Anf 3;
BA_ "GenSigSwitchedByIgnition" SG_ 1312 SC_PAO_Schriftzug_Anf 0;
BA_ "GenSigSendType" SG_ 65 AB_DeltaV_X_eCall 0;
BA_ "GenSigSwitchedByIgnition" SG_ 65 AB_DeltaV_X_eCall 0;
BA_ "GenSigSendType" SG_ 65 AB_DeltaV_Y_eCall 0;
BA_ "GenSigSwitchedByIgnition" SG_ 65 AB_DeltaV_Y_eCall 0;
BA_ "GenSigSendType" SG_ 65 AB_MKB_Safing 4;
BA_ "GenSigSwitchedByIgnition" SG_ 65 AB_MKB_Safing 0;
BA_ "GenSigSendType" SG_ 65 Airbag_03_BZ 0;
BA_ "GenSigFuncType" SG_ 65 Airbag_03_BZ 1;
BA_ "GenSigSwitchedByIgnition" SG_ 65 Airbag_03_BZ 0;
BA_ "GenSigSendType" SG_ 65 Airbag_03_CRC 0;
BA_ "GenSigFuncType" SG_ 65 Airbag_03_CRC 2;
BA_ "GenSigSwitchedByIgnition" SG_ 65 Airbag_03_CRC 0;
BA_ "GenSigSendType" SG_ 1349 AB_Anprall_Front 3;
BA_ "GenSigSwitchedByIgnition" SG_ 1349 AB_Anprall_Front 0;
BA_ "GenSigSendType" SG_ 1349 AB_Anprall_Heck 3;
BA_ "GenSigSwitchedByIgnition" SG_ 1349 AB_Anprall_Heck 0;
BA_ "GenSigSendType" SG_ 1349 AB_Belegung_VF_ext 3;
BA_ "GenSigStartValue" SG_ 1349 AB_Belegung_VF_ext 6;
BA_ "GenSigSwitchedByIgnition" SG_ 1349 AB_Belegung_VF_ext 0;
BA_ "Fehlerwert" SG_ 1349 AB_Belegung_VF_ext 7;
BA_ "GenSigSendType" SG_ 1349 AB_Belegung_VF_ext_aktiv 3;
BA_ "GenSigSwitchedByIgnition" SG_ 1349 AB_Belegung_VF_ext_aktiv 0;
BA_ "GenSigSendType" SG_ 1349 AB_Gurtwarn_Reihe2_BF 0;
BA_ "GenSigSwitchedByIgnition" SG_ 1349 AB_Gurtwarn_Reihe2_BF 0;
BA_ "GenSigSendType" SG_ 1349 AB_Gurtwarn_Reihe2_FA 0;
BA_ "GenSigSwitchedByIgnition" SG_ 1349 AB_Gurtwarn_Reihe2_FA 0;
BA_ "GenSigSendType" SG_ 1349 AB_Gurtwarn_Reihe2_MI 0;
BA_ "GenSigSwitchedByIgnition" SG_ 1349 AB_Gurtwarn_Reihe2_MI 0;
BA_ "GenSigSendType" SG_ 1349 AB_Gurtwarn_Reihe3_BF 0;
BA_ "GenSigSwitchedByIgnition" SG_ 1349 AB_Gurtwarn_Reihe3_BF 0;
BA_ "GenSigSendType" SG_ 1349 AB_Gurtwarn_Reihe3_FA 0;
BA_ "GenSigSwitchedByIgnition" SG_ 1349 AB_Gurtwarn_Reihe3_FA 0;
BA_ "GenSigSendType" SG_ 1349 AB_Gurtwarn_Reihe3_MI 0;
BA_ "GenSigSwitchedByIgnition" SG_ 1349 AB_Gurtwarn_Reihe3_MI 0;
BA_ "GenSigSendType" SG_ 1349 AB_Gurtwarn_Reihe4_BF 0;
BA_ "GenSigSwitchedByIgnition" SG_ 1349 AB_Gurtwarn_Reihe4_BF 0;
BA_ "GenSigSendType" SG_ 1349 AB_Gurtwarn_Reihe4_FA 0;
BA_ "GenSigSwitchedByIgnition" SG_ 1349 AB_Gurtwarn_Reihe4_FA 0;
BA_ "GenSigSendType" SG_ 1349 AB_Gurtwarn_Reihe4_MI 0;
BA_ "GenSigSwitchedByIgnition" SG_ 1349 AB_Gurtwarn_Reihe4_MI 0;
BA_ "GenSigSendType" SG_ 1349 AB_SBR_hinten_verbau 0;
BA_ "GenSigStartValue" SG_ 1349 AB_SBR_hinten_verbau 3;
BA_ "GenSigSwitchedByIgnition" SG_ 1349 AB_SBR_hinten_verbau 0;
BA_ "GenSigSendType" SG_ 1349 AbstWarn_MV_FAS_Fkt_Status 3;
BA_ "GenSigSwitchedByIgnition" SG_ 1349 AbstWarn_MV_FAS_Fkt_Status 0;
BA_ "Fehlerwert" SG_ 1349 AbstWarn_MV_FAS_Fkt_Status 3;
BA_ "GenSigSendType" SG_ 1349 Airbag_04_BZ 0;
BA_ "GenSigFuncType" SG_ 1349 Airbag_04_BZ 1;
BA_ "GenSigSwitchedByIgnition" SG_ 1349 Airbag_04_BZ 0;
BA_ "GenSigSendType" SG_ 1349 Airbag_04_CRC 0;
BA_ "GenSigFuncType" SG_ 1349 Airbag_04_CRC 2;
BA_ "GenSigSwitchedByIgnition" SG_ 1349 Airbag_04_CRC 0;
BA_ "GenSigSendType" SG_ 1349 AWV_Einstellung_System_ASG 3;
BA_ "GenSigSwitchedByIgnition" SG_ 1349 AWV_Einstellung_System_ASG 0;
BA_ "GenSigSendType" SG_ 1349 AWV_Einstellung_Warnung_ASG 3;
BA_ "GenSigSwitchedByIgnition" SG_ 1349 AWV_Einstellung_Warnung_ASG 0;
BA_ "GenSigSendType" SG_ 1349 LGI_FAS_Fkt_Status 3;
BA_ "GenSigSwitchedByIgnition" SG_ 1349 LGI_FAS_Fkt_Status 0;
BA_ "Fehlerwert" SG_ 1349 LGI_FAS_Fkt_Status 3;
BA_ "GenSigSendType" SG_ 1349 PreCrash_FAS_Fkt_Status 3;
BA_ "GenSigSwitchedByIgnition" SG_ 1349 PreCrash_FAS_Fkt_Status 0;
BA_ "Fehlerwert" SG_ 1349 PreCrash_FAS_Fkt_Status 3;
BA_ "GenSigSendType" SG_ 1349 SC_PreSense_Modus_System_KAS 3;
BA_ "GenSigSwitchedByIgnition" SG_ 1349 SC_PreSense_Modus_System_KAS 0;
BA_ "GenSigSendType" SG_ 1349 SC_PreSense_Modus_System_MV 3;
BA_ "GenSigSwitchedByIgnition" SG_ 1349 SC_PreSense_Modus_System_MV 0;
BA_ "GenSigSendType" SG_ 1349 SC_PreSense_Modus_System_NV 3;
BA_ "GenSigSwitchedByIgnition" SG_ 1349 SC_PreSense_Modus_System_NV 0;
BA_ "GenSigSendType" SG_ 1349 SC_PreSense_Modus_Warnung_MV 3;
BA_ "GenSigSwitchedByIgnition" SG_ 1349 SC_PreSense_Modus_Warnung_MV 0;
BA_ "GenSigSendType" SG_ 1349 SC_PreSense_Modus_Warnung_NV 3;
BA_ "GenSigSwitchedByIgnition" SG_ 1349 SC_PreSense_Modus_Warnung_NV 0;
BA_ "GenSigSendType" SG_ 1349 WarnBrems_Charisma_FahrPr 0;
BA_ "GenSigSendType" SG_ 1349 WarnBrems_Charisma_Status 0;
BA_ "GenSigSendType" SG_ 2527679722 AB_Anzeige_Kombi_SRAB 0;
BA_ "GenSigSendType" SG_ 2527679722 AB_Anzeige_Komfort_HBFS 0;
BA_ "GenSigSendType" SG_ 2527679722 AB_Anzeige_Komfort_HFS 0;
BA_ "GenSigSendType" SG_ 2527679722 AB_Anzeige_Sitz_Komfort_HBFS 0;
BA_ "GenSigSendType" SG_ 2527679722 AB_Anzeige_Sitz_Komfort_HFS 0;
BA_ "GenSigSendType" SG_ 2527679722 AB_Gurtschloss_MI 0;
BA_ "GenSigStartValue" SG_ 2527679722 AB_Gurtschloss_MI 1;
BA_ "GenSigSwitchedByIgnition" SG_ 2527679722 AB_Gurtschloss_MI 0;
BA_ "GenSigSendType" SG_ 2527679722 AB_Gurtschloss_Reihe4_BF 0;
BA_ "GenSigStartValue" SG_ 2527679722 AB_Gurtschloss_Reihe4_BF 1;
BA_ "GenSigSwitchedByIgnition" SG_ 2527679722 AB_Gurtschloss_Reihe4_BF 0;
BA_ "GenSigSendType" SG_ 2527679722 AB_Gurtschloss_Reihe4_FA 0;
BA_ "GenSigStartValue" SG_ 2527679722 AB_Gurtschloss_Reihe4_FA 1;
BA_ "GenSigSwitchedByIgnition" SG_ 2527679722 AB_Gurtschloss_Reihe4_FA 0;
BA_ "GenSigSendType" SG_ 2527679722 AB_Gurtschloss_Reihe4_MI 0;
BA_ "GenSigStartValue" SG_ 2527679722 AB_Gurtschloss_Reihe4_MI 1;
BA_ "GenSigSwitchedByIgnition" SG_ 2527679722 AB_Gurtschloss_Reihe4_MI 0;
BA_ "GenSigSendType" SG_ 2527679722 AB_Gurtwarn_VM 0;
BA_ "GenSigSwitchedByIgnition" SG_ 2527679722 AB_Gurtwarn_VM 0;
BA_ "GenSigSendType" SG_ 2527679722 AB_Status_Sitz_SRAB_HBFS 0;
BA_ "GenSigStartValue" SG_ 2527679722 AB_Status_Sitz_SRAB_HBFS 2;
BA_ "GenSigSwitchedByIgnition" SG_ 2527679722 AB_Status_Sitz_SRAB_HBFS 0;
BA_ "Fehlerwert" SG_ 2527679722 AB_Status_Sitz_SRAB_HBFS 3;
BA_ "GenSigSendType" SG_ 2527679722 AB_Status_Sitz_SRAB_HFS 0;
BA_ "GenSigStartValue" SG_ 2527679722 AB_Status_Sitz_SRAB_HFS 2;
BA_ "Fehlerwert" SG_ 2527679722 AB_Status_Sitz_SRAB_HFS 3;
BA_ "GenSigSendType" SG_ 2527679722 AB_wSBR_Batteriestatus 0;
BA_ "GenSigSwitchedByIgnition" SG_ 2527679722 AB_wSBR_Batteriestatus 0;
BA_ "GenSigSendType" SG_ 2527679722 Airbag_06_BZ 0;
BA_ "GenSigFuncType" SG_ 2527679722 Airbag_06_BZ 1;
BA_ "GenSigSwitchedByIgnition" SG_ 2527679722 Airbag_06_BZ 0;
BA_ "GenSigSendType" SG_ 2527679722 Airbag_06_CRC 0;
BA_ "GenSigFuncType" SG_ 2527679722 Airbag_06_CRC 2;
BA_ "GenSigSwitchedByIgnition" SG_ 2527679722 Airbag_06_CRC 0;
BA_ "GenSigSendType" SG_ 63 AB_Anforderung_USM_Auth 0;
BA_ "GenSigSwitchedByIgnition" SG_ 63 AB_Anforderung_USM_Auth 0;
BA_ "GenSigSendType" SG_ 63 AB_Crash_Int_Auth 4;
BA_ "GenSigSwitchedByIgnition" SG_ 63 AB_Crash_Int_Auth 0;
BA_ "GenSigSendType" SG_ 63 AB_Front_Crash_Auth 4;
BA_ "GenSigSendType" SG_ 63 AB_Heck_Crash_Auth 4;
BA_ "GenSigSendType" SG_ 63 AB_MKB_Anforderung_Auth 4;
BA_ "GenSigSendType" SG_ 63 AB_MKB_gueltig_Auth 0;
BA_ "GenSigSendType" SG_ 63 AB_PAO_off_ANF_Auth 3;
BA_ "GenSigSwitchedByIgnition" SG_ 63 AB_PAO_off_ANF_Auth 0;
BA_ "GenSigSendType" SG_ 63 AB_PAO_on_ANF_Auth 3;
BA_ "GenSigSwitchedByIgnition" SG_ 63 AB_PAO_on_ANF_Auth 0;
BA_ "GenSigSendType" SG_ 63 AB_Rollover_Crash_Auth 4;
BA_ "GenSigSendType" SG_ 63 AB_SB_Crash_Auth 4;
BA_ "GenSigSendType" SG_ 63 AB_SF_Crash_Auth 4;
BA_ "GenSigSendType" SG_ 63 AB_VRU_Crash 4;
BA_ "GenSigSwitchedByIgnition" SG_ 63 AB_VRU_Crash 0;
BA_ "GenSigSendType" SG_ 63 Airbag_07_BZ 0;
BA_ "GenSigFuncType" SG_ 63 Airbag_07_BZ 1;
BA_ "GenSigSwitchedByIgnition" SG_ 63 Airbag_07_BZ 0;
BA_ "GenSigSendType" SG_ 63 Airbag_07_CRC 0;
BA_ "GenSigFuncType" SG_ 63 Airbag_07_CRC 2;
BA_ "GenSigSwitchedByIgnition" SG_ 63 Airbag_07_CRC 0;
BA_ "GenSigSendType" SG_ 63 SOK_Airbag_07_Signatur 0;
BA_ "GenSigFuncType" SG_ 63 SOK_Airbag_07_Signatur 15;
BA_ "GenSigSwitchedByIgnition" SG_ 63 SOK_Airbag_07_Signatur 0;
BA_ "GenSigSendType" SG_ 280 Allrad_03_BZ 0;
BA_ "GenSigFuncType" SG_ 280 Allrad_03_BZ 1;
BA_ "GenSigSendType" SG_ 280 ALR_Charisma_FahrPr 0;
BA_ "GenSigSwitchedByIgnition" SG_ 280 ALR_Charisma_FahrPr 0;
BA_ "GenSigSendType" SG_ 280 ALR_Charisma_Status 0;
BA_ "GenSigSwitchedByIgnition" SG_ 280 ALR_Charisma_Status 0;
BA_ "GenSigSendType" SG_ 280 ALR_Ist_Proz 0;
BA_ "GenSigStartValue" SG_ 280 ALR_Ist_Proz 254;
BA_ "Fehlerwert" SG_ 280 ALR_Ist_Proz 255;
BA_ "GenSigSendType" SG_ 280 ALR_Sendestatus 6;
BA_ "GenSigSendType" SG_ 280 ALR_Sta_Laengssperre 0;
BA_ "GenSigSendType" SG_ 280 ALR_Warnlampe 0;
BA_ "GenSigSendType" SG_ 308 ALR_gMeter_ax 0;
BA_ "GenSigStartValue" SG_ 308 ALR_gMeter_ax 1022;
BA_ "Fehlerwert" SG_ 308 ALR_gMeter_ax 1023;
BA_ "GenSigSendType" SG_ 308 ALR_gMeter_ay 0;
BA_ "GenSigStartValue" SG_ 308 ALR_gMeter_ay 1022;
BA_ "Fehlerwert" SG_ 308 ALR_gMeter_ay 1023;
BA_ "GenSigSendType" SG_ 1633 AAG_Anhaenger_abgesteckt 0;
BA_ "GenSigSwitchedByIgnition" SG_ 1633 AAG_Anhaenger_abgesteckt 0;
BA_ "GenSigSendType" SG_ 1633 AAG_Anhaenger_erkannt 0;
BA_ "NWM-WakeupAllowed" SG_ 1633 AAG_Anhaenger_erkannt 1;
BA_ "GenSigSwitchedByIgnition" SG_ 1633 AAG_Anhaenger_erkannt 0;
BA_ "GenSigSendType" SG_ 1633 AAG_AVS_Fehler_02 0;
BA_ "GenSigSwitchedByIgnition" SG_ 1633 AAG_AVS_Fehler_02 0;
BA_ "Fehlerwert" SG_ 1633 AAG_AVS_Fehler_02 1;
BA_ "GenSigSendType" SG_ 1633 AAG_AVS_Fehler_02_inv 0;
BA_ "GenSigStartValue" SG_ 1633 AAG_AVS_Fehler_02_inv 1;
BA_ "GenSigSwitchedByIgnition" SG_ 1633 AAG_AVS_Fehler_02_inv 0;
BA_ "GenSigSendType" SG_ 1633 AAG_AVS_Stati 0;
BA_ "GenSigSwitchedByIgnition" SG_ 1633 AAG_AVS_Stati 0;
BA_ "GenSigSendType" SG_ 1633 AAG_Blinker_H_aktiv 0;
BA_ "GenSigSwitchedByIgnition" SG_ 1633 AAG_Blinker_H_aktiv 0;
BA_ "GenSigSendType" SG_ 1633 AAG_Blinker_HL_def 0;
BA_ "GenSigSwitchedByIgnition" SG_ 1633 AAG_Blinker_HL_def 0;
BA_ "GenSigSendType" SG_ 1633 AAG_Blinker_HR_def 0;
BA_ "GenSigSwitchedByIgnition" SG_ 1633 AAG_Blinker_HR_def 0;
BA_ "GenSigSendType" SG_ 1633 AAG_Bremsl_durch_ECD 0;
BA_ "GenSigSwitchedByIgnition" SG_ 1633 AAG_Bremsl_durch_ECD 0;
BA_ "GenSigSendType" SG_ 1633 AAG_Bremslicht_H_def 0;
BA_ "GenSigSwitchedByIgnition" SG_ 1633 AAG_Bremslicht_H_def 0;
BA_ "GenSigSendType" SG_ 1633 AAG_Bremslicht_Reku 0;
BA_ "GenSigSwitchedByIgnition" SG_ 1633 AAG_Bremslicht_Reku 0;
BA_ "GenSigSendType" SG_ 1633 AAG_BZ 0;
BA_ "GenSigFuncType" SG_ 1633 AAG_BZ 1;
BA_ "GenSigSwitchedByIgnition" SG_ 1633 AAG_BZ 0;
BA_ "GenSigSendType" SG_ 1633 AAG_LED_aktiv 0;
BA_ "GenSigSwitchedByIgnition" SG_ 1633 AAG_LED_aktiv 0;
BA_ "GenSigSendType" SG_ 1633 AAG_NSL_aktiv 0;
BA_ "GenSigSwitchedByIgnition" SG_ 1633 AAG_NSL_aktiv 0;
BA_ "GenSigSendType" SG_ 1633 AAG_Schlusslicht_HL_def 0;
BA_ "GenSigSwitchedByIgnition" SG_ 1633 AAG_Schlusslicht_HL_def 0;
BA_ "GenSigSendType" SG_ 1633 AAG_Schlusslicht_HR_def 0;
BA_ "GenSigSwitchedByIgnition" SG_ 1633 AAG_Schlusslicht_HR_def 0;
BA_ "GenSigSendType" SG_ 2527679661 AWV_AW_Abstand 3;
BA_ "GenSigStartValue" SG_ 2527679661 AWV_AW_Abstand 511;
BA_ "GenSigSendType" SG_ 2527679661 AWV_AW_Texte 3;
BA_ "GenSigSendType" SG_ 2527679661 AWV_AW_Texte_Zusatzanzeige 3;
BA_ "GenSigSendType" SG_ 2527679661 AWV_AW_Zeitluecke 3;
BA_ "GenSigSendType" SG_ 2527679661 AWV_Einstellung_System_FSG 3;
BA_ "GenSigSendType" SG_ 2527679661 AWV_Einstellung_Warnung_FSG 3;
BA_ "GenSigSendType" SG_ 2527679661 AWV_KA_Konfiguration 3;
BA_ "GenSigSendType" SG_ 2527679661 AWV_KA_ObjektFront 3;
BA_ "GenSigSendType" SG_ 2527679661 AWV_Kamera_Objekt_ID 3;
BA_ "GenSigSwitchedByIgnition" SG_ 2527679661 AWV_Kamera_Objekt_ID 0;
BA_ "GenSigSendType" SG_ 2527679661 AWV_LED_Leiste 3;
BA_ "GenSigSendType" SG_ 2527679661 AWV_Priowarnung 3;
BA_ "GenSigSendType" SG_ 2527679661 AWV_Status_Anzeige 3;
BA_ "GenSigSendType" SG_ 2527679661 AWV_Texte_02 3;
BA_ "GenSigSendType" SG_ 2527679661 AWV_Warnlevel 3;
BA_ "GenSigSendType" SG_ 2527679661 AWV_Warnung 3;
BA_ "GenSigSendType" SG_ 2527679661 AWV_Warnung_Richtung 3;
BA_ "GenSigSendType" SG_ 2527679661 WBA_Warnblinken 3;
BA_ "GenSigSendType" SG_ 219 AWV_03_BZ 0;
BA_ "GenSigFuncType" SG_ 219 AWV_03_BZ 1;
BA_ "GenSigSwitchedByIgnition" SG_ 219 AWV_03_BZ 0;
BA_ "GenSigSendType" SG_ 219 AWV_03_CRC 0;
BA_ "GenSigFuncType" SG_ 219 AWV_03_CRC 2;
BA_ "GenSigSwitchedByIgnition" SG_ 219 AWV_03_CRC 0;
BA_ "GenSigSendType" SG_ 219 AWV_Anf_Prefill 0;
BA_ "GenSigSendType" SG_ 219 AWV_Eingriff_Sendeart 9;
BA_ "GenSigSendType" SG_ 219 AWV_Fahrerbremswunsch_erf 0;
BA_ "GenSigSendType" SG_ 219 AWV_HBA_Param 0;
BA_ "GenSigSendType" SG_ 219 AWV_QFK_AnfStat 0;
BA_ "GenSigStartValue" SG_ 219 AWV_QFK_AnfStat 1;
BA_ "GenSigSendType" SG_ 219 AWV_QFK_Art1 0;
BA_ "GenSigSendType" SG_ 219 AWV_QFK_Art2 0;
BA_ "GenSigSendType" SG_ 219 AWV_QFK_KrSoll 0;
BA_ "GenSigStartValue" SG_ 219 AWV_QFK_KrSoll 65535;
BA_ "GenSigSendType" SG_ 219 AWV_QFK_KrSoll_VZ 0;
BA_ "GenSigSendType" SG_ 219 AWV_QFK_KruemmSoll 0;
BA_ "GenSigSendType" SG_ 219 AWV_QFK_KruemmSoll_VZ 0;
BA_ "GenSigSendType" SG_ 219 AWV_QFK_Signal1 0;
BA_ "GenSigSendType" SG_ 219 AWV_QFK_Signal2 0;
BA_ "GenSigSendType" SG_ 219 AWV_QFK_Spuerb 0;
BA_ "GenSigSendType" SG_ 219 AWV_Ruckprofil 0;
BA_ "GenSigSendType" SG_ 219 AWV_Status_AWU 0;
BA_ "GenSigStartValue" SG_ 219 AWV_Status_AWU 14;
BA_ "GenSigSendType" SG_ 219 AWV_Time_to_brake 0;
BA_ "GenSigStartValue" SG_ 219 AWV_Time_to_brake 127;
BA_ "GenSigSendType" SG_ 219 AWV_Time_to_collision 0;
BA_ "GenSigStartValue" SG_ 219 AWV_Time_to_collision 255;
BA_ "GenSigSwitchedByIgnition" SG_ 219 AWV_Time_to_collision 0;
BA_ "GenSigSendType" SG_ 219 AWV_Timestamp_TTC 0;
BA_ "GenSigStartValue" SG_ 219 AWV_Timestamp_TTC 8191;
BA_ "GenSigSendType" SG_ 219 AWV_Verz_Anf 0;
BA_ "GenSigStartValue" SG_ 219 AWV_Verz_Anf 1023;
BA_ "GenSigSendType" SG_ 219 AWV_Verz_Anf_ASIL 0;
BA_ "GenSigSendType" SG_ 219 AWV_Verz_Freigabe 0;
BA_ "GenSigSendType" SG_ 219 AWV_Zielobjekttyp 0;
BA_ "GenSigStartValue" SG_ 219 AWV_Zielobjekttyp 15;
BA_ "GenSigSendType" SG_ 219 PCF_Freigabe 0;
BA_ "GenSigSendType" SG_ 219 SDF_PSF_CU_Status 0;
BA_ "GenSigSendType" SG_ 219 SDF_PSF_CW 0;
BA_ "GenSigStartValue" SG_ 219 SDF_PSF_CW 126;
BA_ "Fehlerwert" SG_ 219 SDF_PSF_CW 127;
BA_ "GenSigSendType" SG_ 219 SDF_PSF_Fahrer_aktiv 0;
BA_ "GenSigStartValue" SG_ 219 SDF_PSF_Fahrer_aktiv 1;
BA_ "GenSigSendType" SG_ 219 SDF_PSF_Guete 0;
BA_ "GenSigSendType" SG_ 219 SDF_PSF_Kollisionsueberdeckung 0;
BA_ "GenSigStartValue" SG_ 219 SDF_PSF_Kollisionsueberdeckung 30;
BA_ "Fehlerwert" SG_ 219 SDF_PSF_Kollisionsueberdeckung 31;
BA_ "GenSigSendType" SG_ 219 SDF_PSF_Objektstatus 0;
BA_ "Fehlerwert" SG_ 219 SDF_PSF_Objektstatus 7;
BA_ "GenSigSendType" SG_ 219 SDF_PSF_Time_To_Collision 0;
BA_ "GenSigStartValue" SG_ 219 SDF_PSF_Time_To_Collision 254;
BA_ "Fehlerwert" SG_ 219 SDF_PSF_Time_To_Collision 255;
BA_ "GenSigSendType" SG_ 219 SDF_PSF_v_rel 0;
BA_ "GenSigStartValue" SG_ 219 SDF_PSF_v_rel 254;
BA_ "Fehlerwert" SG_ 219 SDF_PSF_v_rel 255;
BA_ "GenSigSendType" SG_ 219 SOK_AWV_03_Signatur 0;
BA_ "GenSigFuncType" SG_ 219 SOK_AWV_03_Signatur 15;
BA_ "GenSigSwitchedByIgnition" SG_ 219 SOK_AWV_03_Signatur 0;
BA_ "GenSigSendType" SG_ 2536711680 BAP_Brake_ASG_01_Header 3;
BA_ "GenSigSwitchedByIgnition" SG_ 2536711680 BAP_Brake_ASG_01_Header 0;
BA_ "GenSigSendType" SG_ 2536711696 BAP_Brake_FSG_01_Header 3;
BA_ "GenSigSwitchedByIgnition" SG_ 2536711696 BAP_Brake_FSG_01_Header 0;
BA_ "GenSigSendType" SG_ 2536767264 BAP_Debug_Cmd 3;
BA_ "GenSigSwitchedByIgnition" SG_ 2536767264 BAP_Debug_Cmd 0;
BA_ "GenSigSendType" SG_ 2536767280 BAP_Debug_Data 3;
BA_ "GenSigSwitchedByIgnition" SG_ 2536767280 BAP_Debug_Data 0;
BA_ "GenSigSendType" SG_ 2536703744 BAP_RDK_ASG_01_Header 3;
BA_ "GenSigSwitchedByIgnition" SG_ 2536703744 BAP_RDK_ASG_01_Header 0;
BA_ "GenSigSendType" SG_ 2536703745 BAP_RDK_ASG_02_Header 3;
BA_ "GenSigSwitchedByIgnition" SG_ 2536703745 BAP_RDK_ASG_02_Header 0;
BA_ "GenSigSendType" SG_ 2536703760 BAP_RDK_FSG_01_Header 3;
BA_ "GenSigSwitchedByIgnition" SG_ 2536703760 BAP_RDK_FSG_01_Header 0;
BA_ "GenSigSendType" SG_ 1626 APS_Tongeber_defekt 3;
BA_ "GenSigSwitchedByIgnition" SG_ 1626 APS_Tongeber_defekt 0;
BA_ "GenSigSendType" SG_ 1626 BCM1_AFS_Lampe 3;
BA_ "GenSigSwitchedByIgnition" SG_ 1626 BCM1_AFS_Lampe 0;
BA_ "GenSigSendType" SG_ 1626 BCM1_EasyEntry_Status 3;
BA_ "GenSigSwitchedByIgnition" SG_ 1626 BCM1_EasyEntry_Status 0;
BA_ "GenSigSendType" SG_ 1626 BCM1_Fahrlicht_Hinweis 3;
BA_ "GenSigSwitchedByIgnition" SG_ 1626 BCM1_Fahrlicht_Hinweis 0;
BA_ "GenSigSendType" SG_ 1626 BCM1_Hinweis_Lichtnachlauf 3;
BA_ "GenSigSwitchedByIgnition" SG_ 1626 BCM1_Hinweis_Lichtnachlauf 0;
BA_ "GenSigSendType" SG_ 1626 BCM1_Kl_15_HW_erkannt 3;
BA_ "GenSigSwitchedByIgnition" SG_ 1626 BCM1_Kl_15_HW_erkannt 0;
BA_ "GenSigSendType" SG_ 1626 BCM1_Kl_15_Sig_HW_erkannt 3;
BA_ "GenSigSwitchedByIgnition" SG_ 1626 BCM1_Kl_15_Sig_HW_erkannt 0;
BA_ "GenSigSendType" SG_ 1626 BCM1_LDS_Stellung 3;
BA_ "GenSigSwitchedByIgnition" SG_ 1626 BCM1_LDS_Stellung 0;
BA_ "Fehlerwert" SG_ 1626 BCM1_LDS_Stellung 7;
BA_ "GenSigSendType" SG_ 1626 BCM1_Lenksaeule_aktiv 3;
BA_ "GenSigSwitchedByIgnition" SG_ 1626 BCM1_Lenksaeule_aktiv 0;
BA_ "GenSigSendType" SG_ 1626 BCM1_Licht_Warn 3;
BA_ "GenSigSwitchedByIgnition" SG_ 1626 BCM1_Licht_Warn 0;
BA_ "GenSigSendType" SG_ 1626 BCM1_Lichtwarn_Texte 3;
BA_ "GenSigSwitchedByIgnition" SG_ 1626 BCM1_Lichtwarn_Texte 0;
BA_ "GenSigSendType" SG_ 1626 BCM1_MH_Schalter 3;
BA_ "GenSigSwitchedByIgnition" SG_ 1626 BCM1_MH_Schalter 0;
BA_ "GenSigSendType" SG_ 1626 BCM1_MH_WIV_Schalter 3;
BA_ "GenSigSwitchedByIgnition" SG_ 1626 BCM1_MH_WIV_Schalter 0;
BA_ "GenSigSendType" SG_ 1626 BCM1_NV_Taster 0;
BA_ "GenSigSwitchedByIgnition" SG_ 1626 BCM1_NV_Taster 0;
BA_ "GenSigSendType" SG_ 1626 BCM1_Reisemodus_Texte 3;
BA_ "GenSigSwitchedByIgnition" SG_ 1626 BCM1_Reisemodus_Texte 0;
BA_ "GenSigSendType" SG_ 1626 BCM1_Rueckfahrlicht_Schalter 3;
BA_ "GenSigSwitchedByIgnition" SG_ 1626 BCM1_Rueckfahrlicht_Schalter 0;
BA_ "GenSigSendType" SG_ 1626 BCM1_Spannungs_Anf 3;
BA_ "GenSigSwitchedByIgnition" SG_ 1626 BCM1_Spannungs_Anf 0;
BA_ "GenSigSendType" SG_ 1626 BCM1_Valet_Parking_Taster 0;
BA_ "GenSigSwitchedByIgnition" SG_ 1626 BCM1_Valet_Parking_Taster 0;
BA_ "GenSigSendType" SG_ 1626 BCM1_Warnblink_Taster 3;
BA_ "GenSigSwitchedByIgnition" SG_ 1626 BCM1_Warnblink_Taster 0;
BA_ "GenSigSendType" SG_ 1626 BCM_Anf_AAW_MoLaWa 3;
BA_ "GenSigSwitchedByIgnition" SG_ 1626 BCM_Anf_AAW_MoLaWa 0;
BA_ "GenSigSendType" SG_ 1626 BCM_Bremsbelag_Sensor 3;
BA_ "GenSigSwitchedByIgnition" SG_ 1626 BCM_Bremsbelag_Sensor 0;
BA_ "GenSigSendType" SG_ 1626 BCM_Bremsfluessigkeit_Sensor 3;
BA_ "GenSigSwitchedByIgnition" SG_ 1626 BCM_Bremsfluessigkeit_Sensor 0;
BA_ "GenSigSendType" SG_ 1626 BCM_Charisma_Taste2 3;
BA_ "GenSigSwitchedByIgnition" SG_ 1626 BCM_Charisma_Taste2 0;
BA_ "GenSigSendType" SG_ 1626 BCM_Eco_Charisma_Taste 3;
BA_ "GenSigSwitchedByIgnition" SG_ 1626 BCM_Eco_Charisma_Taste 0;
BA_ "GenSigSendType" SG_ 1626 BCM_Handbremse_Hinweis 4;
BA_ "GenSigSwitchedByIgnition" SG_ 1626 BCM_Handbremse_Hinweis 0;
BA_ "GenSigSendType" SG_ 1626 BCM_HBFS_EOE_aktiv 4;
BA_ "GenSigSwitchedByIgnition" SG_ 1626 BCM_HBFS_EOE_aktiv 0;
BA_ "GenSigSendType" SG_ 1626 BCM_HDF_betaetigt 4;
BA_ "GenSigSwitchedByIgnition" SG_ 1626 BCM_HDF_betaetigt 0;
BA_ "GenSigSendType" SG_ 1626 BCM_HFS_EOE_aktiv 4;
BA_ "GenSigSwitchedByIgnition" SG_ 1626 BCM_HFS_EOE_aktiv 0;
BA_ "GenSigSendType" SG_ 1626 BCM_Hybrid_StartStopp_Taste 3;
BA_ "GenSigSwitchedByIgnition" SG_ 1626 BCM_Hybrid_StartStopp_Taste 0;
BA_ "GenSigSendType" SG_ 1626 BCM_Hybrid_StSt_Taste_Fehler 3;
BA_ "GenSigSwitchedByIgnition" SG_ 1626 BCM_Hybrid_StSt_Taste_Fehler 0;
BA_ "GenSigSendType" SG_ 1626 BCM_Kuehlmittel_Sensor 3;
BA_ "GenSigSwitchedByIgnition" SG_ 1626 BCM_Kuehlmittel_Sensor 0;
BA_ "GenSigSendType" SG_ 1626 BCM_Kuehlmittel_Sensor_02 3;
BA_ "GenSigSwitchedByIgnition" SG_ 1626 BCM_Kuehlmittel_Sensor_02 0;
BA_ "GenSigSendType" SG_ 1626 BCM_Offroad_Taste 3;
BA_ "GenSigSwitchedByIgnition" SG_ 1626 BCM_Offroad_Taste 0;
BA_ "GenSigSendType" SG_ 1626 BCM_ValetTaster_Fkts_LED 4;
BA_ "GenSigSwitchedByIgnition" SG_ 1626 BCM_ValetTaster_Fkts_LED 0;
BA_ "GenSigSendType" SG_ 1626 BCM_Waehlhebel_P_Hinweis 4;
BA_ "GenSigSwitchedByIgnition" SG_ 1626 BCM_Waehlhebel_P_Hinweis 0;
BA_ "GenSigSendType" SG_ 1626 BCM_Waschwasser_Sensor 3;
BA_ "GenSigSwitchedByIgnition" SG_ 1626 BCM_Waschwasser_Sensor 0;
BA_ "GenSigSendType" SG_ 1626 DWA_Alarmquelle 0;
BA_ "GenSigStartValue" SG_ 1626 DWA_Alarmquelle 30;
BA_ "GenSigSwitchedByIgnition" SG_ 1626 DWA_Alarmquelle 0;
BA_ "Fehlerwert" SG_ 1626 DWA_Alarmquelle 31;
BA_ "GenSigSendType" SG_ 1626 DWA_Einschraenkung 0;
BA_ "GenSigSwitchedByIgnition" SG_ 1626 DWA_Einschraenkung 0;
BA_ "Fehlerwert" SG_ 1626 DWA_Einschraenkung 1;
BA_ "GenSigSendType" SG_ 1626 Gong_TFL_Umschaltung 3;
BA_ "GenSigSwitchedByIgnition" SG_ 1626 Gong_TFL_Umschaltung 0;
BA_ "GenSigSendType" SG_ 1626 LRH_Taster 3;
BA_ "GenSigSwitchedByIgnition" SG_ 1626 LRH_Taster 0;
BA_ "GenSigSendType" SG_ 2527679939 BDM_I_U_VorgabeZwang_2 0;
BA_ "GenSigSwitchedByIgnition" SG_ 2527679939 BDM_I_U_VorgabeZwang_2 0;
BA_ "GenSigSendType" SG_ 2527679939 BDM_Kommunikationsbasis_2 0;
BA_ "GenSigStartValue" SG_ 2527679939 BDM_Kommunikationsbasis_2 1;
BA_ "GenSigSwitchedByIgnition" SG_ 2527679939 BDM_Kommunikationsbasis_2 0;
BA_ "GenSigSendType" SG_ 2527679939 BDM_Kuehlung_Anf 0;
BA_ "GenSigSwitchedByIgnition" SG_ 2527679939 BDM_Kuehlung_Anf 0;
BA_ "GenSigSendType" SG_ 2527679939 BDM_LiIon_Status_2 0;
BA_ "GenSigSwitchedByIgnition" SG_ 2527679939 BDM_LiIon_Status_2 0;
BA_ "GenSigSendType" SG_ 2527679939 BDM_LiIon_Zellenanzahl_2 0;
BA_ "GenSigSwitchedByIgnition" SG_ 2527679939 BDM_LiIon_Zellenanzahl_2 0;
BA_ "GenSigSendType" SG_ 2527679939 BDM_TE_Diagnose_2 0;
BA_ "GenSigSwitchedByIgnition" SG_ 2527679939 BDM_TE_Diagnose_2 0;
BA_ "GenSigSendType" SG_ 2527679939 BDM_TE_Status_2 0;
BA_ "GenSigSwitchedByIgnition" SG_ 2527679939 BDM_TE_Status_2 0;
BA_ "GenSigSendType" SG_ 2527679939 BDM_Variante 0;
BA_ "GenSigSwitchedByIgnition" SG_ 2527679939 BDM_Variante 0;
BA_ "GenSigSendType" SG_ 2527679939 BDM_ZellStatus_Index_2 0;
BA_ "GenSigSwitchedByIgnition" SG_ 2527679939 BDM_ZellStatus_Index_2 0;
BA_ "GenSigSendType" SG_ 2527679939 BDM_ZellStatus_Inhalt_2 0;
BA_ "GenSigSwitchedByIgnition" SG_ 2527679939 BDM_ZellStatus_Inhalt_2 0;
BA_ "GenSigSendType" SG_ 2527679939 BDM_ZellStatus_Typ_2 0;
BA_ "GenSigSwitchedByIgnition" SG_ 2527679939 BDM_ZellStatus_Typ_2 0;
BA_ "GenSigSendType" SG_ 2527679939 BDM_ZellTechnologie_2 0;
BA_ "GenSigStartValue" SG_ 2527679939 BDM_ZellTechnologie_2 15;
BA_ "GenSigSwitchedByIgnition" SG_ 2527679939 BDM_ZellTechnologie_2 0;
BA_ "GenSigSendType" SG_ 2527679939 BDMs_LiIon2_BZ 0;
BA_ "GenSigFuncType" SG_ 2527679939 BDMs_LiIon2_BZ 1;
BA_ "GenSigSwitchedByIgnition" SG_ 2527679939 BDMs_LiIon2_BZ 0;
BA_ "GenSigSendType" SG_ 2527679939 BDMs_LiIon2_CRC 0;
BA_ "GenSigFuncType" SG_ 2527679939 BDMs_LiIon2_CRC 2;
BA_ "GenSigSwitchedByIgnition" SG_ 2527679939 BDMs_LiIon2_CRC 0;
BA_ "GenSigSendType" SG_ 2527679939 BDMs_LiIon2_Dummy_2_6 0;
BA_ "GenSigSwitchedByIgnition" SG_ 2527679939 BDMs_LiIon2_Dummy_2_6 0;
BA_ "GenSigSendType" SG_ 2527679939 BDMs_LiIon2_Dummy_8_7 0;
BA_ "GenSigSwitchedByIgnition" SG_ 2527679939 BDMs_LiIon2_Dummy_8_7 0;
BA_ "GenSigSendType" SG_ 2527679939 BZE_Q_FuSi 0;
BA_ "GenSigStartValue" SG_ 2527679939 BZE_Q_FuSi 126;
BA_ "GenSigSwitchedByIgnition" SG_ 2527679939 BZE_Q_FuSi 0;
BA_ "Fehlerwert" SG_ 2527679939 BZE_Q_FuSi 127;
BA_ "GenSigSendType" SG_ 2527679939 BZE_Qe_Bereich_2 0;
BA_ "GenSigStartValue" SG_ 2527679939 BZE_Qe_Bereich_2 1;
BA_ "GenSigSwitchedByIgnition" SG_ 2527679939 BZE_Qe_Bereich_2 0;
BA_ "GenSigSendType" SG_ 2527679939 BZE_SOF_3Pol 0;
BA_ "GenSigStartValue" SG_ 2527679939 BZE_SOF_3Pol 1;
BA_ "GenSigSwitchedByIgnition" SG_ 2527679939 BZE_SOF_3Pol 0;
BA_ "GenSigSendType" SG_ 2527679939 BZE_ZwangGrund 0;
BA_ "GenSigSwitchedByIgnition" SG_ 2527679939 BZE_ZwangGrund 0;
BA_ "GenSigSendType" SG_ 869 BEM_Anf_KL 0;
BA_ "GenSigSwitchedByIgnition" SG_ 869 BEM_Anf_KL 0;
BA_ "GenSigSendType" SG_ 869 BEM_Batt_Ab 0;
BA_ "GenSigSwitchedByIgnition" SG_ 869 BEM_Batt_Ab 0;
BA_ "GenSigSendType" SG_ 869 BEM_DFM 0;
BA_ "GenSigSwitchedByIgnition" SG_ 869 BEM_DFM 0;
BA_ "GenSigSendType" SG_ 869 BEM_EMLIN_ungueltig 0;
BA_ "GenSigSwitchedByIgnition" SG_ 869 BEM_EMLIN_ungueltig 0;
BA_ "GenSigSendType" SG_ 869 BEM_HYB_DC_uMinLV 0;
BA_ "GenSigStartValue" SG_ 869 BEM_HYB_DC_uMinLV 254;
BA_ "GenSigSwitchedByIgnition" SG_ 869 BEM_HYB_DC_uMinLV 0;
BA_ "Fehlerwert" SG_ 869 BEM_HYB_DC_uMinLV 255;
BA_ "GenSigSendType" SG_ 869 BEM_HYB_DC_uSollLV 0;
BA_ "GenSigStartValue" SG_ 869 BEM_HYB_DC_uSollLV 37;
BA_ "GenSigSwitchedByIgnition" SG_ 869 BEM_HYB_DC_uSollLV 0;
BA_ "GenSigSendType" SG_ 869 BEM_n_LLA 0;
BA_ "GenSigSwitchedByIgnition" SG_ 869 BEM_n_LLA 0;
BA_ "GenSigSendType" SG_ 869 BEM_P_Generator 0;
BA_ "GenSigSwitchedByIgnition" SG_ 869 BEM_P_Generator 0;
BA_ "Fehlerwert" SG_ 869 BEM_P_Generator 255;
BA_ "GenSigSendType" SG_ 869 BEM_Segel_Info 0;
BA_ "GenSigSwitchedByIgnition" SG_ 869 BEM_Segel_Info 0;
BA_ "GenSigSendType" SG_ 869 BEM_StartStopp_Info 0;
BA_ "GenSigSwitchedByIgnition" SG_ 869 BEM_StartStopp_Info 0;
BA_ "GenSigSendType" SG_ 869 BEM_UBDM 0;
BA_ "GenSigSwitchedByIgnition" SG_ 869 BEM_UBDM 0;
BA_ "Fehlerwert" SG_ 869 BEM_UBDM 255;
BA_ "GenSigSendType" SG_ 869 NVEM_Abschaltstufe 0;
BA_ "GenSigSwitchedByIgnition" SG_ 869 NVEM_Abschaltstufe 0;
BA_ "GenSigSendType" SG_ 869 NVEM_FMAus_I_Verbrauch 0;
BA_ "GenSigStartValue" SG_ 869 NVEM_FMAus_I_Verbrauch 30;
BA_ "GenSigSwitchedByIgnition" SG_ 869 NVEM_FMAus_I_Verbrauch 0;
BA_ "Fehlerwert" SG_ 869 NVEM_FMAus_I_Verbrauch 31;
BA_ "GenSigSendType" SG_ 869 NVEM_FMAus_Info 0;
BA_ "GenSigStartValue" SG_ 869 NVEM_FMAus_Info 1;
BA_ "GenSigSwitchedByIgnition" SG_ 869 NVEM_FMAus_Info 0;
BA_ "GenSigSendType" SG_ 869 NVEM_Freilauf_Info 0;
BA_ "GenSigSwitchedByIgnition" SG_ 869 NVEM_Freilauf_Info 0;
BA_ "GenSigSendType" SG_ 869 NVEM_Ladefreigabe 0;
BA_ "GenSigSwitchedByIgnition" SG_ 869 NVEM_Ladefreigabe 0;
BA_ "GenSigSendType" SG_ 869 NVEM_P_Generator_Status 0;
BA_ "GenSigSwitchedByIgnition" SG_ 869 NVEM_P_Generator_Status 0;
BA_ "GenSigSendType" SG_ 869 NVEM_PTC_Sollstufe 0;
BA_ "GenSigSwitchedByIgnition" SG_ 869 NVEM_PTC_Sollstufe 0;
BA_ "GenSigSendType" SG_ 869 NVEM_Red_KL 0;
BA_ "GenSigSwitchedByIgnition" SG_ 869 NVEM_Red_KL 0;
BA_ "GenSigSendType" SG_ 1163 BEM_06_BZ 0;
BA_ "GenSigFuncType" SG_ 1163 BEM_06_BZ 1;
BA_ "GenSigSwitchedByIgnition" SG_ 1163 BEM_06_BZ 0;
BA_ "GenSigSendType" SG_ 1163 BEM_06_CRC 0;
BA_ "GenSigFuncType" SG_ 1163 BEM_06_CRC 2;
BA_ "GenSigSwitchedByIgnition" SG_ 1163 BEM_06_CRC 0;
BA_ "GenSigSendType" SG_ 1163 HLR_PTC_linear_Freigabe 0;
BA_ "GenSigSwitchedByIgnition" SG_ 1163 HLR_PTC_linear_Freigabe 0;
BA_ "Fehlerwert" SG_ 1163 HLR_PTC_linear_Freigabe 63;
BA_ "GenSigSendType" SG_ 1163 NVEM2_Status_FuSiFahrt 0;
BA_ "GenSigSwitchedByIgnition" SG_ 1163 NVEM2_Status_FuSiFahrt 0;
BA_ "Fehlerwert" SG_ 1163 NVEM2_Status_FuSiFahrt 7;
BA_ "GenSigSendType" SG_ 1163 NVEM2_Typ_EnergieNetz 0;
BA_ "GenSigStartValue" SG_ 1163 NVEM2_Typ_EnergieNetz 15;
BA_ "GenSigSwitchedByIgnition" SG_ 1163 NVEM2_Typ_EnergieNetz 0;
BA_ "Fehlerwert" SG_ 1163 NVEM2_Typ_EnergieNetz 14;
BA_ "GenSigSendType" SG_ 1163 NVEM_Betriebsart 0;
BA_ "GenSigSwitchedByIgnition" SG_ 1163 NVEM_Betriebsart 0;
BA_ "Fehlerwert" SG_ 1163 NVEM_Betriebsart 15;
BA_ "GenSigSendType" SG_ 1163 NVEM_Bordnetzdiagnose 0;
BA_ "GenSigSwitchedByIgnition" SG_ 1163 NVEM_Bordnetzdiagnose 0;
BA_ "GenSigSendType" SG_ 1163 NVEM_Energie_Klima_Vorgabe 0;
BA_ "GenSigStartValue" SG_ 1163 NVEM_Energie_Klima_Vorgabe 254;
BA_ "GenSigSwitchedByIgnition" SG_ 1163 NVEM_Energie_Klima_Vorgabe 0;
BA_ "Fehlerwert" SG_ 1163 NVEM_Energie_Klima_Vorgabe 255;
BA_ "GenSigSendType" SG_ 1163 NVEM_Energienetz_Status 0;
BA_ "GenSigStartValue" SG_ 1163 NVEM_Energienetz_Status 6;
BA_ "GenSigSwitchedByIgnition" SG_ 1163 NVEM_Energienetz_Status 0;
BA_ "Fehlerwert" SG_ 1163 NVEM_Energienetz_Status 7;
BA_ "GenSigSendType" SG_ 1163 NVEM_Ladezustand 0;
BA_ "GenSigStartValue" SG_ 1163 NVEM_Ladezustand 126;
BA_ "GenSigSwitchedByIgnition" SG_ 1163 NVEM_Ladezustand 0;
BA_ "Fehlerwert" SG_ 1163 NVEM_Ladezustand 127;
BA_ "GenSigSendType" SG_ 1163 NVEM_Last_Anf 0;
BA_ "GenSigSwitchedByIgnition" SG_ 1163 NVEM_Last_Anf 0;
BA_ "GenSigSendType" SG_ 1163 NVEM_PTC_Sollstufe 0;
BA_ "GenSigSwitchedByIgnition" SG_ 1163 NVEM_PTC_Sollstufe 0;
BA_ "GenSigSendType" SG_ 1163 NVEM_Red_KomfortVerbrauch 0;
BA_ "GenSigSwitchedByIgnition" SG_ 1163 NVEM_Red_KomfortVerbrauch 0;
BA_ "Fehlerwert" SG_ 1163 NVEM_Red_KomfortVerbrauch 15;
BA_ "GenSigSendType" SG_ 1163 NVEM_STH_ZielzeitLang 0;
BA_ "GenSigStartValue" SG_ 1163 NVEM_STH_ZielzeitLang 14;
BA_ "GenSigSwitchedByIgnition" SG_ 1163 NVEM_STH_ZielzeitLang 0;
BA_ "Fehlerwert" SG_ 1163 NVEM_STH_ZielzeitLang 15;
BA_ "GenSigSendType" SG_ 1163 NVEM_Vorgabe_Leistungsstufe 0;
BA_ "GenSigSwitchedByIgnition" SG_ 1163 NVEM_Vorgabe_Leistungsstufe 0;
BA_ "Fehlerwert" SG_ 1163 NVEM_Vorgabe_Leistungsstufe 7;
BA_REL_ "GenSigTimeoutTime" BU_SG_REL_ Airbag SG_ 333 ACC_Status_ACC 500;
BA_REL_ "GenSigTimeoutTime" BU_SG_REL_ Airbag SG_ 2527679682 ACC_ASM_Ereignis 5000;
BA_REL_ "GenSigTimeoutTime" BU_SG_REL_ Airbag SG_ 2527679682 ACC_ASM_Zeitstempel_02 5000;
BA_REL_ "GenSigTimeoutTime" BU_SG_REL_ Airbag SG_ 2527679682 ACC_ASM_Data_1 5000;
BA_REL_ "GenSigTimeoutTime" BU_SG_REL_ Airbag SG_ 2527679682 ACC_ASM_Data_2 5000;
BA_REL_ "GenSigTimeoutTime" BU_SG_REL_ Airbag SG_ 2527679682 ACC_ASM_Data_3 5000;
BA_REL_ "GenSigTimeoutTime" BU_SG_REL_ Airbag SG_ 2527679682 ACC_ASM_Data_4 5000;
BA_REL_ "GenSigTimeoutTime" BU_SG_REL_ Airbag SG_ 2527679682 ACC_ASM_Data_5 5000;
BA_REL_ "GenSigTimeoutTime" BU_SG_REL_ Airbag SG_ 2527679682 ACC_ASM_Data_6 5000;
BA_REL_ "GenSigTimeoutTime" BU_SG_REL_ Airbag SG_ 2527679661 AWV_Warnung 2000;
BA_REL_ "GenSigTimeoutTime" BU_SG_REL_ Airbag SG_ 2527679661 AWV_Texte_02 2000;
BA_REL_ "GenSigTimeoutTime" BU_SG_REL_ Airbag SG_ 219 AWV_03_CRC 5000;
BA_REL_ "GenSigTimeoutTime" BU_SG_REL_ Airbag SG_ 219 AWV_03_BZ 5000;
BA_REL_ "GenSigTimeoutTime" BU_SG_REL_ Airbag SG_ 219 PCF_Freigabe 5000;
BA_REL_ "GenSigTimeoutTime" BU_SG_REL_ Airbag SG_ 219 SDF_PSF_Objektstatus 5000;
BA_REL_ "GenSigTimeoutTime" BU_SG_REL_ Airbag SG_ 219 SDF_PSF_CU_Status 5000;
BA_REL_ "GenSigTimeoutTime" BU_SG_REL_ Airbag SG_ 219 SDF_PSF_CW 5000;
BA_REL_ "GenSigTimeoutTime" BU_SG_REL_ Airbag SG_ 219 SDF_PSF_Guete 5000;
BA_REL_ "GenSigTimeoutTime" BU_SG_REL_ Airbag SG_ 219 SDF_PSF_Kollisionsueberdeckung 5000;
BA_REL_ "GenSigTimeoutTime" BU_SG_REL_ Airbag SG_ 219 SDF_PSF_v_rel 5000;
BA_REL_ "GenSigTimeoutTime" BU_SG_REL_ Airbag SG_ 219 AWV_Eingriff_Sendeart 5000;
BA_REL_ "GenSigTimeoutTime" BU_SG_REL_ Airbag SG_ 219 AWV_Verz_Freigabe 5000;
BA_REL_ "GenSigTimeoutTime" BU_SG_REL_ Airbag SG_ 219 AWV_Verz_Anf 5000;
BA_REL_ "GenSigTimeoutTime" BU_SG_REL_ Airbag SG_ 219 AWV_Anf_Prefill 5000;
BA_REL_ "GenSigTimeoutTime" BU_SG_REL_ Airbag SG_ 219 AWV_Ruckprofil 5000;
BA_REL_ "GenSigTimeoutTime" BU_SG_REL_ Airbag SG_ 219 AWV_Time_to_collision 5000;
BA_REL_ "GenSigTimeoutTime" BU_SG_REL_ Airbag SG_ 219 AWV_Zielobjekttyp 5000;
BA_REL_ "GenSigTimeoutTime" BU_SG_REL_ Airbag SG_ 219 AWV_QFK_AnfStat 5000;
BA_REL_ "GenSigTimeoutTime" BU_SG_REL_ Airbag SG_ 219 AWV_Timestamp_TTC 5000;
BA_REL_ "GenSigTimeoutTime" BU_SG_REL_ Airbag SG_ 219 AWV_Status_AWU 5000;
BA_REL_ "GenSigTimeoutTime" BU_SG_REL_ Airbag SG_ 1626 BCM1_Rueckfahrlicht_Schalter 5000;
BA_REL_ "GenSigTimeoutTime" BU_SG_REL_ Allrad_Haldex SG_ 1633 AAG_Anhaenger_erkannt 1000;
BA_REL_ "GenSigTimeoutTime" BU_SG_REL_ ESC_MQBW SG_ 333 ACC_18_CRC 500;
BA_REL_ "GenSigTimeoutTime" BU_SG_REL_ ESC_MQBW SG_ 333 ACC_18_BZ 500;
BA_REL_ "GenSigTimeoutTime" BU_SG_REL_ ESC_MQBW SG_ 333 ACC_Status_ACC 500;
BA_REL_ "GenSigTimeoutTime" BU_SG_REL_ ESC_MQBW SG_ 333 ACC_Anhalteweg 500;
BA_REL_ "GenSigTimeoutTime" BU_SG_REL_ ESC_MQBW SG_ 333 ACC_Anforderung_HMS 500;
BA_REL_ "GenSigTimeoutTime" BU_SG_REL_ ESC_MQBW SG_ 333 RDR_v_ueber_Grund 500;
BA_REL_ "GenSigTimeoutTime" BU_SG_REL_ ESC_MQBW SG_ 333 RDR_v_ueber_Grund_Genauigkeit 500;
BA_REL_ "GenSigTimeoutTime" BU_SG_REL_ ESC_MQBW SG_ 333 RDR_v_ueber_Grund_Fahrtrichtung 500;
BA_REL_ "GenSigTimeoutTime" BU_SG_REL_ ESC_MQBW SG_ 2589283872 Airbag_01_CALID_Index_01 5000;
BA_REL_ "GenSigTimeoutTime" BU_SG_REL_ ESC_MQBW SG_ 2589283872 Airbag_01_CALID_Index_02 5000;
BA_REL_ "GenSigTimeoutTime" BU_SG_REL_ ESC_MQBW SG_ 2589283872 Airbag_01_CALID_Index_03 5000;
BA_REL_ "GenSigTimeoutTime" BU_SG_REL_ ESC_MQBW SG_ 2589283872 Airbag_01_CALID_Index_04 5000;
BA_REL_ "GenSigTimeoutTime" BU_SG_REL_ ESC_MQBW SG_ 2589283872 Airbag_01_CALID_Index_05 5000;
BA_REL_ "GenSigTimeoutTime" BU_SG_REL_ ESC_MQBW SG_ 2589283872 Airbag_01_CALID_Index_06 5000;
BA_REL_ "GenSigTimeoutTime" BU_SG_REL_ ESC_MQBW SG_ 2589283872 Airbag_01_CALID_Index_07 5000;
BA_REL_ "GenSigTimeoutTime" BU_SG_REL_ ESC_MQBW SG_ 2589283872 Airbag_01_CALID_Index_08 5000;
BA_REL_ "GenSigTimeoutTime" BU_SG_REL_ ESC_MQBW SG_ 2589283872 Airbag_01_CALID_Index_09 5000;
BA_REL_ "GenSigTimeoutTime" BU_SG_REL_ ESC_MQBW SG_ 2589283872 Airbag_01_CALID_Index_10 5000;
BA_REL_ "GenSigTimeoutTime" BU_SG_REL_ ESC_MQBW SG_ 2589283872 Airbag_01_CALID_Index_11 5000;
BA_REL_ "GenSigTimeoutTime" BU_SG_REL_ ESC_MQBW SG_ 2589283872 Airbag_01_CALID_Index_12 5000;
BA_REL_ "GenSigTimeoutTime" BU_SG_REL_ ESC_MQBW SG_ 2589283872 Airbag_01_CALID_Index_13 5000;
BA_REL_ "GenSigTimeoutTime" BU_SG_REL_ ESC_MQBW SG_ 2589283872 Airbag_01_CALID_Index_14 5000;
BA_REL_ "GenSigTimeoutTime" BU_SG_REL_ ESC_MQBW SG_ 2589283872 Airbag_01_CALID_Index_15 5000;
BA_REL_ "GenSigTimeoutTime" BU_SG_REL_ ESC_MQBW SG_ 2589283872 Airbag_01_CALID_Index_16 5000;
BA_REL_ "GenSigTimeoutTime" BU_SG_REL_ ESC_MQBW SG_ 2589283873 Airbag_01_CVN_VLD 5000;
BA_REL_ "GenSigTimeoutTime" BU_SG_REL_ ESC_MQBW SG_ 2589283873 Airbag_01_CVN_Byte_1 5000;
BA_REL_ "GenSigTimeoutTime" BU_SG_REL_ ESC_MQBW SG_ 2589283873 Airbag_01_CVN_Byte_2 5000;
BA_REL_ "GenSigTimeoutTime" BU_SG_REL_ ESC_MQBW SG_ 2589283873 Airbag_01_CVN_Byte_3 5000;
BA_REL_ "GenSigTimeoutTime" BU_SG_REL_ ESC_MQBW SG_ 2589283873 Airbag_01_CVN_Byte_4 5000;
BA_REL_ "GenSigTimeoutTime" BU_SG_REL_ ESC_MQBW SG_ 64 Airbag_01_CRC 500;
BA_REL_ "GenSigTimeoutTime" BU_SG_REL_ ESC_MQBW SG_ 64 Airbag_01_BZ 500;
BA_REL_ "GenSigTimeoutTime" BU_SG_REL_ ESC_MQBW SG_ 64 AB_Front_Crash 500;
BA_REL_ "GenSigTimeoutTime" BU_SG_REL_ ESC_MQBW SG_ 64 AB_Heck_Crash 500;
BA_REL_ "GenSigTimeoutTime" BU_SG_REL_ ESC_MQBW SG_ 64 AB_SF_Crash 500;
BA_REL_ "GenSigTimeoutTime" BU_SG_REL_ ESC_MQBW SG_ 64 AB_SB_Crash 500;
BA_REL_ "GenSigTimeoutTime" BU_SG_REL_ ESC_MQBW SG_ 64 AB_Rollover_Crash 500;
BA_REL_ "GenSigTimeoutTime" BU_SG_REL_ ESC_MQBW SG_ 64 AB_Crash_Int 500;
BA_REL_ "GenSigTimeoutTime" BU_SG_REL_ ESC_MQBW SG_ 64 AB_MKB_Anforderung 500;
BA_REL_ "GenSigTimeoutTime" BU_SG_REL_ ESC_MQBW SG_ 64 AB_Gurtschloss_FA_ext 500;
BA_REL_ "GenSigTimeoutTime" BU_SG_REL_ ESC_MQBW SG_ 64 ASM_Masterzeit_02 500;
BA_REL_ "GenSigTimeoutTime" BU_SG_REL_ ESC_MQBW SG_ 1312 Airbag_02_CRC 2000;
BA_REL_ "GenSigTimeoutTime" BU_SG_REL_ ESC_MQBW SG_ 1312 Airbag_02_BZ 2000;
BA_REL_ "GenSigTimeoutTime" BU_SG_REL_ ESC_MQBW SG_ 1312 AB_Gurtschloss_FA 2000;
BA_REL_ "GenSigTimeoutTime" BU_SG_REL_ ESC_MQBW SG_ 1312 AB_Sitzpos_Sens_FA 2000;
BA_REL_ "GenSigTimeoutTime" BU_SG_REL_ ESC_MQBW SG_ 65 Airbag_03_CRC 5000;
BA_REL_ "GenSigTimeoutTime" BU_SG_REL_ ESC_MQBW SG_ 65 Airbag_03_BZ 5000;
BA_REL_ "GenSigTimeoutTime" BU_SG_REL_ ESC_MQBW SG_ 65 AB_MKB_Safing 5000;
BA_REL_ "GenSigTimeoutTime" BU_SG_REL_ ESC_MQBW SG_ 280 Allrad_03_BZ 1000;
BA_REL_ "GenSigTimeoutTime" BU_SG_REL_ ESC_MQBW SG_ 280 ALR_Sta_Laengssperre 1000;
BA_REL_ "GenSigTimeoutTime" BU_SG_REL_ ESC_MQBW SG_ 280 ALR_Sendestatus 1000;
BA_REL_ "GenSigTimeoutTime" BU_SG_REL_ ESC_MQBW SG_ 280 ALR_Ist_Proz 1000;
BA_REL_ "GenSigTimeoutTime" BU_SG_REL_ ESC_MQBW SG_ 1633 AAG_Bremsl_durch_ECD 1000;
BA_REL_ "GenSigTimeoutTime" BU_SG_REL_ ESC_MQBW SG_ 1633 AAG_Anhaenger_erkannt 1000;
BA_REL_ "GenSigTimeoutTime" BU_SG_REL_ ESC_MQBW SG_ 1633 AAG_Bremslicht_H_def 1000;
BA_REL_ "GenSigTimeoutTime" BU_SG_REL_ ESC_MQBW SG_ 219 AWV_03_CRC 5000;
BA_REL_ "GenSigTimeoutTime" BU_SG_REL_ ESC_MQBW SG_ 219 AWV_03_BZ 5000;
BA_REL_ "GenSigTimeoutTime" BU_SG_REL_ ESC_MQBW SG_ 219 SDF_PSF_Objektstatus 5000;
BA_REL_ "GenSigTimeoutTime" BU_SG_REL_ ESC_MQBW SG_ 219 AWV_Eingriff_Sendeart 5000;
BA_REL_ "GenSigTimeoutTime" BU_SG_REL_ ESC_MQBW SG_ 219 AWV_Verz_Freigabe 5000;
BA_REL_ "GenSigTimeoutTime" BU_SG_REL_ ESC_MQBW SG_ 219 AWV_Verz_Anf 5000;
BA_REL_ "GenSigTimeoutTime" BU_SG_REL_ ESC_MQBW SG_ 219 AWV_Anf_Prefill 5000;
BA_REL_ "GenSigTimeoutTime" BU_SG_REL_ ESC_MQBW SG_ 219 AWV_Ruckprofil 5000;
BA_REL_ "GenSigTimeoutTime" BU_SG_REL_ ESC_MQBW SG_ 219 AWV_HBA_Param 5000;
BA_REL_ "GenSigTimeoutTime" BU_SG_REL_ ESC_MQBW SG_ 219 AWV_Verz_Anf_ASIL 5000;
BA_REL_ "GenSigTimeoutTime" BU_SG_REL_ ESC_MQBW SG_ 219 AWV_Time_to_brake 5000;
BA_REL_ "GenSigTimeoutTime" BU_SG_REL_ ESC_MQBW SG_ 219 AWV_Zielobjekttyp 5000;
BA_REL_ "GenSigTimeoutTime" BU_SG_REL_ ESC_MQBW SG_ 219 AWV_Fahrerbremswunsch_erf 5000;
BA_REL_ "GenSigTimeoutTime" BU_SG_REL_ ESC_MQBW SG_ 2536711680 BAP_Brake_ASG_01_Header 800;
BA_REL_ "GenSigTimeoutTime" BU_SG_REL_ ESC_MQBW SG_ 2536703744 BAP_RDK_ASG_01_Header 800;
BA_REL_ "GenSigTimeoutTime" BU_SG_REL_ ESC_MQBW SG_ 2536703745 BAP_RDK_ASG_02_Header 800;
BA_REL_ "GenSigTimeoutTime" BU_SG_REL_ ESC_MQBW SG_ 1626 BCM_Offroad_Taste 5000;
BA_REL_ "GenSigTimeoutTime" BU_SG_REL_ ESC_MQBW SG_ 1626 BCM1_Rueckfahrlicht_Schalter 5000;
BA_REL_ "GenSigTimeoutTime" BU_SG_REL_ ESC_MQBW SG_ 869 BEM_P_Generator 500;
BA_REL_ "GenSigTimeoutTime" BU_SG_REL_ ESC_MQBW SG_ 869 BEM_Batt_Ab 500;
BA_REL_ "GenSigTimeoutTime" BU_SG_REL_ ESC_MQBW SG_ 1163 BEM_06_CRC 1000;
BA_REL_ "GenSigTimeoutTime" BU_SG_REL_ ESC_MQBW SG_ 1163 BEM_06_BZ 1000;
BA_REL_ "GenSigTimeoutTime" BU_SG_REL_ ESC_MQBW SG_ 1163 NVEM_Energienetz_Status 1000;
BA_REL_ "GenSigTimeoutTime" BU_SG_REL_ ESC_MQBW SG_ 1163 NVEM_Vorgabe_Leistungsstufe 1000;
BA_REL_ "GenSigTimeoutTime" BU_SG_REL_ ESC_MQBW SG_ 1163 NVEM_Bordnetzdiagnose 1000;
BA_REL_ "GenSigTimeoutTime" BU_SG_REL_ Gateway_Max SG_ 64 Airbag_01_CRC 500;
BA_REL_ "GenSigTimeoutTime" BU_SG_REL_ Gateway_Max SG_ 64 Airbag_01_BZ 500;
BA_REL_ "GenSigTimeoutTime" BU_SG_REL_ Gateway_Max SG_ 64 AB_Crash_Int 500;
BA_REL_ "GenSigTimeoutTime" BU_SG_REL_ Gateway_Max SG_ 64 AB_Deaktivierung_HV 500;
BA_REL_ "GenSigTimeoutTime" BU_SG_REL_ Gateway_Max SG_ 1312 AB_Belegung_VB 2000;
BA_REL_ "GenSigTimeoutTime" BU_SG_REL_ Gateway_Max SG_ 1312 AB_Gurtschloss_FA 2000;
BA_REL_ "GenSigTimeoutTime" BU_SG_REL_ Gateway_Max SG_ 1312 AB_Gurtschloss_BF 2000;
BA_REL_ "GenSigTimeoutTime" BU_SG_REL_ Gateway_Max SG_ 65 AB_MKB_Safing 5000;
BA_REL_ "GenSigTimeoutTime" BU_SG_REL_ Lenkhilfe_REPS SG_ 64 AB_Stellgliedtest 500;
BA_REL_ "GenSigTimeoutTime" BU_SG_REL_ Lenkhilfe_REPS SG_ 64 ASM_Masterzeit_02 500;
BA_REL_ "GenSigTimeoutTime" BU_SG_REL_ Lenkhilfe_REPS SG_ 280 ALR_Ist_Proz 1000;
BA_REL_ "GenSigTimeoutTime" BU_SG_REL_ Lenkhilfe_REPS SG_ 219 AWV_Eingriff_Sendeart 5000;
BA_REL_ "GenSigTimeoutTime" BU_SG_REL_ Lenkhilfe_REPS SG_ 219 AWV_QFK_KruemmSoll 5000;
BA_REL_ "GenSigTimeoutTime" BU_SG_REL_ Lenkhilfe_REPS SG_ 219 AWV_QFK_KruemmSoll_VZ 5000;
BA_REL_ "GenSigTimeoutTime" BU_SG_REL_ Lenkhilfe_REPS SG_ 219 AWV_QFK_Spuerb 5000;
BA_REL_ "GenSigTimeoutTime" BU_SG_REL_ Lenkhilfe_REPS SG_ 219 AWV_QFK_AnfStat 5000;
BA_REL_ "GenSigTimeoutTime" BU_SG_REL_ Lenkhilfe_REPS SG_ 219 AWV_QFK_Signal1 5000;
BA_REL_ "GenSigTimeoutTime" BU_SG_REL_ Lenkhilfe_REPS SG_ 219 AWV_QFK_Art1 5000;
BA_REL_ "GenSigTimeoutTime" BU_SG_REL_ Lenkhilfe_REPS SG_ 219 AWV_QFK_Art2 5000;
BA_REL_ "GenSigTimeoutTime" BU_SG_REL_ Lenkhilfe_REPS SG_ 219 AWV_QFK_Signal2 5000;
BA_REL_ "GenSigTimeoutTime" BU_SG_REL_ Lenkhilfe_REPS SG_ 219 AWV_QFK_KrSoll_VZ 5000;
BA_REL_ "GenSigTimeoutTime" BU_SG_REL_ Lenkhilfe_REPS SG_ 219 AWV_QFK_KrSoll 5000;
BA_REL_ "GenSigTimeoutTime" BU_SG_REL_ Lenkhilfe_REPS SG_ 1626 BCM1_Rueckfahrlicht_Schalter 5000;
BA_REL_ "GenSigTimeoutTime" BU_SG_REL_ Lenkhilfe_REPS SG_ 2527679939 BDMs_LiIon2_CRC 2000;
BA_REL_ "GenSigTimeoutTime" BU_SG_REL_ Lenkhilfe_REPS SG_ 2527679939 BDMs_LiIon2_BZ 2000;
BA_REL_ "GenSigTimeoutTime" BU_SG_REL_ Lenkhilfe_REPS SG_ 2527679939 BZE_SOF_3Pol 2000;
BA_REL_ "GenSigTimeoutTime" BU_SG_REL_ Lenkhilfe_REPS SG_ 869 BEM_Batt_Ab 500;
BA_REL_ "GenSigTimeoutTime" BU_SG_REL_ Lenkhilfe_REPS SG_ 1163 BEM_06_CRC 1000;
BA_REL_ "GenSigTimeoutTime" BU_SG_REL_ Lenkhilfe_REPS SG_ 1163 BEM_06_BZ 1000;
BA_REL_ "GenSigTimeoutTime" BU_SG_REL_ Lenkhilfe_REPS SG_ 1163 NVEM_Vorgabe_Leistungsstufe 1000;
BA_REL_ "GenSigTimeoutTime" BU_SG_REL_ Lenkhilfe_REPS SG_ 1163 NVEM_Bordnetzdiagnose 1000;
VAL_ 333 ACC_limitierte_Anfahrdyn 0 "keine_Limitierung" 1 "Limitierung_Anfahrdynamik_angefordert" ;
VAL_ 333 ACC_nachtr_Stopp_Anf 0 "nicht_angefordert" 1 "angefordert" ;
VAL_ 333 ACC_DynErhoehung 0 "normale_Verzoegerungsdynamik" 1 "erhoehte_Verzoegerungsdynamik" ;
VAL_ 333 ACC_Freilaufstrategie_TSK 0 "Freilaufstr_nicht_angefordert" 1 "Freilaufstr_angefordert" ;
VAL_ 333 ACC_StartStopp_Info 0 "Motorlauf_langfristig_nicht_notwendig_Stoppfreigabe" 1 "Motoranlauf_nicht_zwingend_notwendig_Stoppverbot_keine_Startanforderung" 2 "Motoranlauf_zwingend_notwendig_Startanforderung" 3 "Systemfehler" ;
VAL_ 333 ACC_Sollbeschleunigung_02 2046 "Neutralwert" 2047 "Fehler" ;
VAL_ 333 ACC_Anfahren 0 "keine_Anforderung_Anfahren" 1 "Anforderung_Anfahren" ;
VAL_ 333 ACC_Anhalten 0 "kein_Anhalten_gewuenscht" 1 "Anhalten_gewuenscht" ;
VAL_ 333 ACC_Typ 0 "Basis_ACC" 1 "ACC_mit_FollowToStop" 2 "ACC_mit_StopAndGo" 3 "ACC_nicht_codiert" ;
VAL_ 333 ACC_Status_ACC 0 "ACC_OFF_Hauptschalter_aus" 1 "ACC_INIT" 2 "ACC_STANDBY" 3 "ACC_AKTIV_regelt" 4 "ACC_OVERRIDE" 5 "ACC_Abschaltreaktion" 6 "reversibler_Fehler_im_ACC_System" 7 "irreversibler_Fehler_im_ACC_System" ;
VAL_ 333 ACC_Minimale_Bremsung 0 "Anforderung_Minimale_Bremsung_nicht_aktiv" 1 "Anforderung_Minimale_Bremsung_aktiv" ;
VAL_ 333 ACC_Anhalteweg 2046 "Neutralwert" 2047 "Fehler" ;
VAL_ 333 ACC_Boost 0 "Boost_nicht_aktiv" 1 "Boost_aktiv" ;
VAL_ 333 ACC_Freilauf_Anf 0 "keine Freilauf-Anforderung" 1 "Freilauf-Anforderung" ;
VAL_ 333 ACC_Anforderung_HMS 0 "keine_Anforderung" 1 "halten" 2 "parken" 3 "halten_Standby" 4 "anfahren" 5 "Loesen_ueber_Rampe" 7 "HMS_uebernehmen" ;
VAL_ 333 ACC_Folgebeschl 254 "Neutralwert" ;
VAL_ 333 ACC_Freilauf_Info 0 "Freilauf_freigegeben" 1 "Weiches_Veto_uebertippbar" 2 "Hartes_Veto_Abbruch" 3 "Freilauf_Anforderung" ;
VAL_ 333 ACC_Tempolimitassistent_Ein 0 "Tempolimitassistent_aus" 1 "Tempolimitassistent_ein" ;
VAL_ 333 ACC_FoD_Status 0 "Init" 1 "Funktion_inaktiv" 2 "Funktion_aktiv" ;
VAL_ 333 ACC_Blindheit_erkannt 0 "keine_Blindheit_erkannt" 1 "Blindheit_erkannt" ;
VAL_ 333 ACC_Verkehrssinn 0 "Init" 1 "Linksverkehr" 2 "Rechtsverkehr" 3 "Unbekannt" ;
VAL_ 333 ACC_relev_Nichtverfuegbarkeit 0 "verfuegbar" 1 "nicht_verfuegbar" ;
VAL_ 333 ACC_relevanter_Fehler 0 "kein_relevanter_Fehler" 1 "relevanter_Fehler" ;
VAL_ 333 ACC_TA_Kurve_Abstand 61 "groesser_300m" 62 "Init_keine_Kurvenanpassung" ;
VAL_ 333 ACC_TA_Kurve_vDelta 11 "Init_keine_Kurvenanpassung" ;
VAL_ 333 RDR_VBEG_Anforderung 0 "INIT" ;
VAL_ 333 ACC_Abbiegewunsch 0 "Init_kein_Abbiegewunsch" 1 "Abbiegewunsch_rechts" 2 "Abbiegewunsch_links" ;
VAL_ 333 ACC_Abbiegewunsch_Abstand 511 "Kein_Abbiegewunsch" ;
VAL_ 333 MPPmod_1_Segment 0 "Keine_Modifikation" 1 "Reset" ;
VAL_ 333 MPPmod_2_Segment 0 "Keine_Modifikation" 1 "Reset" ;
VAL_ 333 MPPmod_3_Segment 0 "Keine_Modifikation" 1 "Reset" ;
VAL_ 333 MPPmod_4_Segment 0 "Keine_Modifikation" 1 "Reset" ;
VAL_ 333 vESC_Verz_Anf 8 "Neutralwert" 9 "Init" 10 "Fehler" ;
VAL_ 333 RDR_v_ueber_Grund 4091 "Init" 4092 "temporaer_nicht_verfuegbar" 4093 "Fehler" ;
VAL_ 333 RDR_v_ueber_Grund_Genauigkeit 61 "groesser_6km_h" 62 "Init" 63 "Fehler" ;
VAL_ 333 RDR_v_ueber_Grund_Fahrtrichtung 0 "vorwaerts" 1 "rueckwaerts" 2 "init_unbekannt" ;
VAL_ 2527679682 ACC_ASM_Ereignis 0 "No_Event" 255 "ASM_Trigger" ;
VAL_ 2527679682 ACC_ASM_Zeitstempel_02 255 "Init" ;
VAL_ 64 AB_RGS_Anst 4 "aktiv_Niveau_1" 5 "aktiv_Niveau_2" 6 "aktiv_Niveau_3" 7 "aktiv_Niveau_4" 8 "deaktiviert" ;
VAL_ 64 AB_Front_Crash 0 "kein_Front_Crash" 1 "Front_Crash" ;
VAL_ 64 AB_Heck_Crash 0 "kein_Heck_Crash" 1 "Heck_Crash" ;
VAL_ 64 AB_SF_Crash 0 "kein_Seiten_Crash_Fahrer" 1 "Seiten_Crash_Fahrer" ;
VAL_ 64 AB_SB_Crash 0 "kein_Seiten_Crash_Beifahrer" 1 "Seiten_Crash_Beifahrer" ;
VAL_ 64 AB_Rollover_Crash 0 "kein_Rollover" 1 "Rollover" ;
VAL_ 64 AB_Crash_Int 0 "kein_Crash" 1 "Crash_Intensitaet_1" 2 "Crash_Intensitaet_2_(nur_Stellgliedtest_MLB_B8)" 3 "Crash_Intensitaet_2_(nur_D4_C7_Colorado_NF_PAG__Crash_im_MLB_B8)" 4 "Crash_Intensitaet_3_(alt_VW/AUDI__Stellgliedtest_MLB_B8)" 5 "Crash_Intensitaet_3_(alt_PAG)" 7 "Crash_Intensitaet_3" ;
VAL_ 64 AB_Lampe 0 "Aus" 1 "Ein" ;
VAL_ 64 AB_Deaktiviert 0 "aktiv" 1 "deaktiviert" ;
VAL_ 64 AB_VB_deaktiviert 0 "Beifahrerairbag_aktiv" 1 "Beifahrerairbag_deaktiviert" ;
VAL_ 64 AB_Systemfehler 0 "kein_Fehler" 1 "Airbag_Systemfehler" ;
VAL_ 64 AB_Diagnose 0 "nicht_in_Diagnose" 1 "in_Diagnose" ;
VAL_ 64 AB_Stellgliedtest 0 "nicht_im_Stellgliedtest" 1 "Airbag_im_Stellgliedtest" ;
VAL_ 64 AB_Erh_Auf_VB 0 "keine_Anzeige" 1 "Beifahrerairbag_deaktiviert" 2 "Beifahrerairbag_aktiviert" 3 "nicht_definiert" ;
VAL_ 64 AB_Gurtwarn_VF 0 "keine_Warnung" 1 "Gurtwarnung_ausloesen" ;
VAL_ 64 AB_Gurtwarn_VB 0 "keine_Warnung" 1 "Gurtwarnung_ausloesen" ;
VAL_ 64 AB_Anzeige_Fussg 0 "keine_FSG_Aktion_ausgeloest" 1 "Motorhaube_offen" 2 "Systemfehler" ;
VAL_ 64 AB_Texte_AKS 0 "keine_AKS_Ausloesung" 1 "AKS_ausgeloest" 2 "AKS_Systemfehler" ;
VAL_ 64 AB_PAO_Leuchte_Anf 0 "Leuchte_ausschalten" 1 "Leuchte_einschalten" ;
VAL_ 64 AB_MKB_gueltig 0 "Multikollisionsbremsung_nicht_freigeschaltet" 1 "Multikollisionsbremsung_freigeschaltet" ;
VAL_ 64 AB_MKB_Anforderung 0 "Multikollisionsbremsung_nicht_angefordert" 1 "Multikollisionsbremsung_angefordert" ;
VAL_ 64 AB_Versorgungsspannung 0 "plausibel" 1 "unplausibel" ;
VAL_ 64 AB_Deaktivierung_HV 0 "keine_Deaktivierung" 1 "Deaktivierung_1" 2 "Deaktivierung_2" 3 "Deaktivierung_3" 4 "Deaktivierung_4" 5 "Deaktivierung_5" 6 "Deaktivierung_6" 7 "Fehler" ;
VAL_ 64 AB_EDR_Trigger 0 "No_Event" 1 "Start_Event" 2 "NonDeployment_Event" 3 "Deployment_Event" ;
VAL_ 64 AB_Belegung_VF 0 "nicht_verfuegbar" 1 "Fehler" 2 "nicht_belegt" 3 "belegt" ;
VAL_ 64 AB_Gurtschloss_FA_ext 0 "nicht_verbaut" 1 "reserviert" 2 "nicht_gesteckt" 3 "gesteckt" 4 "dauerhaft_nicht_gesteckt" 5 "dauerhaft_gesteckt" 6 "Init" 7 "Fehler" ;
VAL_ 64 AB_Gurtschloss_FA_ext_aktiv 0 "inaktiv" 1 "aktiv" ;
VAL_ 64 AB_eCS_Error 0 "keine_Anzeige" 1 "Anzeige_anfordern" ;
VAL_ 64 ASM_Masterzeit_02 255 "Init" ;
VAL_ 2589283873 Airbag_01_CVN_VLD 0 "Ungueltig" 1 "Gueltig" ;
VAL_ 1312 LoGeWa_Event_Kombiwarnung 0 "Init" 1 "Unfall" 2 "Traktionsverlust" 3 "Panne" 4 "Sichtbehinderung" 5 "Aquaplaning" ;
VAL_ 1312 AB_Anforderung_eCall 0 "keine_Anforderung" 1 "Anforderung" ;
VAL_ 1312 AB_Anprall_Seite_Beifahrer 0 "kein_Anprall" 1 "Anprall_erkannt" ;
VAL_ 1312 AB_Anprall_Rollover 0 "kein_Anprall" 1 "Anprall_erkannt" ;
VAL_ 1312 AB_Anprall_FGS 0 "kein_Anprall" 1 "Anprall_erkannt" ;
VAL_ 1312 AB_Anprall_Front_Beifahrer 0 "kein_Anprall" 1 "Anprall_erkannt" ;
VAL_ 1312 AB_Anprall_Front_Fahrer 0 "kein_Anprall" 1 "Anprall_erkannt" ;
VAL_ 1312 AB_Anprall_Heck_Beifahrer 0 "kein_Anprall" 1 "Anprall_erkannt" ;
VAL_ 1312 AB_Anprall_Heck_Fahrer 0 "kein_Anprall" 1 "Anprall_erkannt" ;
VAL_ 1312 AB_Wickelklappung_Reihe2_MI 0 "nicht_verbaut" 1 "nicht_verfuegbar__Fehler_oder_Init" 2 "nicht_verriegelt" 3 "verriegelt" ;
VAL_ 1312 AB_Belegung_VB 0 "nicht_verfuegbar" 1 "Fehler" 2 "nicht_belegt" 3 "belegt" ;
VAL_ 1312 AB_Abschaltanf_SIH_BF 0 "Normalbetrieb" 1 "Abschaltung_angefordert" ;
VAL_ 1312 AB_Anprall_Seite_Fahrer 0 "kein_Anprall" 1 "Anprall_erkannt" ;
VAL_ 1312 SC_PAO_Schriftzug_Anf 0 "LED aus" 1 "LED an" 2 "LED blinken" 3 "reserviert" ;
VAL_ 1312 SC_PAO_ON_Anf 0 "LED aus" 1 "LED an" 2 "LED blinken" 3 "reserviert" ;
VAL_ 1312 SC_PAO_OFF_Anf 0 "LED aus" 1 "LED an" 2 "LED blinken" 3 "reserviert" ;
VAL_ 1312 AB_Crashschwere 0 "kein_Ereignis" 1 "Crashschwere_1" 2 "Crashschwere_2" 3 "Crashschwere_3" 4 "Crashschwere_4" 5 "Crashschwere_5" 6 "Crashschwere_2_bis_5" 7 "Fehler" ;
VAL_ 1312 AB_Anforderung_USM 0 "keine_Anforderung" 1 "Anforderung" ;
VAL_ 1312 AB_Gurtschloss_FA 0 "nicht_verbaut" 1 "nicht_verfügbar (Fehler oder Init)" 2 "nicht_gesteckt" 3 "gesteckt" ;
VAL_ 1312 AB_Gurtschloss_BF 0 "nicht_verbaut" 1 "nicht_verfügbar (Fehler oder Init)" 2 "nicht_gesteckt" 3 "gesteckt" ;
VAL_ 1312 AB_Gurtschloss_Reihe2_FA 0 "nicht_verbaut" 1 "nicht_verfügbar (Fehler oder Init)" 2 "nicht_gesteckt" 3 "gesteckt" ;
VAL_ 1312 AB_Gurtschloss_Reihe2_MI 0 "nicht_verbaut" 1 "nicht_verfügbar (Fehler oder Init)" 2 "nicht_gesteckt" 3 "gesteckt" ;
VAL_ 1312 AB_Gurtschloss_Reihe2_BF 0 "nicht_verbaut" 1 "nicht_verfügbar (Fehler oder Init)" 2 "nicht_gesteckt" 3 "gesteckt" ;
VAL_ 1312 AB_Gurtschloss_Reihe3_FA 0 "nicht_verbaut" 1 "nicht_verfügbar (Fehler oder Init)" 2 "nicht_gesteckt" 3 "gesteckt" ;
VAL_ 1312 AB_Gurtschloss_Reihe3_MI 0 "nicht_verbaut" 1 "nicht_verfügbar (Fehler oder Init)" 2 "nicht_gesteckt" 3 "gesteckt" ;
VAL_ 1312 AB_Gurtschloss_Reihe3_BF 0 "nicht_verbaut" 1 "nicht_verfügbar (Fehler oder Init)" 2 "nicht_gesteckt" 3 "gesteckt" ;
VAL_ 1312 AB_Sitzpos_Sens_FA 0 "nicht verfügbar" 1 "Fehler" 2 "Sitz nicht vorne" 3 "Sitz vorne" ;
VAL_ 1312 AB_Sitzpos_Sens_BF 0 "nicht verfügbar" 1 "Fehler" 2 "Sitz nicht vorne" 3 "Sitz vorne" ;
VAL_ 1312 AB_Wickelklappung_Reihe2_BF 0 "nicht_verbaut" 1 "nicht_verfuegbar__Fehler_oder_Init" 2 "nicht_verriegelt" 3 "verriegelt" ;
VAL_ 1312 AB_Wickelklappung_Reihe2_FA 0 "nicht_verbaut" 1 "nicht_verfuegbar__Fehler_oder_Init" 2 "nicht_verriegelt" 3 "verriegelt" ;
VAL_ 65 AB_DeltaV_X_eCall 0 "Init/no_DeltaV_X_detected" 1 "DeltaV_X_less_than_neg126km/h" 255 "DeltaV_X_larger_than_pos126km/h" ;
VAL_ 65 AB_DeltaV_Y_eCall 0 "Init/no_DeltaV_Y_detected" 1 "DeltaV_Y_less_than_neg126km/h" 255 "DeltaV_Y_larger_than_pos126km/h" ;
VAL_ 65 AB_MKB_Safing 0 "Multikollisionsbremsung_nicht_bestaetigt" 1 "Multikollisionsbremsung_bestaetigt" ;
VAL_ 1349 AB_Anprall_Front 0 "kein_Anprall" 1 "Anprall_erkannt" ;
VAL_ 1349 AB_Anprall_Heck 0 "kein_Anprall" 1 "Anprall_erkannt" ;
VAL_ 1349 AB_Gurtwarn_Reihe4_FA 0 "nicht_verbaut" 1 "keine_Gurtwarnung_Sitz_leer" 2 "keine_Gurtwarnung_Sitz_belegt" 3 "Gurtwarnung_Sitz_belegt" ;
VAL_ 1349 AB_Gurtwarn_Reihe4_BF 0 "nicht_verbaut" 1 "keine_Gurtwarnung_Sitz_leer" 2 "keine_Gurtwarnung_Sitz_belegt" 3 "Gurtwarnung_Sitz_belegt" ;
VAL_ 1349 AB_Gurtwarn_Reihe4_MI 0 "nicht_verbaut" 1 "keine_Gurtwarnung_Sitz_leer" 2 "keine_Gurtwarnung_Sitz_belegt" 3 "Gurtwarnung_Sitz_belegt" ;
VAL_ 1349 AB_Gurtwarn_Reihe2_FA 0 "nicht_verbaut" 1 "keine_Gurtwarnung_Sitz_leer" 2 "keine_Gurtwarnung_Sitz_belegt" 3 "Gurtwarnung_Sitz_belegt" ;
VAL_ 1349 AB_Gurtwarn_Reihe2_BF 0 "nicht_verbaut" 1 "keine_Gurtwarnung_Sitz_leer" 2 "keine_Gurtwarnung_Sitz_belegt" 3 "Gurtwarnung_Sitz_belegt" ;
VAL_ 1349 AbstWarn_MV_FAS_Fkt_Status 0 "Init" 1 "Funktion_Ist_Ein" 2 "Funktion_Ist_Aus" 3 "Fehler" ;
VAL_ 1349 WarnBrems_Charisma_Status 0 "Init" 1 "verfügbar" 2 "nicht verfügbar" 3 "asynchron durch Fahrerwunsch" ;
VAL_ 1349 WarnBrems_Charisma_FahrPr 0 "keine_Funktion" 1 "Programm_1" 2 "Programm_2" 3 "Programm_3" 4 "Programm_4" 5 "Programm_5" 6 "Programm_6" 7 "Programm_7" 8 "Programm_8" 9 "Programm_9" 10 "Programm_10" 11 "Programm_11" 12 "Programm_12" 13 "Programm_13" 14 "Programm_14" 15 "Programm_15" ;
VAL_ 1349 AB_Gurtwarn_Reihe2_MI 0 "nicht_verbaut" 1 "keine_Gurtwarnung_Sitz_leer" 2 "keine_Gurtwarnung_Sitz_belegt" 3 "Gurtwarnung_Sitz_belegt" ;
VAL_ 1349 AB_Gurtwarn_Reihe3_FA 0 "nicht_verbaut" 1 "keine_Gurtwarnung_Sitz_leer" 2 "keine_Gurtwarnung_Sitz_belegt" 3 "Gurtwarnung_Sitz_belegt" ;
VAL_ 1349 AB_Gurtwarn_Reihe3_MI 0 "nicht_verbaut" 1 "keine_Gurtwarnung_Sitz_leer" 2 "keine_Gurtwarnung_Sitz_belegt" 3 "Gurtwarnung_Sitz_belegt" ;
VAL_ 1349 AB_Gurtwarn_Reihe3_BF 0 "nicht_verbaut" 1 "keine_Gurtwarnung_Sitz_leer" 2 "keine_Gurtwarnung_Sitz_belegt" 3 "Gurtwarnung_Sitz_belegt" ;
VAL_ 1349 LGI_FAS_Fkt_Status 0 "Init" 1 "Funktion_Ist_Ein" 2 "Funktion_Ist_Aus" 3 "Fehler" ;
VAL_ 1349 PreCrash_FAS_Fkt_Status 0 "Init" 1 "Funktion_Ist_Ein" 2 "Funktion_Ist_Aus" 3 "Fehler" ;
VAL_ 1349 AB_Belegung_VF_ext 0 "nicht_verbaut" 1 "reserviert" 2 "nicht_belegt" 3 "belegt" 4 "dauerhaft_nicht_belegt" 5 "dauerhaft_belegt" 6 "Init" 7 "Fehler" ;
VAL_ 1349 AB_SBR_hinten_verbau 0 "ohne_SBR_hinten" 1 "mit_SBR_hinten" 2 "nicht_definiert" 3 "Init" ;
VAL_ 1349 AB_Belegung_VF_ext_aktiv 0 "inaktiv" 1 "aktiv" ;
VAL_ 1349 AWV_Einstellung_System_ASG 0 "deaktiviert" 1 "aktiviert" ;
VAL_ 1349 AWV_Einstellung_Warnung_ASG 0 "Aus" 1 "Setting_2" 2 "Setting_3" 3 "Setting_4" 4 "Setting_5" 5 "Ein" ;
VAL_ 1349 SC_PreSense_Modus_Warnung_NV 0 "Aus" 1 "Setting_2" 2 "Setting_3" 3 "Setting_4" 4 "Setting_5" 5 "Ein" ;
VAL_ 1349 SC_PreSense_Modus_Warnung_MV 0 "Aus" 1 "Setting_2" 2 "Setting_3" 3 "Setting_4" 4 "Setting_5" 5 "Ein" ;
VAL_ 1349 SC_PreSense_Modus_System_MV 0 "deaktiviert" 1 "aktiviert" ;
VAL_ 1349 SC_PreSense_Modus_System_NV 0 "deaktiviert" 1 "aktiviert" ;
VAL_ 1349 SC_PreSense_Modus_System_KAS 0 "deaktiviert" 1 "aktiviert" ;
VAL_ 2527679722 AB_Gurtschloss_Reihe4_FA 0 "nicht_verbaut" 1 "nicht_verfügbar (Fehler oder Init)" 2 "nicht_gesteckt" 3 "gesteckt" ;
VAL_ 2527679722 AB_Gurtschloss_Reihe4_BF 0 "nicht_verbaut" 1 "nicht_verfügbar (Fehler oder Init)" 2 "nicht_gesteckt" 3 "gesteckt" ;
VAL_ 2527679722 AB_Gurtschloss_Reihe4_MI 0 "nicht_verbaut" 1 "nicht_verfügbar (Fehler oder Init)" 2 "nicht_gesteckt" 3 "gesteckt" ;
VAL_ 2527679722 AB_wSBR_Batteriestatus 0 "Batterien_OK" 1 "mindestens_eine_Batterie_schwach" ;
VAL_ 2527679722 AB_Gurtwarn_VM 0 "keine_Warnung" 1 "Gurtwarnung_ausloesen" ;
VAL_ 2527679722 AB_Gurtschloss_MI 0 "nicht_verbaut" 1 "nicht_verfügbar (Fehler oder Init)" 2 "nicht_gesteckt" 3 "gesteckt" ;
VAL_ 2527679722 AB_Anzeige_Komfort_HBFS 0 "keine_Statusanzeige" 1 "Anzeige_Lehne_ein" 2 "Anzeige_SNV_ein" 3 "Anzeige_Lehne_UND_SNV_ein" ;
VAL_ 2527679722 AB_Anzeige_Komfort_HFS 0 "keine_Statusanzeige" 1 "Anzeige_Lehne_ein" 2 "Anzeige_SNV_ein" 3 "Anzeige_Lehne_UND_SNV_ein" ;
VAL_ 2527679722 AB_Anzeige_Sitz_Komfort_HBFS 0 "keine_Statusanzeige" 1 "Anzeige_Lehne_ein" 2 "Anzeige_SNV_ein" 3 "Anzeige_Lehne_UND_SNV_ein" ;
VAL_ 2527679722 AB_Anzeige_Sitz_Komfort_HFS 0 "keine_Statusanzeige" 1 "Anzeige_Lehne_ein" 2 "Anzeige_SNV_ein" 3 "Anzeige_Lehne_UND_SNV_ein" ;
VAL_ 2527679722 AB_Status_Sitz_SRAB_HBFS 0 "Einschaltung_SRAB" 1 "Abschaltung_SRAB" 2 "Init" 3 "Fehler" ;
VAL_ 2527679722 AB_Status_Sitz_SRAB_HFS 0 "Einschaltung_SRAB" 1 "Abschaltung_SRAB" 2 "Init" 3 "Fehler" ;
VAL_ 2527679722 AB_Anzeige_Kombi_SRAB 0 "keine_Statusanzeige" 1 "HFS_EIN_HFBS_EIN" 2 "HFS_AUS_HFBS_AUS" 3 "HFS_EIN_HFBS_AUS" 4 "HFS_AUS_HFBS_EIN" ;
VAL_ 63 AB_PAO_off_ANF_Auth 0 "LED aus" 1 "LED an" 2 "LED blinken" 3 "reserviert" ;
VAL_ 63 AB_PAO_on_ANF_Auth 0 "LED aus" 1 "LED an" 2 "LED blinken" 3 "reserviert" ;
VAL_ 63 AB_Crash_Int_Auth 0 "kein_Crash" 1 "Crash_Intensitaet_1" 2 "reserviert" 3 "Crash_Intensitaet_2" 4 "reserviert" 5 "reserviert" 7 "Crash_Intensitaet_3" ;
VAL_ 63 AB_Front_Crash_Auth 0 "kein_Front_Crash" 1 "Front_Crash" ;
VAL_ 63 AB_Heck_Crash_Auth 0 "kein_Heck_Crash" 1 "Heck_Crash" ;
VAL_ 63 AB_SF_Crash_Auth 0 "kein_Seiten_Crash_Fahrer" 1 "Seiten_Crash_Fahrer" ;
VAL_ 63 AB_SB_Crash_Auth 0 "kein_Seiten_Crash_Beifahrer" 1 "Seiten_Crash_Beifahrer" ;
VAL_ 63 AB_Rollover_Crash_Auth 0 "kein_Rollover" 1 "Rollover" ;
VAL_ 63 AB_MKB_Anforderung_Auth 0 "Multikollisionsbremsung_nicht_angefordert" 1 "Multikollisionsbremsung_angefordert" ;
VAL_ 63 AB_MKB_gueltig_Auth 0 "Multikollisionsbremsung_nicht_freigeschaltet" 1 "Multikollisionsbremsung_freigeschaltet" ;
VAL_ 63 AB_VRU_Crash 0 "No_VRU_Crash" 1 "VRU_Crash" ;
VAL_ 63 AB_Anforderung_USM_Auth 0 "keine_Anforderung" 1 "Anforderung" ;
VAL_ 280 ALR_Sta_Laengssperre 0 "Sperre_im_Regelmodus" 1 "Sperre_vom_Fahrer_aktiviert" 2 "Fehler_Sperre_offen" 3 "Fehler_Sperre_zu" ;
VAL_ 280 ALR_Sendestatus 0 "Allrad_sendet_mit_100ms" 1 "Allrad_sendet_mit_10ms" ;
VAL_ 280 ALR_Warnlampe 0 "keine_Warnung" 1 "Warnung" ;
VAL_ 280 ALR_Ist_Proz 253 "Fehler_und_Kupplung_geschlossen" 254 "Init" 255 "Fehler" ;
VAL_ 280 ALR_Charisma_FahrPr 0 "keine_Funktion" 1 "Programm_1" 2 "Programm_2" 3 "Programm_3" 4 "Programm_4" 5 "Programm_5" 6 "Programm_6" 7 "Programm_7" 8 "Programm_8" 9 "Programm_9" 10 "Programm_10" 11 "Programm_11" 12 "Programm_12" 13 "Programm_13" 14 "Programm_14" 15 "Programm_15" ;
VAL_ 280 ALR_Charisma_Status 0 "Init" 1 "verfuegbar" 2 "nicht_verfuegbar" 3 "asynchron_durch_Fahrerwunsch" ;
VAL_ 308 ALR_gMeter_ax 1022 "Init" 1023 "Fehler" ;
VAL_ 308 ALR_gMeter_ay 1022 "Init" 1023 "Fehler" ;
VAL_ 1633 AAG_AVS_Fehler_02_inv 0 "Fehler" 1 "kein_Fehler" ;
VAL_ 1633 AAG_Bremsl_durch_ECD 0 "Bremslicht_ist_aus" 1 "Bremslicht_durch_ECD_aktiv" ;
VAL_ 1633 AAG_Anhaenger_abgesteckt 1 "Anhaenger_wurde_bei_KL15_aus_abgesteckt" ;
VAL_ 1633 AAG_NSL_aktiv 0 "Init" 1 "Anhaenger_Nebelschusslicht_aktiv" ;
VAL_ 1633 AAG_Anhaenger_erkannt 0 "kein_Anhaenger_erkannt" 1 "AAG_Anhaenger_erkannt" ;
VAL_ 1633 AAG_Blinker_H_aktiv 0 "Init" 1 "Anhaenger_Blinker_aktiv" ;
VAL_ 1633 AAG_Blinker_HL_def 0 "Init" 1 "Anhaenger_Blinker_links_defekt" ;
VAL_ 1633 AAG_Blinker_HR_def 0 "Init" 1 "Anhaenger_Blinker_rechts_defekt" ;
VAL_ 1633 AAG_Bremslicht_H_def 0 "Init" 1 "Anhaenger_Bremslicht_defekt" ;
VAL_ 1633 AAG_Schlusslicht_HL_def 0 "Init" 1 "Anhaenger_Schlusslicht_links_defekt" ;
VAL_ 1633 AAG_Schlusslicht_HR_def 0 "Init" 1 "Anhaenger_Schlusslicht_rechts_defekt" ;
VAL_ 1633 AAG_Bremslicht_Reku 0 "inaktiv" 1 "aktiv" ;
VAL_ 1633 AAG_AVS_Fehler_02 0 "kein_Fehler" 1 "Fehler" ;
VAL_ 1633 AAG_LED_aktiv 0 "Lampen" 1 "LED" ;
VAL_ 1633 AAG_AVS_Stati 0 "endlage_eingefahren_erreicht" 1 "endlage_ausgefahren_erreicht" 2 "ausfahren_automatik" 3 "einfahren_automatik" 4 "ausfahren_manuell" 5 "einfahren_manuell" 6 "zwischenposition" 7 "nicht_initialisiert" ;
VAL_ 2527679661 WBA_Warnblinken 0 "kein_Blinken" 1 "Warnblinken" 2 "Warnblinken_Taster" ;
VAL_ 2527679661 AWV_KA_Konfiguration 0 "Ausgeschaltet" 1 "Eingeschaltet" ;
VAL_ 2527679661 AWV_Warnung 0 "keine_Anzeige" 1 "latente_Vorwarnung" 2 "Vorwarnung" 3 "AWU_ohne_Ton_oder_Akutwarnung" 4 "Eingriff" 5 "Fahreruebernahmeaufforderung" 6 "AWU_mit_Ton" 7 "Querinfo_2" ;
VAL_ 2527679661 AWV_Texte_02 0 "keine_Anzeige" 1 "Systemstoerung" 2 "keine_Sensorsicht" 3 "Initialisierung_gelb" 4 "System_aus" 5 "Initialisierung" 6 "Sensorfusion_eingeschraenkt" 7 "zurzeit_eingeschraenkt" ;
VAL_ 2527679661 AWV_Warnlevel 0 "keine_Gefaehrdung" 63 "max_Gefaehrdung" ;
VAL_ 2527679661 AWV_Einstellung_System_FSG 0 "deaktiviert" 1 "aktiviert" ;
VAL_ 2527679661 AWV_Einstellung_Warnung_FSG 0 "Aus" 1 "Setting_2" 2 "Setting_3" 3 "Setting_4" 4 "Setting_5" 5 "Ein" ;
VAL_ 2527679661 AWV_Status_Anzeige 0 "Init" 1 "verfuegbar" 2 "nicht_verfuegbar" ;
VAL_ 2527679661 AWV_LED_Leiste 0 "keine_Anzeige" 1 "Stufe_1_glimmen" 2 "Stufe_2_leuchten" 3 "nicht_definiert" ;
VAL_ 2527679661 AWV_Priowarnung 0 "HCA_Warnung_nicht_unterdruecken" 1 "HCA_Warnung_unterdruecken" ;
VAL_ 2527679661 AWV_AW_Abstand 509 "Freifahrt" 510 "nicht_definiert" 511 "Keine_Anzeige" ;
VAL_ 2527679661 AWV_AW_Zeitluecke 0 "keine_Anzeige" 1 "Zeitluecke_1" 2 "Zeitluecke_2" 3 "Zeitluecke_3" ;
VAL_ 2527679661 AWV_AW_Texte 0 "Keine_Anzeige" 1 "Systemstoerung" 2 "keine_Sensorsicht" 3 "zurzeit_eingeschraenkt" ;
VAL_ 2527679661 AWV_AW_Texte_Zusatzanzeige 0 "keine_Anzeige" 1 "Abstandsanzeige" 2 "AW_Warnschwelle_1" 3 "AW_Warnschwelle_2" 4 "AW_Warnschwelle_3" 5 "AW_Warnung_1" 6 "AW_Warnung_2" 7 "AW_Warnung_3" ;
VAL_ 2527679661 AWV_KA_ObjektFront 0 "kein_Hindernis" 1 "Hindernis_erkannt" ;
VAL_ 2527679661 AWV_Warnung_Richtung 0 "keine_Richtung" 1 "Links" 2 "Mitte" 3 "Rechts" 4 "Links_und_Rechts" ;
VAL_ 2527679661 AWV_Kamera_Objekt_ID 0 "Kein_Kameraobjekt" ;
VAL_ 219 PCF_Freigabe 0 "keine_Freigabe_PreCrashFront" 1 "Freigabe_PreCrashFront" ;
VAL_ 219 SDF_PSF_Objektstatus 0 "kein_relevantes_Obj" 1 "relevantes_Obj_vorausfahrend" 2 "relevantes_Obj_stehend" 3 "relevantes_Obj_angehalten" 4 "relevantes_Obj_entgegenkommend" 5 "relevantes_Obj_querend" 7 "Fehler" ;
VAL_ 219 SDF_PSF_CU_Status 0 "Kollision_vermeidbar" 1 "Kollision_unvermeidbar" ;
VAL_ 219 SDF_PSF_CW 126 "Init" 127 "Fehler" ;
VAL_ 219 SDF_PSF_Fahrer_aktiv 0 "Fahrer_nicht_aktiv" 1 "Fahrer_aktiv" ;
VAL_ 219 SDF_PSF_Guete 0 "Modellguete_niO_keine_Plausi" 1 "Modellguete_niO_plausibilisiert" 2 "Modellguete_iO_keine_Plausi" 3 "Modellguete_iO_plausibilisiert" ;
VAL_ 219 SDF_PSF_Kollisionsueberdeckung 0 "Keine_Ueberdeckung" 29 "Ueberdeckung_groesser_Maximalwert" 30 "Init" 31 "Fehler" ;
VAL_ 219 SDF_PSF_Time_To_Collision 254 "Init" 255 "Fehler" ;
VAL_ 219 SDF_PSF_v_rel 0 "Objektstatus_0" 254 "Init" 255 "Fehler" ;
VAL_ 219 AWV_Eingriff_Sendeart 0 "langsamer_Zyklus" 1 "schneller_Zyklus" ;
VAL_ 219 AWV_Verz_Freigabe 0 "Verzoegerung_nicht_freigeben" 1 "Verzoegerung_freigeben" ;
VAL_ 219 AWV_Verz_Anf 1023 "keine_Anforderung" ;
VAL_ 219 AWV_Anf_Prefill 0 "Keine_Anforderung" 1 "Prefill_aktivieren" ;
VAL_ 219 AWV_Ruckprofil 0 "kein_Ruck" 1 "schwacher_Ruck" 2 "mittlerer_Ruck" 3 "starker_Ruck" ;
VAL_ 219 AWV_Time_to_collision 253 "Wert_groesser_max" 254 "Unbekannt" 255 "Init" ;
VAL_ 219 AWV_HBA_Param 0 "Defaultparametersatz" 1 "leicht_erhoeht" 2 "erhoeht" 3 "hoechst" ;
VAL_ 219 AWV_Verz_Anf_ASIL 0 "QM" 1 "A" 2 "B" 3 "C" ;
VAL_ 219 AWV_Time_to_brake 125 "Wert_groesser_max" 126 "unbekannt" 127 "Init" ;
VAL_ 219 AWV_Zielobjekttyp 0 "Unbekannt" 1 "Fussgaenger" 2 "Zweirad" 3 "PKW" 4 "LKW" 5 "reserviert" 6 "reserviert" 7 "reserviert" 8 "reserviert" 9 "reserviert" 10 "reserviert" 11 "reserviert" 12 "reserviert" 13 "reserviert" 14 "kein_relevantes_Obj" 15 "init" ;
VAL_ 219 AWV_QFK_KruemmSoll_VZ 0 "positiv" 1 "negativ" ;
VAL_ 219 AWV_QFK_AnfStat 1 "Init" 2 "Bereit" 4 "Eingriff" ;
VAL_ 219 AWV_Fahrerbremswunsch_erf 0 "erforderlich" 1 "nicht_erforderlich" ;
VAL_ 219 AWV_Timestamp_TTC 8191 "Init" ;
VAL_ 219 AWV_QFK_KrSoll_VZ 0 "positiv" 1 "negativ" ;
VAL_ 219 AWV_QFK_KrSoll 65535 "Init" ;
VAL_ 219 AWV_Status_AWU 0 "Off" 1 "On_but_not_intervening" 2 "On_actively_intervening" 3 "Faulted" 4 "Reserved04" 5 "Reserved05" 6 "Reserved06" 7 "Reserved07" 8 "Reserved08" 9 "Reserved09" 10 "Reserved10" 11 "Reserved11" 12 "Reserved12" 13 "Reserved13" 14 "Invalid_data" 15 "Data_not_available" ;
VAL_ 1626 BCM_Bremsbelag_Sensor 0 "OK" 1 "Bremsbelag_unter_min" ;
VAL_ 1626 BCM_Bremsfluessigkeit_Sensor 0 "OK" 1 "Bremsfluessigkeit_unter_min" ;
VAL_ 1626 BCM1_Licht_Warn 0 "OK" 1 "Lichtwarnung_aktiv" ;
VAL_ 1626 BCM_Waschwasser_Sensor 0 "OK" 1 "Waschwasser_unter_min" ;
VAL_ 1626 BCM_Kuehlmittel_Sensor 0 "OK" 1 "Kuehlmittel_unter_min" ;
VAL_ 1626 BCM1_Kl_15_HW_erkannt 1 "Klemme 15 erkannt" ;
VAL_ 1626 BCM1_Kl_15_Sig_HW_erkannt 0 "KL15_HW_Signal_von_BCM1_nicht_erkannt" 1 "KL15_HW_Signal_von_BCM1_erkannt" ;
VAL_ 1626 BCM_Kuehlmittel_Sensor_02 0 "OK" 1 "Kuehlmittel_unter_min" ;
VAL_ 1626 BCM1_Hinweis_Lichtnachlauf 0 "inaktiv" 1 "aktiv" ;
VAL_ 1626 BCM_Offroad_Taste 0 "Taster_nicht_betaetigt" 1 "Taster_betaetigt" ;
VAL_ 1626 BCM_Charisma_Taste2 0 "nicht_betaetigt" 1 "betaetigt" ;
VAL_ 1626 BCM_Hybrid_StSt_Taste_Fehler 0 "kein_Fehler_StSt_Taster" 1 "Fehler_StSt_Taster" ;
VAL_ 1626 BCM_Hybrid_StartStopp_Taste 0 "nicht_betaetigt" 1 "betaetigt" ;
VAL_ 1626 BCM1_Warnblink_Taster 0 "nicht_betaetigt" 1 "betaetigt" ;
VAL_ 1626 BCM1_Valet_Parking_Taster 0 "nicht_betaetigt" 1 "betaetigt" ;
VAL_ 1626 BCM1_LDS_Stellung 0 "Init" 1 "Stellung_0" 2 "Auto" 3 "Standlicht" 4 "Abblendlicht" 7 "Fehler" ;
VAL_ 1626 BCM1_Rueckfahrlicht_Schalter 0 "nicht_betaetigt" 1 "betaetigt" ;
VAL_ 1626 BCM1_MH_Schalter 0 "MH_geschlossen" 1 "MH_offen" ;
VAL_ 1626 BCM1_MH_WIV_Schalter 0 "MH_geschlossen" 1 "MH_offen" ;
VAL_ 1626 BCM_Eco_Charisma_Taste 0 "nicht_betaetigt" 1 "betaetigt" ;
VAL_ 1626 BCM1_NV_Taster 0 "Taster_nicht_betaetigt" 1 "Taster_betaetigt" ;
VAL_ 1626 BCM1_AFS_Lampe 0 "Aus" 1 "Ein" ;
VAL_ 1626 BCM1_Reisemodus_Texte 0 "keine_Anzeige" 1 "Umschaltung_auf_Linksverkehr_aktiv" 2 "Umschaltung_auf_Rechtsverkehr_aktiv" ;
VAL_ 1626 BCM1_Lichtwarn_Texte 0 "keine_Warnung" 1 "Standlichtwarnung" 2 "Parklichtwarnung" 3 "Nebelschlusslichtwarnung" ;
VAL_ 1626 Gong_TFL_Umschaltung 0 "kein_Gong" 1 "Gong_einmalig" ;
VAL_ 1626 BCM_ValetTaster_Fkts_LED 0 "LED_aus" 1 "LED_ein" ;
VAL_ 1626 LRH_Taster 0 "nicht_betaetigt" 1 "betaetigt" ;
VAL_ 1626 APS_Tongeber_defekt 0 "iO" 1 "defekt" ;
VAL_ 1626 BCM1_EasyEntry_Status 0 "Aus" 1 "Ein" ;
VAL_ 1626 BCM1_Lenksaeule_aktiv 0 "Lenksaeulenverstellung nicht aktiv" 1 "Lenksaeulenverstellung aktiv" ;
VAL_ 1626 BCM1_Spannungs_Anf 0 "keine_Anforderung" 1 "Anforderung_Stufe_1" 2 "Anforderung_Stufe_2" 3 "Anforderung_Stufe_3" ;
VAL_ 1626 DWA_Alarmquelle 0 "kein_Ausloesegrund" 1 "Tuerkontakt_Fahrertuer" 2 "Tuerkontakt_Beifahrertuer" 3 "Tuerkontakt_hinten_links" 4 "Tuerkontakt_hinten_rechts" 5 "Motorhaubenkontakt_vorne" 6 "Kofferraum_hinten" 7 "Masseschleife_der_Heckscheibe" 8 "Innenraumueberwachung" 9 "Alarm_durch_Noteinstieg" 10 "Sounder" 11 "Neigungssensor" 12 "TSG_FT_am_CAN_Bus" 13 "TSG_BT_am_CAN_Bus" 14 "TSG_HFS_am_CAN_Bus" 15 "TSG_HBFS_am_CAN_Bus" 16 "Klemme_15" 17 "Klemme_15sig" 18 "frei" 19 "Anhaengerueberwachung" 20 "Scheinwerferueberwachung_links" 21 "Scheinwerferueberwachung_rechts" 22 "Handschuhkasten" 23 "Verdeckueberwachung" 24 "OBD_Alarm" 25 "Power_on_Reset" 30 "Init" 31 "Fehler" ;
VAL_ 1626 DWA_Einschraenkung 0 "Init" 1 "Fehler" ;
VAL_ 1626 BCM_HBFS_EOE_aktiv 0 "EOE_inaktiv" 1 "EOE_aktiv" ;
VAL_ 1626 BCM_HFS_EOE_aktiv 0 "EOE_inaktiv" 1 "EOE_aktiv" ;
VAL_ 1626 BCM_Anf_AAW_MoLaWa 0 "Init" 1 "AAW_angefordert" 2 "MoLaWa_angefordert" ;
VAL_ 1626 BCM_Handbremse_Hinweis 0 "inaktiv" 1 "aktiv" ;
VAL_ 1626 BCM_Waehlhebel_P_Hinweis 0 "inaktiv" 1 "aktiv" ;
VAL_ 1626 BCM1_Fahrlicht_Hinweis 0 "kein_Fahrlicht_Hinweis" 1 "Fahrlicht_Hinweis" ;
VAL_ 1626 BCM_HDF_betaetigt 0 "nicht_betaetigt" 1 "betaetigt" ;
VAL_ 2527679939 BDM_Kommunikationsbasis_2 0 "Lithium" 1 "Blei" ;
VAL_ 2527679939 BDM_Kuehlung_Anf 0 "Anforderung_Kuehlung" 1 "keine_Anforderung" ;
VAL_ 2527679939 BDM_I_U_VorgabeZwang_2 0 "Wunschvorgabe" 1 "Zwangsvorgabe" ;
VAL_ 2527679939 BDM_TE_Diagnose_2 0 "TE_in_Ordnung" 1 "TE_nicht_in_Ordnung" ;
VAL_ 2527679939 BDM_TE_Status_2 0 "geschlossen" 1 "TE_Vorwarnung_oder_Status_offen" ;
VAL_ 2527679939 BDM_ZellStatus_Index_2 0 "Zelle_Nr_1" 1 "Zelle_Nr_2" 2 "Zelle_Nr_3" 3 "Zelle_Nr_4" 4 "Zelle_Nr_5" 5 "Zelle_Nr_6" 6 "Zelle_Nr_7" 7 "Zelle_Nr_8" 8 "Zelle_Nr_9" 9 "Zelle_Nr_10" 10 "Zelle_Nr_11" 11 "Zelle_Nr_12" 12 "Zelle_Nr_13" 13 "Zelle_Nr_14" 14 "Zelle_Nr_15" 15 "Zelle_Nr_16" ;
VAL_ 2527679939 BDM_ZellStatus_Typ_2 0 "Init" 1 "Spannung" 2 "Temperatur" 3 "Spannungsgrenzen" 4 "SoF" 5 "SoH_C" 6 "reserviert" 7 "reserviert" ;
VAL_ 2527679939 BDM_ZellTechnologie_2 0 "Lithium_Eisenphosphat" 1 "Lithium_Titanat" 15 "unbekannt" ;
VAL_ 2527679939 BZE_ZwangGrund 0 "kein_Zwang" 1 "Under_voltage" 2 "Over_temperature" 3 "Over_voltage" ;
VAL_ 2527679939 BZE_Qe_Bereich_2 0 "Bereich_4Ah_per_Digit" 1 "Bereich_1Ah_per_digit" ;
VAL_ 2527679939 BDM_LiIon_Status_2 0 "Kein_Serviceeintrag_notwendig" 1 "Tauschempf_aufg_SOH_oder_SOF" 2 "BMS_Sensorik_unplausibel" 3 "Batterie_tiefentladen" 4 "BMS_defekt" 5 "Schmelzsicherung_defekt" ;
VAL_ 2527679939 BDM_LiIon_Zellenanzahl_2 0 "Keine_Zellen_separat_diagn" ;
VAL_ 2527679939 BZE_Q_FuSi 126 "Init" 127 "Fehler" ;
VAL_ 2527679939 BZE_SOF_3Pol 0 "SOF_i_O" 1 "SOF_n_i_O" ;
VAL_ 2527679939 BDM_Variante 0 "Zwei_Pol_Batterie_Blei_Immer" 1 "Drei_Pol_Batterie" 2 "tbd" 3 "tbd" ;
VAL_ 869 BEM_UBDM 0 "Init" 255 "Fehler" ;
VAL_ 869 NVEM_Ladefreigabe 0 "kein_Freigabe" 1 "Freigabe_Stufe_1" 2 "Freigabe_Stufe_2" 3 "Uneingeschraenkte_Freigabe" ;
VAL_ 869 NVEM_FMAus_Info 0 "Motorlauf_langfristig_nicht_notwendig_FMAus_Freigabe" 1 "Motoranlauf_nicht_zwingend_notwendig_Stoppverbot_keine_Startanforderung" 2 "Motoranlauf_zwingend_notwendig_Startanforderung" 3 "Systemfehler" ;
VAL_ 869 NVEM_PTC_Sollstufe 0 "Aus" 1 "Stufe_1" 2 "Stufe_2" 3 "Stufe_3" ;
VAL_ 869 NVEM_P_Generator_Status 0 "gefiltert" 1 "ungefiltert" ;
VAL_ 869 BEM_P_Generator 255 "Fehler" ;
VAL_ 869 BEM_n_LLA 0 "keine_Erhoehung" 1 "Stufe_1" 2 "Stufe_2" 3 "Stufe_3" ;
VAL_ 869 NVEM_Abschaltstufe 0 "Stufe_0_keine_Einschraenkung" 1 "Stufe_1" 2 "Stufe_2" 3 "Stufe_3" ;
VAL_ 869 BEM_Anf_KL 0 "keine Anforderung" 1 "Anforderung Kühlerlüfter Ansteuerung" ;
VAL_ 869 BEM_StartStopp_Info 0 "Motorlauf_nicht_notwendig_(Stoppfreigabe)" 1 "Motoranlauf_nicht_zwingend_notwendig_(Stoppverbot,keine_Startanforderung)" 2 "Motoranlauf_zwingend_notwendig_(Startanforderung)" 3 "Systemfehler" ;
VAL_ 869 BEM_EMLIN_ungueltig 0 "Signale_gueltig" 1 "Signale_ungueltig" ;
VAL_ 869 BEM_Batt_Ab 0 "verbunden" 1 "nicht_verbunden" ;
VAL_ 869 NVEM_FMAus_I_Verbrauch 30 "Init" 31 "Fehler" ;
VAL_ 869 NVEM_Freilauf_Info 0 "Freilauf_freigegeben" 1 "Weiches_Veto_uebertippbar" 2 "Hartes_Veto_Abbruch" 3 "Freilauf_Anforderung" ;
VAL_ 869 NVEM_Red_KL 0 "Init" 1 "Abschaltung_KL" 2 "Reduzierung_KL" ;
VAL_ 869 BEM_Segel_Info 0 "keine_Anforderung" 1 "Mindestdrehzahl_1" 2 "Mindestdrehzahl_2" 3 "Segelveto" ;
VAL_ 869 BEM_HYB_DC_uMinLV 254 "Init" 255 "Fehler" ;
VAL_ 1163 NVEM_Betriebsart 0 "oKl15_Sing_oVerbr" 1 "oKl15_Red_RedKontingent_oVerbr" 2 "oKl15_Red_HohKontingent_oVerbr" 3 "oKl15_Red_mVerbr" 4 "reserved" 5 "reserved" 6 "reserved" 7 "reserved" 8 "mKl15_Sing_oVerbr" 9 "mKl15_Red_RedKontingent_oVerbr" 10 "mKl15_Red_HohKontingent_oVerbr" 11 "mKl15_Red_mVerbr" 12 "Fahrbereitschaft_mVerbr" 13 "reserved" 14 "reserved" 15 "Fehler" ;
VAL_ 1163 NVEM_Ladezustand 126 "INIT" 127 "Fehler" ;
VAL_ 1163 NVEM2_Status_FuSiFahrt 0 "Init" 1 "Keine_FuSi_Fahrt" 2 "Qualifikation_FuSi_Fahrt" 3 "FuSi_Fahrt_Aktiv" 4 "Qualifikation_Ende_FuSi_Fahrt" 5 "FuSi_Stand" 6 "FuSi_Nachlauf" 7 "Fehler" ;
VAL_ 1163 NVEM_Energienetz_Status 0 "QM" 1 "ASIL_A" 2 "ASIL_B" 3 "ASIL_C" 6 "InitWert" 7 "Fehler" ;
VAL_ 1163 NVEM_Vorgabe_Leistungsstufe 0 "Init" 1 "Leistungsstufe_0" 2 "Leistungsstufe_1" 3 "Leistungsstufe_2" 4 "Leistungsstufe_3" 5 "Leistungsstufe_4" 6 "Leistungsstufe_5" 7 "Fehler" ;
VAL_ 1163 NVEM2_Typ_EnergieNetz 0 "Sp12V_Gen_ICE" 1 "Sp12V_BEV" 2 "Sp12V_PHEV" 3 "Sp12V_MHEV" 4 "Sp12V_HEV" 5 "Sp12V_Sp48V_Gen_Insel" 6 "Sp12V_Sp12V_RSG_MHEV12V" 7 "Sp12V_BEV_ASILC" 14 "Fehler" 15 "Init" ;
VAL_ 1163 NVEM_Energie_Klima_Vorgabe 254 "Init" 255 "Fehler" ;
VAL_ 1163 NVEM_Last_Anf 0 "keine Anforderung" 1 "Verbraucher_Anforderung_Stufe_1" 2 "Verbraucher_Anforderung_Stufe_2" 3 "Verbraucher_Anforderung_Stufe_3" ;
VAL_ 1163 NVEM_STH_ZielzeitLang 14 "Init" 15 "Fehler" ;
VAL_ 1163 NVEM_Red_KomfortVerbrauch 0 "keine_Einschraenkung" 1 "Einschraenkung_Stufe_1" 2 "Einschraenkung_Stufe_2" 3 "Einschraenkung_Stufe_3" 4 "Einschraenkung_Stufe_4" 5 "Einschraenkung_Stufe_5" 6 "Einschraenkung_Stufe_6" 7 "Einschraenkung_Stufe_7" 8 "Einschraenkung_Stufe_8" 15 "Fehler" ;
VAL_ 1163 NVEM_PTC_Sollstufe 0 "Aus" 1 "Stufe_1" 2 "Stufe_2" 3 "Stufe_3" ;
VAL_ 1163 NVEM_Bordnetzdiagnose 0 "kein_Fehler" 1 "Warnung_1" 2 "Warnung_2" 3 "Warnung_3" ;
VAL_ 1163 HLR_PTC_linear_Freigabe 63 "Fehler" ;
